VERSION ""

NS_ :

BS_:
BU_: FLR_L FRR_L mADC

BO_ 669 FRR_L_29D: 64 FRR_L
 SG_ FLR_CRCCheck_29D : 503|16@0+ (1.0000000000,0.0000000000) [0.0000000000|65535.0000000000] ""  FLR_L,mADC
 SG_ FLR_RollingCounter_29D : 491|4@0+ (1.0000000000,0.0000000000) [0.0000000000|15.0000000000] ""  FLR_L,mADC
 SG_ FLR_FreespaceSectorKinestate136 : 477|2@0+ (1.0000000000,0.0000000000) [0.0000000000|3.0000000000] "-"  FLR_L,mADC
 SG_ FLR_FreespaceSectorConfidence136 : 479|2@0+ (1.0000000000,0.0000000000) [0.0000000000|3.0000000000] "-"  FLR_L,mADC
 SG_ FLR_FreespaceSectorDistance136 : 457|10@0+ (0.1000000000,0.0000000000) [0.0000000000|100.0000000000] "-"  FLR_L,mADC
 SG_ FLR_FreespaceSectorKinestate135 : 459|2@0+ (1.0000000000,0.0000000000) [0.0000000000|3.0000000000] "-"  FLR_L,mADC
 SG_ FLR_FreespaceSectorConfidence135 : 461|2@0+ (1.0000000000,0.0000000000) [0.0000000000|3.0000000000] "-"  FLR_L,mADC
 SG_ FLR_FreespaceSectorDistance135 : 455|10@0+ (0.1000000000,0.0000000000) [0.0000000000|100.0000000000] "-"  FLR_L,mADC
 SG_ FLR_FreespaceSectorKinestate134 : 441|2@0+ (1.0000000000,0.0000000000) [0.0000000000|3.0000000000] "-"  FLR_L,mADC
 SG_ FLR_FreespaceSectorConfidence134 : 443|2@0+ (1.0000000000,0.0000000000) [0.0000000000|3.0000000000] "-"  FLR_L,mADC
 SG_ FLR_FreespaceSectorDistance134 : 437|10@0+ (0.1000000000,0.0000000000) [0.0000000000|100.0000000000] "-"  FLR_L,mADC
 SG_ FLR_FreespaceSectorKinestate133 : 439|2@0+ (1.0000000000,0.0000000000) [0.0000000000|3.0000000000] "-"  FLR_L,mADC
 SG_ FLR_FreespaceSectorConfidence133 : 425|2@0+ (1.0000000000,0.0000000000) [0.0000000000|3.0000000000] "-"  FLR_L,mADC
 SG_ FLR_FreespaceSectorDistance133 : 419|10@0+ (0.1000000000,0.0000000000) [0.0000000000|100.0000000000] "-"  FLR_L,mADC
 SG_ FLR_FreespaceSectorKinestate132 : 421|2@0+ (1.0000000000,0.0000000000) [0.0000000000|3.0000000000] "-"  FLR_L,mADC
 SG_ FLR_FreespaceSectorConfidence132 : 423|2@0+ (1.0000000000,0.0000000000) [0.0000000000|3.0000000000] "-"  FLR_L,mADC
 SG_ FLR_FreespaceSectorDistance132 : 401|10@0+ (0.1000000000,0.0000000000) [0.0000000000|100.0000000000] "-"  FLR_L,mADC
 SG_ FLR_FreespaceSectorKinestate131 : 403|2@0+ (1.0000000000,0.0000000000) [0.0000000000|3.0000000000] "-"  FLR_L,mADC
 SG_ FLR_FreespaceSectorConfidence131 : 405|2@0+ (1.0000000000,0.0000000000) [0.0000000000|3.0000000000] "-"  FLR_L,mADC
 SG_ FLR_FreespaceSectorDistance131 : 399|10@0+ (0.1000000000,0.0000000000) [0.0000000000|100.0000000000] "-"  FLR_L,mADC
 SG_ FLR_FreespaceSectorKinestate130 : 385|2@0+ (1.0000000000,0.0000000000) [0.0000000000|3.0000000000] "-"  FLR_L,mADC
 SG_ FLR_FreespaceSectorConfidence130 : 387|2@0+ (1.0000000000,0.0000000000) [0.0000000000|3.0000000000] "-"  FLR_L,mADC
 SG_ FLR_FreespaceSectorDistance130 : 381|10@0+ (0.1000000000,0.0000000000) [0.0000000000|100.0000000000] "-"  FLR_L,mADC
 SG_ FLR_FreespaceSectorKinestate129 : 383|2@0+ (1.0000000000,0.0000000000) [0.0000000000|3.0000000000] "-"  FLR_L,mADC
 SG_ FLR_FreespaceSectorConfidence129 : 369|2@0+ (1.0000000000,0.0000000000) [0.0000000000|3.0000000000] "-"  FLR_L,mADC
 SG_ FLR_FreespaceSectorDistance129 : 363|10@0+ (0.1000000000,0.0000000000) [0.0000000000|100.0000000000] "-"  FLR_L,mADC
 SG_ FLR_FreespaceSectorKinestate128 : 365|2@0+ (1.0000000000,0.0000000000) [0.0000000000|3.0000000000] "-"  FLR_L,mADC
 SG_ FLR_FreespaceSectorConfidence128 : 367|2@0+ (1.0000000000,0.0000000000) [0.0000000000|3.0000000000] "-"  FLR_L,mADC
 SG_ FLR_FreespaceSectorDistance128 : 345|10@0+ (0.1000000000,0.0000000000) [0.0000000000|100.0000000000] "-"  FLR_L,mADC
 SG_ FLR_FreespaceSectorKinestate127 : 347|2@0+ (1.0000000000,0.0000000000) [0.0000000000|3.0000000000] "-"  FLR_L,mADC
 SG_ FLR_FreespaceSectorConfidence127 : 349|2@0+ (1.0000000000,0.0000000000) [0.0000000000|3.0000000000] "-"  FLR_L,mADC
 SG_ FLR_FreespaceSectorDistance127 : 343|10@0+ (0.1000000000,0.0000000000) [0.0000000000|100.0000000000] "-"  FLR_L,mADC
 SG_ FLR_FreespaceSectorKinestate126 : 329|2@0+ (1.0000000000,0.0000000000) [0.0000000000|3.0000000000] "-"  FLR_L,mADC
 SG_ FLR_FreespaceSectorConfidence126 : 331|2@0+ (1.0000000000,0.0000000000) [0.0000000000|3.0000000000] "-"  FLR_L,mADC
 SG_ FLR_FreespaceSectorDistance126 : 325|10@0+ (0.1000000000,0.0000000000) [0.0000000000|100.0000000000] "-"  FLR_L,mADC
 SG_ FLR_FreespaceSectorKinestate125 : 327|2@0+ (1.0000000000,0.0000000000) [0.0000000000|3.0000000000] "-"  FLR_L,mADC
 SG_ FLR_FreespaceSectorConfidence125 : 313|2@0+ (1.0000000000,0.0000000000) [0.0000000000|3.0000000000] "-"  FLR_L,mADC
 SG_ FLR_FreespaceSectorDistance125 : 307|10@0+ (0.1000000000,0.0000000000) [0.0000000000|100.0000000000] "-"  FLR_L,mADC
 SG_ FLR_FreespaceSectorKinestate124 : 309|2@0+ (1.0000000000,0.0000000000) [0.0000000000|3.0000000000] "-"  FLR_L,mADC
 SG_ FLR_FreespaceSectorConfidence124 : 311|2@0+ (1.0000000000,0.0000000000) [0.0000000000|3.0000000000] "-"  FLR_L,mADC
 SG_ FLR_FreespaceSectorDistance124 : 289|10@0+ (0.1000000000,0.0000000000) [0.0000000000|100.0000000000] "-"  FLR_L,mADC
 SG_ FLR_FreespaceSectorKinestate123 : 291|2@0+ (1.0000000000,0.0000000000) [0.0000000000|3.0000000000] "-"  FLR_L,mADC
 SG_ FLR_FreespaceSectorConfidence123 : 293|2@0+ (1.0000000000,0.0000000000) [0.0000000000|3.0000000000] "-"  FLR_L,mADC
 SG_ FLR_FreespaceSectorDistance123 : 287|10@0+ (0.1000000000,0.0000000000) [0.0000000000|100.0000000000] "-"  FLR_L,mADC
 SG_ FLR_FreespaceSectorKinestate122 : 273|2@0+ (1.0000000000,0.0000000000) [0.0000000000|3.0000000000] "-"  FLR_L,mADC
 SG_ FLR_FreespaceSectorConfidence122 : 275|2@0+ (1.0000000000,0.0000000000) [0.0000000000|3.0000000000] "-"  FLR_L,mADC
 SG_ FLR_FreespaceSectorDistance122 : 269|10@0+ (0.1000000000,0.0000000000) [0.0000000000|100.0000000000] "-"  FLR_L,mADC
 SG_ FLR_FreespaceSectorKinestate121 : 271|2@0+ (1.0000000000,0.0000000000) [0.0000000000|3.0000000000] "-"  FLR_L,mADC
 SG_ FLR_FreespaceSectorConfidence121 : 257|2@0+ (1.0000000000,0.0000000000) [0.0000000000|3.0000000000] "-"  FLR_L,mADC
 SG_ FLR_FreespaceSectorDistance121 : 251|10@0+ (0.1000000000,0.0000000000) [0.0000000000|100.0000000000] "-"  FLR_L,mADC
 SG_ FLR_FreespaceSectorKinestate120 : 253|2@0+ (1.0000000000,0.0000000000) [0.0000000000|3.0000000000] "-"  FLR_L,mADC
 SG_ FLR_FreespaceSectorConfidence120 : 255|2@0+ (1.0000000000,0.0000000000) [0.0000000000|3.0000000000] "-"  FLR_L,mADC
 SG_ FLR_FreespaceSectorDistance120 : 233|10@0+ (0.1000000000,0.0000000000) [0.0000000000|100.0000000000] "-"  FLR_L,mADC
 SG_ FLR_FreespaceSectorKinestate119 : 235|2@0+ (1.0000000000,0.0000000000) [0.0000000000|3.0000000000] "-"  FLR_L,mADC
 SG_ FLR_FreespaceSectorConfidence119 : 237|2@0+ (1.0000000000,0.0000000000) [0.0000000000|3.0000000000] "-"  FLR_L,mADC
 SG_ FLR_FreespaceSectorDistance119 : 231|10@0+ (0.1000000000,0.0000000000) [0.0000000000|100.0000000000] "-"  FLR_L,mADC
 SG_ FLR_FreespaceSectorKinestate118 : 217|2@0+ (1.0000000000,0.0000000000) [0.0000000000|3.0000000000] "-"  FLR_L,mADC
 SG_ FLR_FreespaceSectorConfidence118 : 219|2@0+ (1.0000000000,0.0000000000) [0.0000000000|3.0000000000] "-"  FLR_L,mADC
 SG_ FLR_FreespaceSectorDistance118 : 213|10@0+ (0.1000000000,0.0000000000) [0.0000000000|100.0000000000] "-"  FLR_L,mADC
 SG_ FLR_FreespaceSectorKinestate117 : 215|2@0+ (1.0000000000,0.0000000000) [0.0000000000|3.0000000000] "-"  FLR_L,mADC
 SG_ FLR_FreespaceSectorConfidence117 : 201|2@0+ (1.0000000000,0.0000000000) [0.0000000000|3.0000000000] "-"  FLR_L,mADC
 SG_ FLR_FreespaceSectorDistance117 : 195|10@0+ (0.1000000000,0.0000000000) [0.0000000000|100.0000000000] "-"  FLR_L,mADC
 SG_ FLR_FreespaceSectorKinestate116 : 197|2@0+ (1.0000000000,0.0000000000) [0.0000000000|3.0000000000] "-"  FLR_L,mADC
 SG_ FLR_FreespaceSectorConfidence116 : 199|2@0+ (1.0000000000,0.0000000000) [0.0000000000|3.0000000000] "-"  FLR_L,mADC
 SG_ FLR_FreespaceSectorDistance116 : 177|10@0+ (0.1000000000,0.0000000000) [0.0000000000|100.0000000000] "-"  FLR_L,mADC
 SG_ FLR_FreespaceSectorKinestate115 : 179|2@0+ (1.0000000000,0.0000000000) [0.0000000000|3.0000000000] "-"  FLR_L,mADC
 SG_ FLR_FreespaceSectorConfidence115 : 181|2@0+ (1.0000000000,0.0000000000) [0.0000000000|3.0000000000] "-"  FLR_L,mADC
 SG_ FLR_FreespaceSectorDistance115 : 175|10@0+ (0.1000000000,0.0000000000) [0.0000000000|100.0000000000] "-"  FLR_L,mADC
 SG_ FLR_FreespaceSectorKinestate114 : 161|2@0+ (1.0000000000,0.0000000000) [0.0000000000|3.0000000000] "-"  FLR_L,mADC
 SG_ FLR_FreespaceSectorConfidence114 : 163|2@0+ (1.0000000000,0.0000000000) [0.0000000000|3.0000000000] "-"  FLR_L,mADC
 SG_ FLR_FreespaceSectorDistance114 : 157|10@0+ (0.1000000000,0.0000000000) [0.0000000000|100.0000000000] "-"  FLR_L,mADC
 SG_ FLR_FreespaceSectorKinestate113 : 159|2@0+ (1.0000000000,0.0000000000) [0.0000000000|3.0000000000] "-"  FLR_L,mADC
 SG_ FLR_FreespaceSectorConfidence113 : 145|2@0+ (1.0000000000,0.0000000000) [0.0000000000|3.0000000000] "-"  FLR_L,mADC
 SG_ FLR_FreespaceSectorDistance113 : 139|10@0+ (0.1000000000,0.0000000000) [0.0000000000|100.0000000000] "-"  FLR_L,mADC
 SG_ FLR_FreespaceSectorKinestate112 : 141|2@0+ (1.0000000000,0.0000000000) [0.0000000000|3.0000000000] "-"  FLR_L,mADC
 SG_ FLR_FreespaceSectorConfidence112 : 143|2@0+ (1.0000000000,0.0000000000) [0.0000000000|3.0000000000] "-"  FLR_L,mADC
 SG_ FLR_FreespaceSectorDistance112 : 121|10@0+ (0.1000000000,0.0000000000) [0.0000000000|100.0000000000] "-"  FLR_L,mADC
 SG_ FLR_FreespaceSectorKinestate111 : 123|2@0+ (1.0000000000,0.0000000000) [0.0000000000|3.0000000000] "-"  FLR_L,mADC
 SG_ FLR_FreespaceSectorConfidence111 : 125|2@0+ (1.0000000000,0.0000000000) [0.0000000000|3.0000000000] "-"  FLR_L,mADC
 SG_ FLR_FreespaceSectorDistance111 : 119|10@0+ (0.1000000000,0.0000000000) [0.0000000000|100.0000000000] "-"  FLR_L,mADC
 SG_ FLR_FreespaceSectorKinestate110 : 105|2@0+ (1.0000000000,0.0000000000) [0.0000000000|3.0000000000] "-"  FLR_L,mADC
 SG_ FLR_FreespaceSectorConfidence110 : 107|2@0+ (1.0000000000,0.0000000000) [0.0000000000|3.0000000000] "-"  FLR_L,mADC
 SG_ FLR_FreespaceSectorDistance110 : 101|10@0+ (0.1000000000,0.0000000000) [0.0000000000|100.0000000000] "-"  FLR_L,mADC
 SG_ FLR_FreespaceSectorKinestate109 : 103|2@0+ (1.0000000000,0.0000000000) [0.0000000000|3.0000000000] "-"  FLR_L,mADC
 SG_ FLR_FreespaceSectorConfidence109 : 89|2@0+ (1.0000000000,0.0000000000) [0.0000000000|3.0000000000] "-"  FLR_L,mADC
 SG_ FLR_FreespaceSectorDistance109 : 83|10@0+ (0.1000000000,0.0000000000) [0.0000000000|100.0000000000] "-"  FLR_L,mADC
 SG_ FLR_FreespaceSectorKinestate108 : 85|2@0+ (1.0000000000,0.0000000000) [0.0000000000|3.0000000000] "-"  FLR_L,mADC
 SG_ FLR_FreespaceSectorConfidence108 : 87|2@0+ (1.0000000000,0.0000000000) [0.0000000000|3.0000000000] "-"  FLR_L,mADC
 SG_ FLR_FreespaceSectorDistance108 : 65|10@0+ (0.1000000000,0.0000000000) [0.0000000000|100.0000000000] "-"  FLR_L,mADC
 SG_ FLR_FreespaceSectorKinestate107 : 67|2@0+ (1.0000000000,0.0000000000) [0.0000000000|3.0000000000] "-"  FLR_L,mADC
 SG_ FLR_FreespaceSectorConfidence107 : 69|2@0+ (1.0000000000,0.0000000000) [0.0000000000|3.0000000000] "-"  FLR_L,mADC
 SG_ FLR_FreespaceSectorDistance107 : 63|10@0+ (0.1000000000,0.0000000000) [0.0000000000|100.0000000000] "-"  FLR_L,mADC
 SG_ FLR_FreespaceSectorKinestate106 : 49|2@0+ (1.0000000000,0.0000000000) [0.0000000000|3.0000000000] "-"  FLR_L,mADC
 SG_ FLR_FreespaceSectorConfidence106 : 51|2@0+ (1.0000000000,0.0000000000) [0.0000000000|3.0000000000] "-"  FLR_L,mADC
 SG_ FLR_FreespaceSectorDistance106 : 45|10@0+ (0.1000000000,0.0000000000) [0.0000000000|100.0000000000] "-"  FLR_L,mADC
 SG_ FLR_FreespaceSectorKinestate105 : 47|2@0+ (1.0000000000,0.0000000000) [0.0000000000|3.0000000000] "-"  FLR_L,mADC
 SG_ FLR_FreespaceSectorConfidence105 : 33|2@0+ (1.0000000000,0.0000000000) [0.0000000000|3.0000000000] "-"  FLR_L,mADC
 SG_ FLR_FreespaceSectorDistance105 : 27|10@0+ (0.1000000000,0.0000000000) [0.0000000000|100.0000000000] "-"  FLR_L,mADC
 SG_ FLR_FreespaceSectorKinestate104 : 29|2@0+ (1.0000000000,0.0000000000) [0.0000000000|3.0000000000] "-"  FLR_L,mADC
 SG_ FLR_FreespaceSectorConfidence104 : 31|2@0+ (1.0000000000,0.0000000000) [0.0000000000|3.0000000000] "-"  FLR_L,mADC
 SG_ FLR_FreespaceSectorDistance104 : 9|10@0+ (0.1000000000,0.0000000000) [0.0000000000|100.0000000000] "-"  FLR_L,mADC
 SG_ FLR_FreespaceSectorKinestate103 : 11|2@0+ (1.0000000000,0.0000000000) [0.0000000000|3.0000000000] "-"  FLR_L,mADC
 SG_ FLR_FreespaceSectorConfidence103 : 13|2@0+ (1.0000000000,0.0000000000) [0.0000000000|3.0000000000] "-"  FLR_L,mADC
 SG_ FLR_FreespaceSectorDistance103 : 7|10@0+ (0.1000000000,0.0000000000) [0.0000000000|100.0000000000] "-"  FLR_L,mADC

BO_ 670 FRR_L_29E: 64 FRR_L
 SG_ FLR_CRCCheck_29E : 503|16@0+ (1.0000000000,0.0000000000) [0.0000000000|65535.0000000000] ""  FLR_L,mADC
 SG_ FLR_RollingCounter_29E : 491|4@0+ (1.0000000000,0.0000000000) [0.0000000000|15.0000000000] ""  FLR_L,mADC
 SG_ FLR_FreespaceSectorKinestate170 : 477|2@0+ (1.0000000000,0.0000000000) [0.0000000000|3.0000000000] "-"  FLR_L,mADC
 SG_ FLR_FreespaceSectorConfidence170 : 479|2@0+ (1.0000000000,0.0000000000) [0.0000000000|3.0000000000] "-"  FLR_L,mADC
 SG_ FLR_FreespaceSectorDistance170 : 457|10@0+ (0.1000000000,0.0000000000) [0.0000000000|100.0000000000] "-"  FLR_L,mADC
 SG_ FLR_FreespaceSectorKinestate169 : 459|2@0+ (1.0000000000,0.0000000000) [0.0000000000|3.0000000000] "-"  FLR_L,mADC
 SG_ FLR_FreespaceSectorConfidence169 : 461|2@0+ (1.0000000000,0.0000000000) [0.0000000000|3.0000000000] "-"  FLR_L,mADC
 SG_ FLR_FreespaceSectorDistance169 : 455|10@0+ (0.1000000000,0.0000000000) [0.0000000000|100.0000000000] "-"  FLR_L,mADC
 SG_ FLR_FreespaceSectorKinestate168 : 441|2@0+ (1.0000000000,0.0000000000) [0.0000000000|3.0000000000] "-"  FLR_L,mADC
 SG_ FLR_FreespaceSectorConfidence168 : 443|2@0+ (1.0000000000,0.0000000000) [0.0000000000|3.0000000000] "-"  FLR_L,mADC
 SG_ FLR_FreespaceSectorDistance168 : 437|10@0+ (0.1000000000,0.0000000000) [0.0000000000|100.0000000000] "-"  FLR_L,mADC
 SG_ FLR_FreespaceSectorKinestate167 : 439|2@0+ (1.0000000000,0.0000000000) [0.0000000000|3.0000000000] "-"  FLR_L,mADC
 SG_ FLR_FreespaceSectorConfidence167 : 425|2@0+ (1.0000000000,0.0000000000) [0.0000000000|3.0000000000] "-"  FLR_L,mADC
 SG_ FLR_FreespaceSectorDistance167 : 419|10@0+ (0.1000000000,0.0000000000) [0.0000000000|100.0000000000] "-"  FLR_L,mADC
 SG_ FLR_FreespaceSectorKinestate166 : 421|2@0+ (1.0000000000,0.0000000000) [0.0000000000|3.0000000000] "-"  FLR_L,mADC
 SG_ FLR_FreespaceSectorConfidence166 : 423|2@0+ (1.0000000000,0.0000000000) [0.0000000000|3.0000000000] "-"  FLR_L,mADC
 SG_ FLR_FreespaceSectorDistance166 : 401|10@0+ (0.1000000000,0.0000000000) [0.0000000000|100.0000000000] "-"  FLR_L,mADC
 SG_ FLR_FreespaceSectorKinestate165 : 403|2@0+ (1.0000000000,0.0000000000) [0.0000000000|3.0000000000] "-"  FLR_L,mADC
 SG_ FLR_FreespaceSectorConfidence165 : 405|2@0+ (1.0000000000,0.0000000000) [0.0000000000|3.0000000000] "-"  FLR_L,mADC
 SG_ FLR_FreespaceSectorDistance165 : 399|10@0+ (0.1000000000,0.0000000000) [0.0000000000|100.0000000000] "-"  FLR_L,mADC
 SG_ FLR_FreespaceSectorKinestate164 : 385|2@0+ (1.0000000000,0.0000000000) [0.0000000000|3.0000000000] "-"  FLR_L,mADC
 SG_ FLR_FreespaceSectorConfidence164 : 387|2@0+ (1.0000000000,0.0000000000) [0.0000000000|3.0000000000] "-"  FLR_L,mADC
 SG_ FLR_FreespaceSectorDistance164 : 381|10@0+ (0.1000000000,0.0000000000) [0.0000000000|100.0000000000] "-"  FLR_L,mADC
 SG_ FLR_FreespaceSectorKinestate163 : 383|2@0+ (1.0000000000,0.0000000000) [0.0000000000|3.0000000000] "-"  FLR_L,mADC
 SG_ FLR_FreespaceSectorConfidence163 : 369|2@0+ (1.0000000000,0.0000000000) [0.0000000000|3.0000000000] "-"  FLR_L,mADC
 SG_ FLR_FreespaceSectorDistance163 : 363|10@0+ (0.1000000000,0.0000000000) [0.0000000000|100.0000000000] "-"  FLR_L,mADC
 SG_ FLR_FreespaceSectorKinestate162 : 365|2@0+ (1.0000000000,0.0000000000) [0.0000000000|3.0000000000] "-"  FLR_L,mADC
 SG_ FLR_FreespaceSectorConfidence162 : 367|2@0+ (1.0000000000,0.0000000000) [0.0000000000|3.0000000000] "-"  FLR_L,mADC
 SG_ FLR_FreespaceSectorDistance162 : 345|10@0+ (0.1000000000,0.0000000000) [0.0000000000|100.0000000000] "-"  FLR_L,mADC
 SG_ FLR_FreespaceSectorKinestate161 : 347|2@0+ (1.0000000000,0.0000000000) [0.0000000000|3.0000000000] "-"  FLR_L,mADC
 SG_ FLR_FreespaceSectorConfidence161 : 349|2@0+ (1.0000000000,0.0000000000) [0.0000000000|3.0000000000] "-"  FLR_L,mADC
 SG_ FLR_FreespaceSectorDistance161 : 343|10@0+ (0.1000000000,0.0000000000) [0.0000000000|100.0000000000] "-"  FLR_L,mADC
 SG_ FLR_FreespaceSectorKinestate160 : 329|2@0+ (1.0000000000,0.0000000000) [0.0000000000|3.0000000000] "-"  FLR_L,mADC
 SG_ FLR_FreespaceSectorConfidence160 : 331|2@0+ (1.0000000000,0.0000000000) [0.0000000000|3.0000000000] "-"  FLR_L,mADC
 SG_ FLR_FreespaceSectorDistance160 : 325|10@0+ (0.1000000000,0.0000000000) [0.0000000000|100.0000000000] "-"  FLR_L,mADC
 SG_ FLR_FreespaceSectorKinestate159 : 327|2@0+ (1.0000000000,0.0000000000) [0.0000000000|3.0000000000] "-"  FLR_L,mADC
 SG_ FLR_FreespaceSectorConfidence159 : 313|2@0+ (1.0000000000,0.0000000000) [0.0000000000|3.0000000000] "-"  FLR_L,mADC
 SG_ FLR_FreespaceSectorDistance159 : 307|10@0+ (0.1000000000,0.0000000000) [0.0000000000|100.0000000000] "-"  FLR_L,mADC
 SG_ FLR_FreespaceSectorKinestate158 : 309|2@0+ (1.0000000000,0.0000000000) [0.0000000000|3.0000000000] "-"  FLR_L,mADC
 SG_ FLR_FreespaceSectorConfidence158 : 311|2@0+ (1.0000000000,0.0000000000) [0.0000000000|3.0000000000] "-"  FLR_L,mADC
 SG_ FLR_FreespaceSectorDistance158 : 289|10@0+ (0.1000000000,0.0000000000) [0.0000000000|100.0000000000] "-"  FLR_L,mADC
 SG_ FLR_FreespaceSectorKinestate157 : 291|2@0+ (1.0000000000,0.0000000000) [0.0000000000|3.0000000000] "-"  FLR_L,mADC
 SG_ FLR_FreespaceSectorConfidence157 : 293|2@0+ (1.0000000000,0.0000000000) [0.0000000000|3.0000000000] "-"  FLR_L,mADC
 SG_ FLR_FreespaceSectorDistance157 : 287|10@0+ (0.1000000000,0.0000000000) [0.0000000000|100.0000000000] "-"  FLR_L,mADC
 SG_ FLR_FreespaceSectorKinestate156 : 273|2@0+ (1.0000000000,0.0000000000) [0.0000000000|3.0000000000] "-"  FLR_L,mADC
 SG_ FLR_FreespaceSectorConfidence156 : 275|2@0+ (1.0000000000,0.0000000000) [0.0000000000|3.0000000000] "-"  FLR_L,mADC
 SG_ FLR_FreespaceSectorDistance156 : 269|10@0+ (0.1000000000,0.0000000000) [0.0000000000|100.0000000000] "-"  FLR_L,mADC
 SG_ FLR_FreespaceSectorKinestate155 : 271|2@0+ (1.0000000000,0.0000000000) [0.0000000000|3.0000000000] "-"  FLR_L,mADC
 SG_ FLR_FreespaceSectorConfidence155 : 257|2@0+ (1.0000000000,0.0000000000) [0.0000000000|3.0000000000] "-"  FLR_L,mADC
 SG_ FLR_FreespaceSectorDistance155 : 251|10@0+ (0.1000000000,0.0000000000) [0.0000000000|100.0000000000] "-"  FLR_L,mADC
 SG_ FLR_FreespaceSectorKinestate154 : 253|2@0+ (1.0000000000,0.0000000000) [0.0000000000|3.0000000000] "-"  FLR_L,mADC
 SG_ FLR_FreespaceSectorConfidence154 : 255|2@0+ (1.0000000000,0.0000000000) [0.0000000000|3.0000000000] "-"  FLR_L,mADC
 SG_ FLR_FreespaceSectorDistance154 : 233|10@0+ (0.1000000000,0.0000000000) [0.0000000000|100.0000000000] "-"  FLR_L,mADC
 SG_ FLR_FreespaceSectorKinestate153 : 235|2@0+ (1.0000000000,0.0000000000) [0.0000000000|3.0000000000] "-"  FLR_L,mADC
 SG_ FLR_FreespaceSectorConfidence153 : 237|2@0+ (1.0000000000,0.0000000000) [0.0000000000|3.0000000000] "-"  FLR_L,mADC
 SG_ FLR_FreespaceSectorDistance153 : 231|10@0+ (0.1000000000,0.0000000000) [0.0000000000|100.0000000000] "-"  FLR_L,mADC
 SG_ FLR_FreespaceSectorKinestate152 : 217|2@0+ (1.0000000000,0.0000000000) [0.0000000000|3.0000000000] "-"  FLR_L,mADC
 SG_ FLR_FreespaceSectorConfidence152 : 219|2@0+ (1.0000000000,0.0000000000) [0.0000000000|3.0000000000] "-"  FLR_L,mADC
 SG_ FLR_FreespaceSectorDistance152 : 213|10@0+ (0.1000000000,0.0000000000) [0.0000000000|100.0000000000] "-"  FLR_L,mADC
 SG_ FLR_FreespaceSectorKinestate151 : 215|2@0+ (1.0000000000,0.0000000000) [0.0000000000|3.0000000000] "-"  FLR_L,mADC
 SG_ FLR_FreespaceSectorConfidence151 : 201|2@0+ (1.0000000000,0.0000000000) [0.0000000000|3.0000000000] "-"  FLR_L,mADC
 SG_ FLR_FreespaceSectorDistance151 : 195|10@0+ (0.1000000000,0.0000000000) [0.0000000000|100.0000000000] "-"  FLR_L,mADC
 SG_ FLR_FreespaceSectorKinestate150 : 197|2@0+ (1.0000000000,0.0000000000) [0.0000000000|3.0000000000] "-"  FLR_L,mADC
 SG_ FLR_FreespaceSectorConfidence150 : 199|2@0+ (1.0000000000,0.0000000000) [0.0000000000|3.0000000000] "-"  FLR_L,mADC
 SG_ FLR_FreespaceSectorDistance150 : 177|10@0+ (0.1000000000,0.0000000000) [0.0000000000|100.0000000000] "-"  FLR_L,mADC
 SG_ FLR_FreespaceSectorKinestate149 : 179|2@0+ (1.0000000000,0.0000000000) [0.0000000000|3.0000000000] "-"  FLR_L,mADC
 SG_ FLR_FreespaceSectorConfidence149 : 181|2@0+ (1.0000000000,0.0000000000) [0.0000000000|3.0000000000] "-"  FLR_L,mADC
 SG_ FLR_FreespaceSectorDistance149 : 175|10@0+ (0.1000000000,0.0000000000) [0.0000000000|100.0000000000] "-"  FLR_L,mADC
 SG_ FLR_FreespaceSectorKinestate148 : 161|2@0+ (1.0000000000,0.0000000000) [0.0000000000|3.0000000000] "-"  FLR_L,mADC
 SG_ FLR_FreespaceSectorConfidence148 : 163|2@0+ (1.0000000000,0.0000000000) [0.0000000000|3.0000000000] "-"  FLR_L,mADC
 SG_ FLR_FreespaceSectorDistance148 : 157|10@0+ (0.1000000000,0.0000000000) [0.0000000000|100.0000000000] "-"  FLR_L,mADC
 SG_ FLR_FreespaceSectorKinestate147 : 159|2@0+ (1.0000000000,0.0000000000) [0.0000000000|3.0000000000] "-"  FLR_L,mADC
 SG_ FLR_FreespaceSectorConfidence147 : 145|2@0+ (1.0000000000,0.0000000000) [0.0000000000|3.0000000000] "-"  FLR_L,mADC
 SG_ FLR_FreespaceSectorDistance147 : 139|10@0+ (0.1000000000,0.0000000000) [0.0000000000|100.0000000000] "-"  FLR_L,mADC
 SG_ FLR_FreespaceSectorKinestate146 : 141|2@0+ (1.0000000000,0.0000000000) [0.0000000000|3.0000000000] "-"  FLR_L,mADC
 SG_ FLR_FreespaceSectorConfidence146 : 143|2@0+ (1.0000000000,0.0000000000) [0.0000000000|3.0000000000] "-"  FLR_L,mADC
 SG_ FLR_FreespaceSectorDistance146 : 121|10@0+ (0.1000000000,0.0000000000) [0.0000000000|100.0000000000] "-"  FLR_L,mADC
 SG_ FLR_FreespaceSectorKinestate145 : 123|2@0+ (1.0000000000,0.0000000000) [0.0000000000|3.0000000000] "-"  FLR_L,mADC
 SG_ FLR_FreespaceSectorConfidence145 : 125|2@0+ (1.0000000000,0.0000000000) [0.0000000000|3.0000000000] "-"  FLR_L,mADC
 SG_ FLR_FreespaceSectorDistance145 : 119|10@0+ (0.1000000000,0.0000000000) [0.0000000000|100.0000000000] "-"  FLR_L,mADC
 SG_ FLR_FreespaceSectorKinestate144 : 105|2@0+ (1.0000000000,0.0000000000) [0.0000000000|3.0000000000] "-"  FLR_L,mADC
 SG_ FLR_FreespaceSectorConfidence144 : 107|2@0+ (1.0000000000,0.0000000000) [0.0000000000|3.0000000000] "-"  FLR_L,mADC
 SG_ FLR_FreespaceSectorDistance144 : 101|10@0+ (0.1000000000,0.0000000000) [0.0000000000|100.0000000000] "-"  FLR_L,mADC
 SG_ FLR_FreespaceSectorKinestate143 : 103|2@0+ (1.0000000000,0.0000000000) [0.0000000000|3.0000000000] "-"  FLR_L,mADC
 SG_ FLR_FreespaceSectorConfidence143 : 89|2@0+ (1.0000000000,0.0000000000) [0.0000000000|3.0000000000] "-"  FLR_L,mADC
 SG_ FLR_FreespaceSectorDistance143 : 83|10@0+ (0.1000000000,0.0000000000) [0.0000000000|100.0000000000] "-"  FLR_L,mADC
 SG_ FLR_FreespaceSectorKinestate142 : 85|2@0+ (1.0000000000,0.0000000000) [0.0000000000|3.0000000000] "-"  FLR_L,mADC
 SG_ FLR_FreespaceSectorConfidence142 : 87|2@0+ (1.0000000000,0.0000000000) [0.0000000000|3.0000000000] "-"  FLR_L,mADC
 SG_ FLR_FreespaceSectorDistance142 : 65|10@0+ (0.1000000000,0.0000000000) [0.0000000000|100.0000000000] "-"  FLR_L,mADC
 SG_ FLR_FreespaceSectorKinestate141 : 67|2@0+ (1.0000000000,0.0000000000) [0.0000000000|3.0000000000] "-"  FLR_L,mADC
 SG_ FLR_FreespaceSectorConfidence141 : 69|2@0+ (1.0000000000,0.0000000000) [0.0000000000|3.0000000000] "-"  FLR_L,mADC
 SG_ FLR_FreespaceSectorDistance141 : 63|10@0+ (0.1000000000,0.0000000000) [0.0000000000|100.0000000000] "-"  FLR_L,mADC
 SG_ FLR_FreespaceSectorKinestate140 : 49|2@0+ (1.0000000000,0.0000000000) [0.0000000000|3.0000000000] "-"  FLR_L,mADC
 SG_ FLR_FreespaceSectorConfidence140 : 51|2@0+ (1.0000000000,0.0000000000) [0.0000000000|3.0000000000] "-"  FLR_L,mADC
 SG_ FLR_FreespaceSectorDistance140 : 45|10@0+ (0.1000000000,0.0000000000) [0.0000000000|100.0000000000] "-"  FLR_L,mADC
 SG_ FLR_FreespaceSectorKinestate139 : 47|2@0+ (1.0000000000,0.0000000000) [0.0000000000|3.0000000000] "-"  FLR_L,mADC
 SG_ FLR_FreespaceSectorConfidence139 : 33|2@0+ (1.0000000000,0.0000000000) [0.0000000000|3.0000000000] "-"  FLR_L,mADC
 SG_ FLR_FreespaceSectorDistance139 : 27|10@0+ (0.1000000000,0.0000000000) [0.0000000000|100.0000000000] "-"  FLR_L,mADC
 SG_ FLR_FreespaceSectorKinestate138 : 29|2@0+ (1.0000000000,0.0000000000) [0.0000000000|3.0000000000] "-"  FLR_L,mADC
 SG_ FLR_FreespaceSectorConfidence138 : 31|2@0+ (1.0000000000,0.0000000000) [0.0000000000|3.0000000000] "-"  FLR_L,mADC
 SG_ FLR_FreespaceSectorDistance138 : 9|10@0+ (0.1000000000,0.0000000000) [0.0000000000|100.0000000000] "-"  FLR_L,mADC
 SG_ FLR_FreespaceSectorKinestate137 : 11|2@0+ (1.0000000000,0.0000000000) [0.0000000000|3.0000000000] "-"  FLR_L,mADC
 SG_ FLR_FreespaceSectorConfidence137 : 13|2@0+ (1.0000000000,0.0000000000) [0.0000000000|3.0000000000] "-"  FLR_L,mADC
 SG_ FLR_FreespaceSectorDistance137 : 7|10@0+ (0.1000000000,0.0000000000) [0.0000000000|100.0000000000] "-"  FLR_L,mADC

BO_ 671 FRR_L_29F: 64 FRR_L
 SG_ FLR_CRCCheck_29F : 503|16@0+ (1.0000000000,0.0000000000) [0.0000000000|65535.0000000000] ""  FLR_L,mADC
 SG_ FLR_RollingCounter_29F : 491|4@0+ (1.0000000000,0.0000000000) [0.0000000000|15.0000000000] ""  FLR_L,mADC
 SG_ FLR_FreespaceSectorKinestate204 : 477|2@0+ (1.0000000000,0.0000000000) [0.0000000000|3.0000000000] "-"  FLR_L,mADC
 SG_ FLR_FreespaceSectorConfidence204 : 479|2@0+ (1.0000000000,0.0000000000) [0.0000000000|3.0000000000] "-"  FLR_L,mADC
 SG_ FLR_FreespaceSectorDistance204 : 457|10@0+ (0.1000000000,0.0000000000) [0.0000000000|100.0000000000] "-"  FLR_L,mADC
 SG_ FLR_FreespaceSectorKinestate203 : 459|2@0+ (1.0000000000,0.0000000000) [0.0000000000|3.0000000000] "-"  FLR_L,mADC
 SG_ FLR_FreespaceSectorConfidence203 : 461|2@0+ (1.0000000000,0.0000000000) [0.0000000000|3.0000000000] "-"  FLR_L,mADC
 SG_ FLR_FreespaceSectorDistance203 : 455|10@0+ (0.1000000000,0.0000000000) [0.0000000000|100.0000000000] "-"  FLR_L,mADC
 SG_ FLR_FreespaceSectorKinestate202 : 441|2@0+ (1.0000000000,0.0000000000) [0.0000000000|3.0000000000] "-"  FLR_L,mADC
 SG_ FLR_FreespaceSectorConfidence202 : 443|2@0+ (1.0000000000,0.0000000000) [0.0000000000|3.0000000000] "-"  FLR_L,mADC
 SG_ FLR_FreespaceSectorDistance202 : 437|10@0+ (0.1000000000,0.0000000000) [0.0000000000|100.0000000000] "-"  FLR_L,mADC
 SG_ FLR_FreespaceSectorKinestate201 : 439|2@0+ (1.0000000000,0.0000000000) [0.0000000000|3.0000000000] "-"  FLR_L,mADC
 SG_ FLR_FreespaceSectorConfidence201 : 425|2@0+ (1.0000000000,0.0000000000) [0.0000000000|3.0000000000] "-"  FLR_L,mADC
 SG_ FLR_FreespaceSectorDistance201 : 419|10@0+ (0.1000000000,0.0000000000) [0.0000000000|100.0000000000] "-"  FLR_L,mADC
 SG_ FLR_FreespaceSectorKinestate200 : 421|2@0+ (1.0000000000,0.0000000000) [0.0000000000|3.0000000000] "-"  FLR_L,mADC
 SG_ FLR_FreespaceSectorConfidence200 : 423|2@0+ (1.0000000000,0.0000000000) [0.0000000000|3.0000000000] "-"  FLR_L,mADC
 SG_ FLR_FreespaceSectorDistance200 : 401|10@0+ (0.1000000000,0.0000000000) [0.0000000000|100.0000000000] "-"  FLR_L,mADC
 SG_ FLR_FreespaceSectorKinestate199 : 403|2@0+ (1.0000000000,0.0000000000) [0.0000000000|3.0000000000] "-"  FLR_L,mADC
 SG_ FLR_FreespaceSectorConfidence199 : 405|2@0+ (1.0000000000,0.0000000000) [0.0000000000|3.0000000000] "-"  FLR_L,mADC
 SG_ FLR_FreespaceSectorDistance199 : 399|10@0+ (0.1000000000,0.0000000000) [0.0000000000|100.0000000000] "-"  FLR_L,mADC
 SG_ FLR_FreespaceSectorKinestate198 : 385|2@0+ (1.0000000000,0.0000000000) [0.0000000000|3.0000000000] "-"  FLR_L,mADC
 SG_ FLR_FreespaceSectorConfidence198 : 387|2@0+ (1.0000000000,0.0000000000) [0.0000000000|3.0000000000] "-"  FLR_L,mADC
 SG_ FLR_FreespaceSectorDistance198 : 381|10@0+ (0.1000000000,0.0000000000) [0.0000000000|100.0000000000] "-"  FLR_L,mADC
 SG_ FLR_FreespaceSectorKinestate197 : 383|2@0+ (1.0000000000,0.0000000000) [0.0000000000|3.0000000000] "-"  FLR_L,mADC
 SG_ FLR_FreespaceSectorConfidence197 : 369|2@0+ (1.0000000000,0.0000000000) [0.0000000000|3.0000000000] "-"  FLR_L,mADC
 SG_ FLR_FreespaceSectorDistance197 : 363|10@0+ (0.1000000000,0.0000000000) [0.0000000000|100.0000000000] "-"  FLR_L,mADC
 SG_ FLR_FreespaceSectorKinestate196 : 365|2@0+ (1.0000000000,0.0000000000) [0.0000000000|3.0000000000] "-"  FLR_L,mADC
 SG_ FLR_FreespaceSectorConfidence196 : 367|2@0+ (1.0000000000,0.0000000000) [0.0000000000|3.0000000000] "-"  FLR_L,mADC
 SG_ FLR_FreespaceSectorDistance196 : 345|10@0+ (0.1000000000,0.0000000000) [0.0000000000|100.0000000000] "-"  FLR_L,mADC
 SG_ FLR_FreespaceSectorKinestate195 : 347|2@0+ (1.0000000000,0.0000000000) [0.0000000000|3.0000000000] "-"  FLR_L,mADC
 SG_ FLR_FreespaceSectorConfidence195 : 349|2@0+ (1.0000000000,0.0000000000) [0.0000000000|3.0000000000] "-"  FLR_L,mADC
 SG_ FLR_FreespaceSectorDistance195 : 343|10@0+ (0.1000000000,0.0000000000) [0.0000000000|100.0000000000] "-"  FLR_L,mADC
 SG_ FLR_FreespaceSectorKinestate194 : 329|2@0+ (1.0000000000,0.0000000000) [0.0000000000|3.0000000000] "-"  FLR_L,mADC
 SG_ FLR_FreespaceSectorConfidence194 : 331|2@0+ (1.0000000000,0.0000000000) [0.0000000000|3.0000000000] "-"  FLR_L,mADC
 SG_ FLR_FreespaceSectorDistance194 : 325|10@0+ (0.1000000000,0.0000000000) [0.0000000000|100.0000000000] "-"  FLR_L,mADC
 SG_ FLR_FreespaceSectorKinestate193 : 327|2@0+ (1.0000000000,0.0000000000) [0.0000000000|3.0000000000] "-"  FLR_L,mADC
 SG_ FLR_FreespaceSectorConfidence193 : 313|2@0+ (1.0000000000,0.0000000000) [0.0000000000|3.0000000000] "-"  FLR_L,mADC
 SG_ FLR_FreespaceSectorDistance193 : 307|10@0+ (0.1000000000,0.0000000000) [0.0000000000|100.0000000000] "-"  FLR_L,mADC
 SG_ FLR_FreespaceSectorKinestate192 : 309|2@0+ (1.0000000000,0.0000000000) [0.0000000000|3.0000000000] "-"  FLR_L,mADC
 SG_ FLR_FreespaceSectorConfidence192 : 311|2@0+ (1.0000000000,0.0000000000) [0.0000000000|3.0000000000] "-"  FLR_L,mADC
 SG_ FLR_FreespaceSectorDistance192 : 289|10@0+ (0.1000000000,0.0000000000) [0.0000000000|100.0000000000] "-"  FLR_L,mADC
 SG_ FLR_FreespaceSectorKinestate191 : 291|2@0+ (1.0000000000,0.0000000000) [0.0000000000|3.0000000000] "-"  FLR_L,mADC
 SG_ FLR_FreespaceSectorConfidence191 : 293|2@0+ (1.0000000000,0.0000000000) [0.0000000000|3.0000000000] "-"  FLR_L,mADC
 SG_ FLR_FreespaceSectorDistance191 : 287|10@0+ (0.1000000000,0.0000000000) [0.0000000000|100.0000000000] "-"  FLR_L,mADC
 SG_ FLR_FreespaceSectorKinestate190 : 273|2@0+ (1.0000000000,0.0000000000) [0.0000000000|3.0000000000] "-"  FLR_L,mADC
 SG_ FLR_FreespaceSectorConfidence190 : 275|2@0+ (1.0000000000,0.0000000000) [0.0000000000|3.0000000000] "-"  FLR_L,mADC
 SG_ FLR_FreespaceSectorDistance190 : 269|10@0+ (0.1000000000,0.0000000000) [0.0000000000|100.0000000000] "-"  FLR_L,mADC
 SG_ FLR_FreespaceSectorKinestate189 : 271|2@0+ (1.0000000000,0.0000000000) [0.0000000000|3.0000000000] "-"  FLR_L,mADC
 SG_ FLR_FreespaceSectorConfidence189 : 257|2@0+ (1.0000000000,0.0000000000) [0.0000000000|3.0000000000] "-"  FLR_L,mADC
 SG_ FLR_FreespaceSectorDistance189 : 251|10@0+ (0.1000000000,0.0000000000) [0.0000000000|100.0000000000] "-"  FLR_L,mADC
 SG_ FLR_FreespaceSectorKinestate188 : 253|2@0+ (1.0000000000,0.0000000000) [0.0000000000|3.0000000000] "-"  FLR_L,mADC
 SG_ FLR_FreespaceSectorConfidence188 : 255|2@0+ (1.0000000000,0.0000000000) [0.0000000000|3.0000000000] "-"  FLR_L,mADC
 SG_ FLR_FreespaceSectorDistance188 : 233|10@0+ (0.1000000000,0.0000000000) [0.0000000000|100.0000000000] "-"  FLR_L,mADC
 SG_ FLR_FreespaceSectorKinestate187 : 235|2@0+ (1.0000000000,0.0000000000) [0.0000000000|3.0000000000] "-"  FLR_L,mADC
 SG_ FLR_FreespaceSectorConfidence187 : 237|2@0+ (1.0000000000,0.0000000000) [0.0000000000|3.0000000000] "-"  FLR_L,mADC
 SG_ FLR_FreespaceSectorDistance187 : 231|10@0+ (0.1000000000,0.0000000000) [0.0000000000|100.0000000000] "-"  FLR_L,mADC
 SG_ FLR_FreespaceSectorKinestate186 : 217|2@0+ (1.0000000000,0.0000000000) [0.0000000000|3.0000000000] "-"  FLR_L,mADC
 SG_ FLR_FreespaceSectorConfidence186 : 219|2@0+ (1.0000000000,0.0000000000) [0.0000000000|3.0000000000] "-"  FLR_L,mADC
 SG_ FLR_FreespaceSectorDistance186 : 213|10@0+ (0.1000000000,0.0000000000) [0.0000000000|100.0000000000] "-"  FLR_L,mADC
 SG_ FLR_FreespaceSectorKinestate185 : 215|2@0+ (1.0000000000,0.0000000000) [0.0000000000|3.0000000000] "-"  FLR_L,mADC
 SG_ FLR_FreespaceSectorConfidence185 : 201|2@0+ (1.0000000000,0.0000000000) [0.0000000000|3.0000000000] "-"  FLR_L,mADC
 SG_ FLR_FreespaceSectorDistance185 : 195|10@0+ (0.1000000000,0.0000000000) [0.0000000000|100.0000000000] "-"  FLR_L,mADC
 SG_ FLR_FreespaceSectorKinestate184 : 197|2@0+ (1.0000000000,0.0000000000) [0.0000000000|3.0000000000] "-"  FLR_L,mADC
 SG_ FLR_FreespaceSectorConfidence184 : 199|2@0+ (1.0000000000,0.0000000000) [0.0000000000|3.0000000000] "-"  FLR_L,mADC
 SG_ FLR_FreespaceSectorDistance184 : 177|10@0+ (0.1000000000,0.0000000000) [0.0000000000|100.0000000000] "-"  FLR_L,mADC
 SG_ FLR_FreespaceSectorKinestate183 : 179|2@0+ (1.0000000000,0.0000000000) [0.0000000000|3.0000000000] "-"  FLR_L,mADC
 SG_ FLR_FreespaceSectorConfidence183 : 181|2@0+ (1.0000000000,0.0000000000) [0.0000000000|3.0000000000] "-"  FLR_L,mADC
 SG_ FLR_FreespaceSectorDistance183 : 175|10@0+ (0.1000000000,0.0000000000) [0.0000000000|100.0000000000] "-"  FLR_L,mADC
 SG_ FLR_FreespaceSectorKinestate182 : 161|2@0+ (1.0000000000,0.0000000000) [0.0000000000|3.0000000000] "-"  FLR_L,mADC
 SG_ FLR_FreespaceSectorConfidence182 : 163|2@0+ (1.0000000000,0.0000000000) [0.0000000000|3.0000000000] "-"  FLR_L,mADC
 SG_ FLR_FreespaceSectorDistance182 : 157|10@0+ (0.1000000000,0.0000000000) [0.0000000000|100.0000000000] "-"  FLR_L,mADC
 SG_ FLR_FreespaceSectorKinestate181 : 159|2@0+ (1.0000000000,0.0000000000) [0.0000000000|3.0000000000] "-"  FLR_L,mADC
 SG_ FLR_FreespaceSectorConfidence181 : 145|2@0+ (1.0000000000,0.0000000000) [0.0000000000|3.0000000000] "-"  FLR_L,mADC
 SG_ FLR_FreespaceSectorDistance181 : 139|10@0+ (0.1000000000,0.0000000000) [0.0000000000|100.0000000000] "-"  FLR_L,mADC
 SG_ FLR_FreespaceSectorKinestate180 : 141|2@0+ (1.0000000000,0.0000000000) [0.0000000000|3.0000000000] "-"  FLR_L,mADC
 SG_ FLR_FreespaceSectorConfidence180 : 143|2@0+ (1.0000000000,0.0000000000) [0.0000000000|3.0000000000] "-"  FLR_L,mADC
 SG_ FLR_FreespaceSectorDistance180 : 121|10@0+ (0.1000000000,0.0000000000) [0.0000000000|100.0000000000] "-"  FLR_L,mADC
 SG_ FLR_FreespaceSectorKinestate179 : 123|2@0+ (1.0000000000,0.0000000000) [0.0000000000|3.0000000000] "-"  FLR_L,mADC
 SG_ FLR_FreespaceSectorConfidence179 : 125|2@0+ (1.0000000000,0.0000000000) [0.0000000000|3.0000000000] "-"  FLR_L,mADC
 SG_ FLR_FreespaceSectorDistance179 : 119|10@0+ (0.1000000000,0.0000000000) [0.0000000000|100.0000000000] "-"  FLR_L,mADC
 SG_ FLR_FreespaceSectorKinestate178 : 105|2@0+ (1.0000000000,0.0000000000) [0.0000000000|3.0000000000] "-"  FLR_L,mADC
 SG_ FLR_FreespaceSectorConfidence178 : 107|2@0+ (1.0000000000,0.0000000000) [0.0000000000|3.0000000000] "-"  FLR_L,mADC
 SG_ FLR_FreespaceSectorDistance178 : 101|10@0+ (0.1000000000,0.0000000000) [0.0000000000|100.0000000000] "-"  FLR_L,mADC
 SG_ FLR_FreespaceSectorKinestate177 : 103|2@0+ (1.0000000000,0.0000000000) [0.0000000000|3.0000000000] "-"  FLR_L,mADC
 SG_ FLR_FreespaceSectorConfidence177 : 89|2@0+ (1.0000000000,0.0000000000) [0.0000000000|3.0000000000] "-"  FLR_L,mADC
 SG_ FLR_FreespaceSectorDistance177 : 83|10@0+ (0.1000000000,0.0000000000) [0.0000000000|100.0000000000] "-"  FLR_L,mADC
 SG_ FLR_FreespaceSectorKinestate176 : 85|2@0+ (1.0000000000,0.0000000000) [0.0000000000|3.0000000000] "-"  FLR_L,mADC
 SG_ FLR_FreespaceSectorConfidence176 : 87|2@0+ (1.0000000000,0.0000000000) [0.0000000000|3.0000000000] "-"  FLR_L,mADC
 SG_ FLR_FreespaceSectorDistance176 : 65|10@0+ (0.1000000000,0.0000000000) [0.0000000000|100.0000000000] "-"  FLR_L,mADC
 SG_ FLR_FreespaceSectorKinestate175 : 67|2@0+ (1.0000000000,0.0000000000) [0.0000000000|3.0000000000] "-"  FLR_L,mADC
 SG_ FLR_FreespaceSectorConfidence175 : 69|2@0+ (1.0000000000,0.0000000000) [0.0000000000|3.0000000000] "-"  FLR_L,mADC
 SG_ FLR_FreespaceSectorDistance175 : 63|10@0+ (0.1000000000,0.0000000000) [0.0000000000|100.0000000000] "-"  FLR_L,mADC
 SG_ FLR_FreespaceSectorKinestate174 : 49|2@0+ (1.0000000000,0.0000000000) [0.0000000000|3.0000000000] "-"  FLR_L,mADC
 SG_ FLR_FreespaceSectorConfidence174 : 51|2@0+ (1.0000000000,0.0000000000) [0.0000000000|3.0000000000] "-"  FLR_L,mADC
 SG_ FLR_FreespaceSectorDistance174 : 45|10@0+ (0.1000000000,0.0000000000) [0.0000000000|100.0000000000] "-"  FLR_L,mADC
 SG_ FLR_FreespaceSectorKinestate173 : 47|2@0+ (1.0000000000,0.0000000000) [0.0000000000|3.0000000000] "-"  FLR_L,mADC
 SG_ FLR_FreespaceSectorConfidence173 : 33|2@0+ (1.0000000000,0.0000000000) [0.0000000000|3.0000000000] "-"  FLR_L,mADC
 SG_ FLR_FreespaceSectorDistance173 : 27|10@0+ (0.1000000000,0.0000000000) [0.0000000000|100.0000000000] "-"  FLR_L,mADC
 SG_ FLR_FreespaceSectorKinestate172 : 29|2@0+ (1.0000000000,0.0000000000) [0.0000000000|3.0000000000] "-"  FLR_L,mADC
 SG_ FLR_FreespaceSectorConfidence172 : 31|2@0+ (1.0000000000,0.0000000000) [0.0000000000|3.0000000000] "-"  FLR_L,mADC
 SG_ FLR_FreespaceSectorDistance172 : 9|10@0+ (0.1000000000,0.0000000000) [0.0000000000|100.0000000000] "-"  FLR_L,mADC
 SG_ FLR_FreespaceSectorKinestate171 : 11|2@0+ (1.0000000000,0.0000000000) [0.0000000000|3.0000000000] "-"  FLR_L,mADC
 SG_ FLR_FreespaceSectorConfidence171 : 13|2@0+ (1.0000000000,0.0000000000) [0.0000000000|3.0000000000] "-"  FLR_L,mADC
 SG_ FLR_FreespaceSectorDistance171 : 7|10@0+ (0.1000000000,0.0000000000) [0.0000000000|100.0000000000] "-"  FLR_L,mADC

BO_ 768 FRR_L_300: 64 FRR_L
 SG_ FLR_CRCCheck_300 : 503|16@0+ (1.0000000000,0.0000000000) [0.0000000000|65535.0000000000] ""  FLR_L,mADC
 SG_ FLR_RollingCounter_300 : 491|4@0+ (1.0000000000,0.0000000000) [0.0000000000|15.0000000000] ""  FLR_L,mADC
 SG_ FLR_FreespaceSectorKinestate238 : 477|2@0+ (1.0000000000,0.0000000000) [0.0000000000|3.0000000000] "-"  FLR_L,mADC
 SG_ FLR_FreespaceSectorConfidence238 : 479|2@0+ (1.0000000000,0.0000000000) [0.0000000000|3.0000000000] "-"  FLR_L,mADC
 SG_ FLR_FreespaceSectorDistance238 : 457|10@0+ (0.1000000000,0.0000000000) [0.0000000000|100.0000000000] "-"  FLR_L,mADC
 SG_ FLR_FreespaceSectorKinestate237 : 459|2@0+ (1.0000000000,0.0000000000) [0.0000000000|3.0000000000] "-"  FLR_L,mADC
 SG_ FLR_FreespaceSectorConfidence237 : 461|2@0+ (1.0000000000,0.0000000000) [0.0000000000|3.0000000000] "-"  FLR_L,mADC
 SG_ FLR_FreespaceSectorDistance237 : 455|10@0+ (0.1000000000,0.0000000000) [0.0000000000|100.0000000000] "-"  FLR_L,mADC
 SG_ FLR_FreespaceSectorKinestate236 : 441|2@0+ (1.0000000000,0.0000000000) [0.0000000000|3.0000000000] "-"  FLR_L,mADC
 SG_ FLR_FreespaceSectorConfidence236 : 443|2@0+ (1.0000000000,0.0000000000) [0.0000000000|3.0000000000] "-"  FLR_L,mADC
 SG_ FLR_FreespaceSectorDistance236 : 437|10@0+ (0.1000000000,0.0000000000) [0.0000000000|100.0000000000] "-"  FLR_L,mADC
 SG_ FLR_FreespaceSectorKinestate235 : 439|2@0+ (1.0000000000,0.0000000000) [0.0000000000|3.0000000000] "-"  FLR_L,mADC
 SG_ FLR_FreespaceSectorConfidence235 : 425|2@0+ (1.0000000000,0.0000000000) [0.0000000000|3.0000000000] "-"  FLR_L,mADC
 SG_ FLR_FreespaceSectorDistance235 : 419|10@0+ (0.1000000000,0.0000000000) [0.0000000000|100.0000000000] "-"  FLR_L,mADC
 SG_ FLR_FreespaceSectorKinestate234 : 421|2@0+ (1.0000000000,0.0000000000) [0.0000000000|3.0000000000] "-"  FLR_L,mADC
 SG_ FLR_FreespaceSectorConfidence234 : 423|2@0+ (1.0000000000,0.0000000000) [0.0000000000|3.0000000000] "-"  FLR_L,mADC
 SG_ FLR_FreespaceSectorDistance234 : 401|10@0+ (0.1000000000,0.0000000000) [0.0000000000|100.0000000000] "-"  FLR_L,mADC
 SG_ FLR_FreespaceSectorKinestate233 : 403|2@0+ (1.0000000000,0.0000000000) [0.0000000000|3.0000000000] "-"  FLR_L,mADC
 SG_ FLR_FreespaceSectorConfidence233 : 405|2@0+ (1.0000000000,0.0000000000) [0.0000000000|3.0000000000] "-"  FLR_L,mADC
 SG_ FLR_FreespaceSectorDistance233 : 399|10@0+ (0.1000000000,0.0000000000) [0.0000000000|100.0000000000] "-"  FLR_L,mADC
 SG_ FLR_FreespaceSectorKinestate232 : 385|2@0+ (1.0000000000,0.0000000000) [0.0000000000|3.0000000000] "-"  FLR_L,mADC
 SG_ FLR_FreespaceSectorConfidence232 : 387|2@0+ (1.0000000000,0.0000000000) [0.0000000000|3.0000000000] "-"  FLR_L,mADC
 SG_ FLR_FreespaceSectorDistance232 : 381|10@0+ (0.1000000000,0.0000000000) [0.0000000000|100.0000000000] "-"  FLR_L,mADC
 SG_ FLR_FreespaceSectorKinestate231 : 383|2@0+ (1.0000000000,0.0000000000) [0.0000000000|3.0000000000] "-"  FLR_L,mADC
 SG_ FLR_FreespaceSectorConfidence231 : 369|2@0+ (1.0000000000,0.0000000000) [0.0000000000|3.0000000000] "-"  FLR_L,mADC
 SG_ FLR_FreespaceSectorDistance231 : 363|10@0+ (0.1000000000,0.0000000000) [0.0000000000|100.0000000000] "-"  FLR_L,mADC
 SG_ FLR_FreespaceSectorKinestate230 : 365|2@0+ (1.0000000000,0.0000000000) [0.0000000000|3.0000000000] "-"  FLR_L,mADC
 SG_ FLR_FreespaceSectorConfidence230 : 367|2@0+ (1.0000000000,0.0000000000) [0.0000000000|3.0000000000] "-"  FLR_L,mADC
 SG_ FLR_FreespaceSectorDistance230 : 345|10@0+ (0.1000000000,0.0000000000) [0.0000000000|100.0000000000] "-"  FLR_L,mADC
 SG_ FLR_FreespaceSectorKinestate229 : 347|2@0+ (1.0000000000,0.0000000000) [0.0000000000|3.0000000000] "-"  FLR_L,mADC
 SG_ FLR_FreespaceSectorConfidence229 : 349|2@0+ (1.0000000000,0.0000000000) [0.0000000000|3.0000000000] "-"  FLR_L,mADC
 SG_ FLR_FreespaceSectorDistance229 : 343|10@0+ (0.1000000000,0.0000000000) [0.0000000000|100.0000000000] "-"  FLR_L,mADC
 SG_ FLR_FreespaceSectorKinestate228 : 329|2@0+ (1.0000000000,0.0000000000) [0.0000000000|3.0000000000] "-"  FLR_L,mADC
 SG_ FLR_FreespaceSectorConfidence228 : 331|2@0+ (1.0000000000,0.0000000000) [0.0000000000|3.0000000000] "-"  FLR_L,mADC
 SG_ FLR_FreespaceSectorDistance228 : 325|10@0+ (0.1000000000,0.0000000000) [0.0000000000|100.0000000000] "-"  FLR_L,mADC
 SG_ FLR_FreespaceSectorKinestate227 : 327|2@0+ (1.0000000000,0.0000000000) [0.0000000000|3.0000000000] "-"  FLR_L,mADC
 SG_ FLR_FreespaceSectorConfidence227 : 313|2@0+ (1.0000000000,0.0000000000) [0.0000000000|3.0000000000] "-"  FLR_L,mADC
 SG_ FLR_FreespaceSectorDistance227 : 307|10@0+ (0.1000000000,0.0000000000) [0.0000000000|100.0000000000] "-"  FLR_L,mADC
 SG_ FLR_FreespaceSectorKinestate226 : 309|2@0+ (1.0000000000,0.0000000000) [0.0000000000|3.0000000000] "-"  FLR_L,mADC
 SG_ FLR_FreespaceSectorConfidence226 : 311|2@0+ (1.0000000000,0.0000000000) [0.0000000000|3.0000000000] "-"  FLR_L,mADC
 SG_ FLR_FreespaceSectorDistance226 : 289|10@0+ (0.1000000000,0.0000000000) [0.0000000000|100.0000000000] "-"  FLR_L,mADC
 SG_ FLR_FreespaceSectorKinestate225 : 291|2@0+ (1.0000000000,0.0000000000) [0.0000000000|3.0000000000] "-"  FLR_L,mADC
 SG_ FLR_FreespaceSectorConfidence225 : 293|2@0+ (1.0000000000,0.0000000000) [0.0000000000|3.0000000000] "-"  FLR_L,mADC
 SG_ FLR_FreespaceSectorDistance225 : 287|10@0+ (0.1000000000,0.0000000000) [0.0000000000|100.0000000000] "-"  FLR_L,mADC
 SG_ FLR_FreespaceSectorKinestate224 : 273|2@0+ (1.0000000000,0.0000000000) [0.0000000000|3.0000000000] "-"  FLR_L,mADC
 SG_ FLR_FreespaceSectorConfidence224 : 275|2@0+ (1.0000000000,0.0000000000) [0.0000000000|3.0000000000] "-"  FLR_L,mADC
 SG_ FLR_FreespaceSectorDistance224 : 269|10@0+ (0.1000000000,0.0000000000) [0.0000000000|100.0000000000] "-"  FLR_L,mADC
 SG_ FLR_FreespaceSectorKinestate223 : 271|2@0+ (1.0000000000,0.0000000000) [0.0000000000|3.0000000000] "-"  FLR_L,mADC
 SG_ FLR_FreespaceSectorConfidence223 : 257|2@0+ (1.0000000000,0.0000000000) [0.0000000000|3.0000000000] "-"  FLR_L,mADC
 SG_ FLR_FreespaceSectorDistance223 : 251|10@0+ (0.1000000000,0.0000000000) [0.0000000000|100.0000000000] "-"  FLR_L,mADC
 SG_ FLR_FreespaceSectorKinestate222 : 253|2@0+ (1.0000000000,0.0000000000) [0.0000000000|3.0000000000] "-"  FLR_L,mADC
 SG_ FLR_FreespaceSectorConfidence222 : 255|2@0+ (1.0000000000,0.0000000000) [0.0000000000|3.0000000000] "-"  FLR_L,mADC
 SG_ FLR_FreespaceSectorDistance222 : 233|10@0+ (0.1000000000,0.0000000000) [0.0000000000|100.0000000000] "-"  FLR_L,mADC
 SG_ FLR_FreespaceSectorKinestate221 : 235|2@0+ (1.0000000000,0.0000000000) [0.0000000000|3.0000000000] "-"  FLR_L,mADC
 SG_ FLR_FreespaceSectorConfidence221 : 237|2@0+ (1.0000000000,0.0000000000) [0.0000000000|3.0000000000] "-"  FLR_L,mADC
 SG_ FLR_FreespaceSectorDistance221 : 231|10@0+ (0.1000000000,0.0000000000) [0.0000000000|100.0000000000] "-"  FLR_L,mADC
 SG_ FLR_FreespaceSectorKinestate220 : 217|2@0+ (1.0000000000,0.0000000000) [0.0000000000|3.0000000000] "-"  FLR_L,mADC
 SG_ FLR_FreespaceSectorConfidence220 : 219|2@0+ (1.0000000000,0.0000000000) [0.0000000000|3.0000000000] "-"  FLR_L,mADC
 SG_ FLR_FreespaceSectorDistance220 : 213|10@0+ (0.1000000000,0.0000000000) [0.0000000000|100.0000000000] "-"  FLR_L,mADC
 SG_ FLR_FreespaceSectorKinestate219 : 215|2@0+ (1.0000000000,0.0000000000) [0.0000000000|3.0000000000] "-"  FLR_L,mADC
 SG_ FLR_FreespaceSectorConfidence219 : 201|2@0+ (1.0000000000,0.0000000000) [0.0000000000|3.0000000000] "-"  FLR_L,mADC
 SG_ FLR_FreespaceSectorDistance219 : 195|10@0+ (0.1000000000,0.0000000000) [0.0000000000|100.0000000000] "-"  FLR_L,mADC
 SG_ FLR_FreespaceSectorKinestate218 : 197|2@0+ (1.0000000000,0.0000000000) [0.0000000000|3.0000000000] "-"  FLR_L,mADC
 SG_ FLR_FreespaceSectorConfidence218 : 199|2@0+ (1.0000000000,0.0000000000) [0.0000000000|3.0000000000] "-"  FLR_L,mADC
 SG_ FLR_FreespaceSectorDistance218 : 177|10@0+ (0.1000000000,0.0000000000) [0.0000000000|100.0000000000] "-"  FLR_L,mADC
 SG_ FLR_FreespaceSectorKinestate217 : 179|2@0+ (1.0000000000,0.0000000000) [0.0000000000|3.0000000000] "-"  FLR_L,mADC
 SG_ FLR_FreespaceSectorConfidence217 : 181|2@0+ (1.0000000000,0.0000000000) [0.0000000000|3.0000000000] "-"  FLR_L,mADC
 SG_ FLR_FreespaceSectorDistance217 : 175|10@0+ (0.1000000000,0.0000000000) [0.0000000000|100.0000000000] "-"  FLR_L,mADC
 SG_ FLR_FreespaceSectorKinestate216 : 161|2@0+ (1.0000000000,0.0000000000) [0.0000000000|3.0000000000] "-"  FLR_L,mADC
 SG_ FLR_FreespaceSectorConfidence216 : 163|2@0+ (1.0000000000,0.0000000000) [0.0000000000|3.0000000000] "-"  FLR_L,mADC
 SG_ FLR_FreespaceSectorDistance216 : 157|10@0+ (0.1000000000,0.0000000000) [0.0000000000|100.0000000000] "-"  FLR_L,mADC
 SG_ FLR_FreespaceSectorKinestate215 : 159|2@0+ (1.0000000000,0.0000000000) [0.0000000000|3.0000000000] "-"  FLR_L,mADC
 SG_ FLR_FreespaceSectorConfidence215 : 145|2@0+ (1.0000000000,0.0000000000) [0.0000000000|3.0000000000] "-"  FLR_L,mADC
 SG_ FLR_FreespaceSectorDistance215 : 139|10@0+ (0.1000000000,0.0000000000) [0.0000000000|100.0000000000] "-"  FLR_L,mADC
 SG_ FLR_FreespaceSectorKinestate214 : 141|2@0+ (1.0000000000,0.0000000000) [0.0000000000|3.0000000000] "-"  FLR_L,mADC
 SG_ FLR_FreespaceSectorConfidence214 : 143|2@0+ (1.0000000000,0.0000000000) [0.0000000000|3.0000000000] "-"  FLR_L,mADC
 SG_ FLR_FreespaceSectorDistance214 : 121|10@0+ (0.1000000000,0.0000000000) [0.0000000000|100.0000000000] "-"  FLR_L,mADC
 SG_ FLR_FreespaceSectorKinestate213 : 123|2@0+ (1.0000000000,0.0000000000) [0.0000000000|3.0000000000] "-"  FLR_L,mADC
 SG_ FLR_FreespaceSectorConfidence213 : 125|2@0+ (1.0000000000,0.0000000000) [0.0000000000|3.0000000000] "-"  FLR_L,mADC
 SG_ FLR_FreespaceSectorDistance213 : 119|10@0+ (0.1000000000,0.0000000000) [0.0000000000|100.0000000000] "-"  FLR_L,mADC
 SG_ FLR_FreespaceSectorKinestate212 : 105|2@0+ (1.0000000000,0.0000000000) [0.0000000000|3.0000000000] "-"  FLR_L,mADC
 SG_ FLR_FreespaceSectorConfidence212 : 107|2@0+ (1.0000000000,0.0000000000) [0.0000000000|3.0000000000] "-"  FLR_L,mADC
 SG_ FLR_FreespaceSectorDistance212 : 101|10@0+ (0.1000000000,0.0000000000) [0.0000000000|100.0000000000] "-"  FLR_L,mADC
 SG_ FLR_FreespaceSectorKinestate211 : 103|2@0+ (1.0000000000,0.0000000000) [0.0000000000|3.0000000000] "-"  FLR_L,mADC
 SG_ FLR_FreespaceSectorConfidence211 : 89|2@0+ (1.0000000000,0.0000000000) [0.0000000000|3.0000000000] "-"  FLR_L,mADC
 SG_ FLR_FreespaceSectorDistance211 : 83|10@0+ (0.1000000000,0.0000000000) [0.0000000000|100.0000000000] "-"  FLR_L,mADC
 SG_ FLR_FreespaceSectorKinestate210 : 85|2@0+ (1.0000000000,0.0000000000) [0.0000000000|3.0000000000] "-"  FLR_L,mADC
 SG_ FLR_FreespaceSectorConfidence210 : 87|2@0+ (1.0000000000,0.0000000000) [0.0000000000|3.0000000000] "-"  FLR_L,mADC
 SG_ FLR_FreespaceSectorDistance210 : 65|10@0+ (0.1000000000,0.0000000000) [0.0000000000|100.0000000000] "-"  FLR_L,mADC
 SG_ FLR_FreespaceSectorKinestate209 : 67|2@0+ (1.0000000000,0.0000000000) [0.0000000000|3.0000000000] "-"  FLR_L,mADC
 SG_ FLR_FreespaceSectorConfidence209 : 69|2@0+ (1.0000000000,0.0000000000) [0.0000000000|3.0000000000] "-"  FLR_L,mADC
 SG_ FLR_FreespaceSectorDistance209 : 63|10@0+ (0.1000000000,0.0000000000) [0.0000000000|100.0000000000] "-"  FLR_L,mADC
 SG_ FLR_FreespaceSectorKinestate208 : 49|2@0+ (1.0000000000,0.0000000000) [0.0000000000|3.0000000000] "-"  FLR_L,mADC
 SG_ FLR_FreespaceSectorConfidence208 : 51|2@0+ (1.0000000000,0.0000000000) [0.0000000000|3.0000000000] "-"  FLR_L,mADC
 SG_ FLR_FreespaceSectorDistance208 : 45|10@0+ (0.1000000000,0.0000000000) [0.0000000000|100.0000000000] "-"  FLR_L,mADC
 SG_ FLR_FreespaceSectorKinestate207 : 47|2@0+ (1.0000000000,0.0000000000) [0.0000000000|3.0000000000] "-"  FLR_L,mADC
 SG_ FLR_FreespaceSectorConfidence207 : 33|2@0+ (1.0000000000,0.0000000000) [0.0000000000|3.0000000000] "-"  FLR_L,mADC
 SG_ FLR_FreespaceSectorDistance207 : 27|10@0+ (0.1000000000,0.0000000000) [0.0000000000|100.0000000000] "-"  FLR_L,mADC
 SG_ FLR_FreespaceSectorKinestate206 : 29|2@0+ (1.0000000000,0.0000000000) [0.0000000000|3.0000000000] "-"  FLR_L,mADC
 SG_ FLR_FreespaceSectorConfidence206 : 31|2@0+ (1.0000000000,0.0000000000) [0.0000000000|3.0000000000] "-"  FLR_L,mADC
 SG_ FLR_FreespaceSectorDistance206 : 9|10@0+ (0.1000000000,0.0000000000) [0.0000000000|100.0000000000] "-"  FLR_L,mADC
 SG_ FLR_FreespaceSectorKinestate205 : 11|2@0+ (1.0000000000,0.0000000000) [0.0000000000|3.0000000000] "-"  FLR_L,mADC
 SG_ FLR_FreespaceSectorConfidence205 : 13|2@0+ (1.0000000000,0.0000000000) [0.0000000000|3.0000000000] "-"  FLR_L,mADC
 SG_ FLR_FreespaceSectorDistance205 : 7|10@0+ (0.1000000000,0.0000000000) [0.0000000000|100.0000000000] "-"  FLR_L,mADC

BO_ 771 FRR_L_303: 64 FRR_L
 SG_ FLR_CRCCheck_303 : 503|16@0+ (1.0000000000,0.0000000000) [0.0000000000|65535.0000000000] ""  FLR_L,mADC
 SG_ FLR_RollingCounter_301 : 491|4@0+ (1.0000000000,0.0000000000) [0.0000000000|15.0000000000] ""  FLR_L,mADC
 SG_ FLR_FreespaceSectorKinestate240 : 29|2@0+ (1.0000000000,0.0000000000) [0.0000000000|3.0000000000] "-"  FLR_L,mADC
 SG_ FLR_FreespaceSectorConfidence240 : 31|2@0+ (1.0000000000,0.0000000000) [0.0000000000|3.0000000000] "-"  FLR_L,mADC
 SG_ FLR_FreespaceSectorDistance240 : 9|10@0+ (0.1000000000,0.0000000000) [0.0000000000|100.0000000000] "-"  FLR_L,mADC
 SG_ FLR_FreespaceSectorKinestate239 : 11|2@0+ (1.0000000000,0.0000000000) [0.0000000000|3.0000000000] "-"  FLR_L,mADC
 SG_ FLR_FreespaceSectorConfidence239 : 13|2@0+ (1.0000000000,0.0000000000) [0.0000000000|3.0000000000] "-"  FLR_L,mADC
 SG_ FLR_FreespaceSectorDistance239 : 7|10@0+ (0.1000000000,0.0000000000) [0.0000000000|100.0000000000] "-"  FLR_L,mADC

BO_ 691 FRR_L_2B3: 64 FRR_L
 SG_ RLR_CRCCheck_2B3 : 503|16@0+ (1.0000000000,0.0000000000) [0.0000000000|65535.0000000000] ""  FLR_L,mADC
 SG_ RLR_RollingCounter_2B3 : 491|4@0+ (1.0000000000,0.0000000000) [0.0000000000|15.0000000000] ""  FLR_L,mADC
 SG_ FRR_ResetSts : 250|3@0+ (1.0000000000,0.0000000000) [0.0000000000|7.0000000000] ""  FLR_L,mADC
 SG_ FuncDegradeType_FR : 223|32@0+ (1.0000000000,0.0000000000) [0.0000000000|4294967295.0000000000] ""  FLR_L,mADC
 SG_ FUSION_TimeoutCnt_FR : 215|8@0+ (1.0000000000,0.0000000000) [0.0000000000|255.0000000000] ""  FLR_L,mADC
 SG_ VALIDATION_TimeoutCnt_FR : 207|8@0+ (1.0000000000,0.0000000000) [0.0000000000|255.0000000000] ""  FLR_L,mADC
 SG_ CurFrameCycle_FR : 199|8@0+ (1.0000000000,0.0000000000) [0.0000000000|255.0000000000] ""  FLR_L,mADC
 SG_ ProcessTimeoutCnt_FR : 191|8@0+ (1.0000000000,0.0000000000) [0.0000000000|255.0000000000] ""  FLR_L,mADC
 SG_ RevFrameCnt_FR : 159|32@0+ (1.0000000000,0.0000000000) [0.0000000000|4294967295.0000000000] ""  FLR_L,mADC
 SG_ Local_Pointcloud_Number_FR : 151|8@0+ (1.0000000000,0.0000000000) [0.0000000000|255.0000000000] ""  FLR_L,mADC
 SG_ RealTimeCal_PrcssBar_FR : 142|7@0+ (1.0000000000,0.0000000000) [0.0000000000|100.0000000000] "%"  FLR_L,mADC
 SG_ RealTimeCal_VelErrOutput_FR : 134|7@0+ (0.1000000000,-5.0000000000) [-5.0000000000|5.0000000000] "%"  FLR_L,mADC
 SG_ RealTimeCal_HoriMntErrOutput_FR : 112|9@0+ (0.0200000000,-5.0000000000) [-5.0000000000|5.0000000000] "бу"  FLR_L,mADC
 SG_ RealTimeCal_FailReasonCode_FR : 116|3@0+ (1.0000000000,0.0000000000) [0.0000000000|7.0000000000] ""  FLR_L,mADC
 SG_ RealTimeCal_Status_FR : 119|3@0+ (1.0000000000,0.0000000000) [0.0000000000|7.0000000000] ""  FLR_L,mADC
 SG_ DiagCal_PrcssBar_FR : 110|7@0+ (1.0000000000,0.0000000000) [0.0000000000|100.0000000000] "%"  FLR_L,mADC
 SG_ DiagCal_VelErrOutput_FR : 102|7@0+ (0.1000000000,-5.0000000000) [-5.0000000000|5.0000000000] "%"  FLR_L,mADC
 SG_ DiagCal_HoriMntErrOutput_FR : 80|9@0+ (0.0200000000,-5.0000000000) [-5.0000000000|5.0000000000] "бу"  FLR_L,mADC
 SG_ DiagCal_FailReasonCode_FR : 84|3@0+ (1.0000000000,0.0000000000) [0.0000000000|7.0000000000] ""  FLR_L,mADC
 SG_ DiagCal_Status_FR : 87|3@0+ (1.0000000000,0.0000000000) [0.0000000000|7.0000000000] ""  FLR_L,mADC
 SG_ EolCal_PrcssBar_FR : 78|7@0+ (1.0000000000,0.0000000000) [0.0000000000|100.0000000000] "%"  FLR_L,mADC
 SG_ EolCal_VelErrOutput_FR : 70|7@0+ (0.1000000000,-5.0000000000) [-5.0000000000|5.0000000000] "%"  FLR_L,mADC
 SG_ EolCal_HoriMntErrOutput_FR : 48|9@0+ (0.0200000000,-5.0000000000) [-5.0000000000|5.0000000000] "бу"  FLR_L,mADC
 SG_ EolCal_FailReasonCode_FR : 52|3@0+ (1.0000000000,0.0000000000) [0.0000000000|7.0000000000] ""  FLR_L,mADC
 SG_ EolCal_Status_FR : 55|3@0+ (1.0000000000,0.0000000000) [0.0000000000|7.0000000000] ""  FLR_L,mADC
 SG_ PriCounter : 31|24@0+ (1.0000000000,0.0000000000) [0.0000000000|16777215.0000000000] ""  FLR_L,mADC
 SG_ MsgCounter_FR : 7|24@0+ (1.0000000000,0.0000000000) [0.0000000000|16777215.0000000000] ""  FLR_L,mADC

BO_ 338 mADC_152: 64 mADC
 SG_ ADR_TriggerEventReq : 303|6@0+ (1.0000000000,0.0000000000) [0.0000000000|63.0000000000] ""  FLR_L,FRR_L
 SG_ ADC_RollingCounter_152 : 491|4@0+ (1.0000000000,0.0000000000) [0.0000000000|15.0000000000] ""  FLR_L,FRR_L
 SG_ ADC_CRCCheck_152 : 503|16@0+ (1.0000000000,0.0000000000) [0.0000000000|65535.0000000000] ""  FLR_L,FRR_L
 SG_ ACC_AEBEnable : 26|1@0+ (1.0000000000,0.0000000000) [0.0000000000|1.0000000000] ""  FLR_L,FRR_L
 SG_ ACC_FCWSettingStatus : 30|3@0+ (1.0000000000,0.0000000000) [0.0000000000|7.0000000000] ""  FLR_L,FRR_L
 SG_ ADC_SenceMode : 131|2@0+ (1.0000000000,0.0000000000) [0.0000000000|3.0000000000] ""  FLR_L,FRR_L

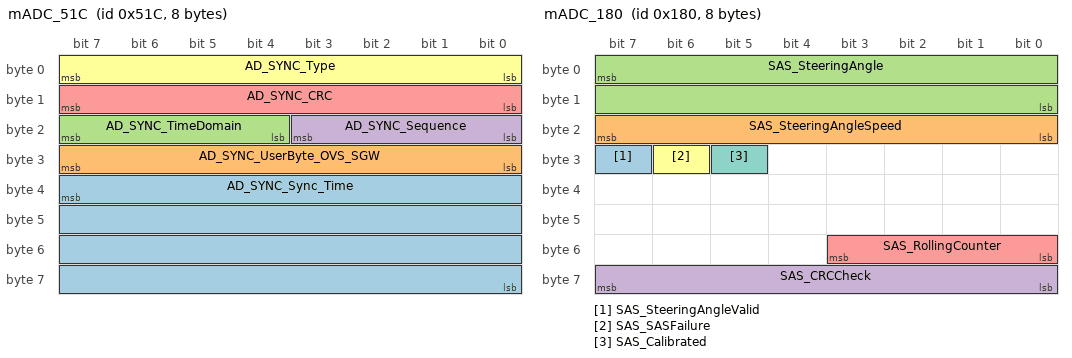
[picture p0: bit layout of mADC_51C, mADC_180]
BO_ 1308 mADC_51C: 8 mADC
 SG_ AD_SYNC_Sync_Time : 39|32@0+ (1.0000000000,0.0000000000) [0.0000000000|4290000000.0000000000] ""  FLR_L,FRR_L
 SG_ AD_SYNC_UserByte_OVS_SGW : 31|8@0+ (1.0000000000,0.0000000000) [0.0000000000|255.0000000000] ""  FLR_L,FRR_L
 SG_ AD_SYNC_TimeDomain : 23|4@0+ (1.0000000000,0.0000000000) [0.0000000000|15.0000000000] ""  FLR_L,FRR_L
 SG_ AD_SYNC_Sequence : 19|4@0+ (1.0000000000,0.0000000000) [0.0000000000|15.0000000000] ""  FLR_L,FRR_L
 SG_ AD_SYNC_CRC : 15|8@0+ (1.0000000000,0.0000000000) [0.0000000000|255.0000000000] ""  FLR_L,FRR_L
 SG_ AD_SYNC_Type : 7|8@0+ (1.0000000000,0.0000000000) [0.0000000000|255.0000000000] ""  FLR_L,FRR_L

BO_ 384 mADC_180: 8 mADC
 SG_ SAS_SteeringAngleValid : 31|1@0+ (1.0000000000,0.0000000000) [0.0000000000|1.0000000000] ""  FLR_L,FRR_L
 SG_ SAS_SteeringAngleSpeed : 23|8@0+ (4.0000000000,0.0000000000) [0.0000000000|1016.0000000000] "deg/s"  FLR_L,FRR_L
 SG_ SAS_SteeringAngle : 7|16@0- (0.1000000000,0.0000000000) [-780.0000000000|780.0000000000] "degree"  FLR_L,FRR_L
 SG_ SAS_CRCCheck : 63|8@0+ (1.0000000000,0.0000000000) [0.0000000000|255.0000000000] ""  FLR_L,FRR_L
 SG_ SAS_RollingCounter : 51|4@0+ (1.0000000000,0.0000000000) [0.0000000000|15.0000000000] ""  FLR_L,FRR_L
 SG_ SAS_SASFailure : 30|1@0+ (1.0000000000,0.0000000000) [0.0000000000|1.0000000000] ""  FLR_L,FRR_L
 SG_ SAS_Calibrated : 29|1@0+ (1.0000000000,0.0000000000) [0.0000000000|1.0000000000] ""  FLR_L,FRR_L

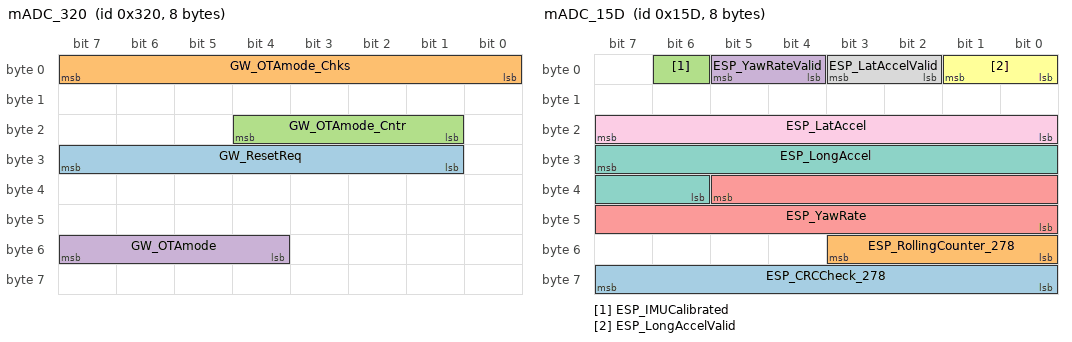
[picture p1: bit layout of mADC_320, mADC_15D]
BO_ 800 mADC_320: 8 mADC
 SG_ GW_ResetReq : 31|7@0+ (1.0000000000,0.0000000000) [0.0000000000|127.0000000000] ""  FLR_L,FRR_L
 SG_ GW_OTAmode_Chks : 7|8@0+ (1.0000000000,0.0000000000) [0.0000000000|255.0000000000] ""  FLR_L,FRR_L
 SG_ GW_OTAmode_Cntr : 20|4@0+ (1.0000000000,0.0000000000) [0.0000000000|15.0000000000] ""  FLR_L,FRR_L
 SG_ GW_OTAmode : 55|4@0+ (1.0000000000,0.0000000000) [0.0000000000|15.0000000000] ""  FLR_L,FRR_L

BO_ 1302 mADC_516: 32 mADC
 SG_ HU_LocalTimeValid : 71|1@0+ (1.0000000000,0.0000000000) [0.0000000000|1.0000000000] ""  FLR_L,FRR_L
 SG_ HU_LocalTimeSecond : 109|6@0+ (1.0000000000,0.0000000000) [0.0000000000|59.0000000000] "second"  FLR_L,FRR_L
 SG_ HU_LocalTimeMinute : 101|6@0+ (1.0000000000,0.0000000000) [0.0000000000|59.0000000000] "minute"  FLR_L,FRR_L
 SG_ HU_LocalTimeHour : 92|5@0+ (1.0000000000,0.0000000000) [0.0000000000|23.0000000000] "hour"  FLR_L,FRR_L
 SG_ HU_LocalTimeDate : 84|5@0+ (1.0000000000,0.0000000000) [1.0000000000|31.0000000000] "day"  FLR_L,FRR_L
 SG_ HU_LocalTimeMonth : 75|4@0+ (1.0000000000,0.0000000000) [1.0000000000|12.0000000000] "month"  FLR_L,FRR_L
 SG_ HU_LocalTimeYear : 119|8@0+ (1.0000000000,2013.0000000000) [2013.0000000000|2268.0000000000] "year"  FLR_L,FRR_L

BO_ 1328 mADC_530: 8 mADC
 SG_ IP_TotalOdometer : 23|24@0+ (0.1000000000,0.0000000000) [0.0000000000|999999.0000000000] "Km"  FLR_L,FRR_L

BO_ 349 mADC_15D: 8 mADC
 SG_ ESP_CRCCheck_278 : 63|8@0+ (1.0000000000,0.0000000000) [0.0000000000|255.0000000000] ""  FLR_L,FRR_L
 SG_ ESP_RollingCounter_278 : 51|4@0+ (1.0000000000,0.0000000000) [0.0000000000|15.0000000000] ""  FLR_L,FRR_L
 SG_ ESP_IMUCalibrated : 6|1@0+ (1.0000000000,0.0000000000) [0.0000000000|1.0000000000] ""  FLR_L,FRR_L
 SG_ ESP_YawRateValid : 5|2@0+ (1.0000000000,0.0000000000) [0.0000000000|3.0000000000] ""  FLR_L,FRR_L
 SG_ ESP_YawRate : 37|14@0+ (0.0100000000,-81.9100000000) [-81.9100000000|81.9100000000] "degree/s"  FLR_L,FRR_L
 SG_ ESP_LongAccelValid : 1|2@0+ (1.0000000000,0.0000000000) [0.0000000000|3.0000000000] ""  FLR_L,FRR_L
 SG_ ESP_LongAccel : 31|10@0+ (0.0312500000,-16.0000000000) [-16.0000000000|15.9062500000] "m/s2"  FLR_L,FRR_L
 SG_ ESP_LatAccelValid : 3|2@0+ (1.0000000000,0.0000000000) [0.0000000000|3.0000000000] ""  FLR_L,FRR_L
 SG_ ESP_LatAccel : 23|8@0+ (0.1000000000,-12.7000000000) [-12.7000000000|12.7000000000] "m/s2"  FLR_L,FRR_L

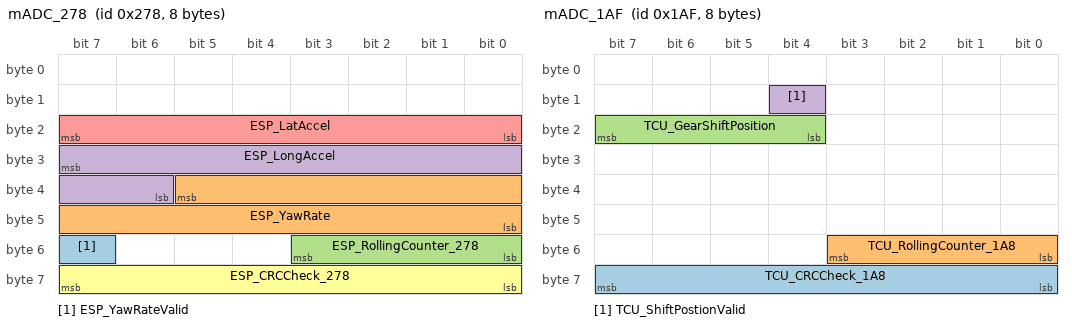
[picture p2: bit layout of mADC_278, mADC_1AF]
BO_ 632 mADC_278: 8 mADC
 SG_ ESP_YawRateValid : 55|1@0+ (1.0000000000,0.0000000000) [0.0000000000|1.0000000000] ""  FLR_L,FRR_L
 SG_ ESP_YawRate : 37|14@0+ (0.0100000000,-81.9100000000) [-81.9100000000|81.9100000000] "degree/s"  FLR_L,FRR_L
 SG_ ESP_RollingCounter_278 : 51|4@0+ (1.0000000000,0.0000000000) [0.0000000000|15.0000000000] ""  FLR_L,FRR_L
 SG_ ESP_LongAccel : 31|10@0+ (0.0312500000,-16.0000000000) [-16.0000000000|15.9062500000] "m/s2"  FLR_L,FRR_L
 SG_ ESP_LatAccel : 23|8@0+ (0.1000000000,-12.7000000000) [-12.7000000000|12.7000000000] "m/s2"  FLR_L,FRR_L
 SG_ ESP_CRCCheck_278 : 63|8@0+ (1.0000000000,0.0000000000) [0.0000000000|255.0000000000] ""  FLR_L,FRR_L

BO_ 378 mADC_17A: 64 mADC
 SG_ ESP_TCSFailStatus : 4|1@0+ (1.0000000000,0.0000000000) [0.0000000000|1.0000000000] ""  FLR_L,FRR_L
 SG_ ESP_ESPFunctionStatus : 1|1@0+ (1.0000000000,0.0000000000) [0.0000000000|1.0000000000] ""  FLR_L,FRR_L
 SG_ ESP_ESPActiveStatus : 0|1@0+ (1.0000000000,0.0000000000) [0.0000000000|1.0000000000] ""  FLR_L,FRR_L
 SG_ ESP_ABSFailStatus : 3|1@0+ (1.0000000000,0.0000000000) [0.0000000000|1.0000000000] ""  FLR_L,FRR_L
 SG_ ESP_ABSActiveStatus : 7|1@0+ (1.0000000000,0.0000000000) [0.0000000000|1.0000000000] ""  FLR_L,FRR_L
 SG_ ESP_VehicleSpeedValid : 37|1@0+ (1.0000000000,0.0000000000) [0.0000000000|1.0000000000] ""  FLR_L,FRR_L
 SG_ ESP_VehicleSpeed : 36|13@0+ (0.0562500000,0.0000000000) [0.0000000000|360.0000000000] "km/h"  FLR_L,FRR_L

BO_ 523 mADC_20B: 64 mADC
 SG_ ESP_RollingCounter_20B : 491|4@0+ (1.0000000000,0.0000000000) [0.0000000000|15.0000000000] ""  FLR_L,FRR_L
 SG_ ESP_CRCCheck_20B : 503|16@0+ (1.0000000000,0.0000000000) [0.0000000000|65535.0000000000] ""  FLR_L,FRR_L
 SG_ ESP_BrakeForce : 263|1@0+ (1.0000000000,0.0000000000) [0.0000000000|1.0000000000] ""  FLR_L,FRR_L
 SG_ ESP_AEBdecActive : 257|1@0+ (1.0000000000,0.0000000000) [0.0000000000|1.0000000000] ""  FLR_L,FRR_L
 SG_ ESP_AEBAvailable : 258|1@0+ (1.0000000000,0.0000000000) [0.0000000000|1.0000000000] ""  FLR_L,FRR_L
 SG_ ESP_VDCActive : 266|1@0+ (1.0000000000,0.0000000000) [0.0000000000|1.0000000000] ""  FLR_L,FRR_L
 SG_ ESP_TCSActive : 265|1@0+ (1.0000000000,0.0000000000) [0.0000000000|1.0000000000] ""  FLR_L,FRR_L
 SG_ ESP_OnlyABSActive : 264|1@0+ (1.0000000000,0.0000000000) [0.0000000000|1.0000000000] ""  FLR_L,FRR_L
 SG_ Wheel_Speed_RR_Valid_Data : 71|1@0+ (1.0000000000,0.0000000000) [0.0000000000|1.0000000000] ""  FLR_L,FRR_L
 SG_ Wheel_Speed_RR_Pulse : 231|8@0+ (1.0000000000,0.0000000000) [0.0000000000|254.0000000000] ""  FLR_L,FRR_L
 SG_ Wheel_Speed_RR_Direction : 70|2@0+ (1.0000000000,0.0000000000) [0.0000000000|3.0000000000] ""  FLR_L,FRR_L
 SG_ Wheel_Speed_RR_Data : 68|13@0+ (0.0562500000,0.0000000000) [0.0000000000|360.0000000000] "km/h"  FLR_L,FRR_L
 SG_ Wheel_Speed_RL_Valid_Data : 87|1@0+ (1.0000000000,0.0000000000) [0.0000000000|1.0000000000] ""  FLR_L,FRR_L
 SG_ Wheel_Speed_RL_Pulse : 239|8@0+ (1.0000000000,0.0000000000) [0.0000000000|254.0000000000] ""  FLR_L,FRR_L
 SG_ Wheel_Speed_RL_Direction : 86|2@0+ (1.0000000000,0.0000000000) [0.0000000000|3.0000000000] ""  FLR_L,FRR_L
 SG_ Wheel_Speed_RL_Data : 84|13@0+ (0.0562500000,0.0000000000) [0.0000000000|360.0000000000] "km/h"  FLR_L,FRR_L
 SG_ Wheel_Speed_FR_Valid_Data : 7|1@0+ (1.0000000000,0.0000000000) [0.0000000000|1.0000000000] ""  FLR_L,FRR_L
 SG_ Wheel_Speed_FR_Pulse : 223|8@0+ (1.0000000000,0.0000000000) [0.0000000000|254.0000000000] ""  FLR_L,FRR_L
 SG_ Wheel_Speed_FR_Direction : 6|2@0+ (1.0000000000,0.0000000000) [0.0000000000|3.0000000000] ""  FLR_L,FRR_L
 SG_ Wheel_Speed_FR_Data : 4|13@0+ (0.0562500000,0.0000000000) [0.0000000000|360.0000000000] "km/h"  FLR_L,FRR_L
 SG_ Wheel_Speed_FL_Valid_Data : 23|1@0+ (1.0000000000,0.0000000000) [0.0000000000|1.0000000000] ""  FLR_L,FRR_L
 SG_ Wheel_Speed_FL_Pulse : 215|8@0+ (1.0000000000,0.0000000000) [0.0000000000|254.0000000000] ""  FLR_L,FRR_L
 SG_ Wheel_Speed_FL_Direction : 22|2@0+ (1.0000000000,0.0000000000) [0.0000000000|3.0000000000] ""  FLR_L,FRR_L
 SG_ Wheel_Speed_FL_Data : 20|13@0+ (0.0562500000,0.0000000000) [0.0000000000|360.0000000000] "km/h"  FLR_L,FRR_L
 SG_ IBCU_BrkPedlStsGbVld : 303|2@0+ (1.0000000000,0.0000000000) [0.0000000000|2.0000000000] ""  FLR_L,FRR_L
 SG_ IBCU_BrkPedoplStsGb : 295|8@0+ (1.0000000000,0.0000000000) [0.0000000000|255.0000000000] "%"  FLR_L,FRR_L
 SG_ ESP_VehicleStandstillVld : 286|1@0+ (1.0000000000,0.0000000000) [0.0000000000|1.0000000000] ""  FLR_L,FRR_L
 SG_ ESP_VehicleStandstill : 267|1@0+ (1.0000000000,0.0000000000) [0.0000000000|1.0000000000] ""  FLR_L,FRR_L

BO_ 381 mADC_17D: 64 mADC
 SG_ PCU_RollingCounter_17D : 491|4@0+ (1.0000000000,0.0000000000) [0.0000000000|15.0000000000] ""  FLR_L,FRR_L
 SG_ PCU_CRCCheck_17D : 503|16@0+ (1.0000000000,0.0000000000) [0.0000000000|65535.0000000000] ""  FLR_L,FRR_L
 SG_ PCU_RealAccPedlVld : 79|1@0+ (1.0000000000,0.0000000000) [0.0000000000|1.0000000000] ""  FLR_L,FRR_L
 SG_ PCU_RealAccPedl : 71|8@0+ (0.3920000000,0.0000000000) [0.0000000000|99.9600000000] "%"  FLR_L,FRR_L

BO_ 398 mADC_18E: 32 mADC
 SG_ EMS_BrakePedalStatus : 119|2@0+ (1.0000000000,0.0000000000) [0.0000000000|3.0000000000] ""  FLR_L,FRR_L
 SG_ EMS_RollingCounter_18E : 235|4@0+ (1.0000000000,0.0000000000) [0.0000000000|15.0000000000] ""  FLR_L,FRR_L
 SG_ EMS_CRCCheck_18E : 247|16@0+ (1.0000000000,0.0000000000) [0.0000000000|65535.0000000000] ""  FLR_L,FRR_L
 SG_ EMS_RealAccPedal : 71|8@0+ (0.3920000000,0.0000000000) [0.0000000000|99.5680000000] "%"  FLR_L,FRR_L

BO_ 431 mADC_1AF: 8 mADC
 SG_ TCU_CRCCheck_1A8 : 63|8@0+ (1.0000000000,0.0000000000) [0.0000000000|255.0000000000] ""  FLR_L,FRR_L
 SG_ TCU_RollingCounter_1A8 : 51|4@0+ (1.0000000000,0.0000000000) [0.0000000000|15.0000000000] ""  FLR_L,FRR_L
 SG_ TCU_GearShiftPosition : 23|4@0+ (1.0000000000,0.0000000000) [0.0000000000|15.0000000000] ""  FLR_L,FRR_L
 SG_ TCU_ShiftPostionValid : 12|1@0+ (1.0000000000,0.0000000000) [0.0000000000|1.0000000000] ""  FLR_L,FRR_L

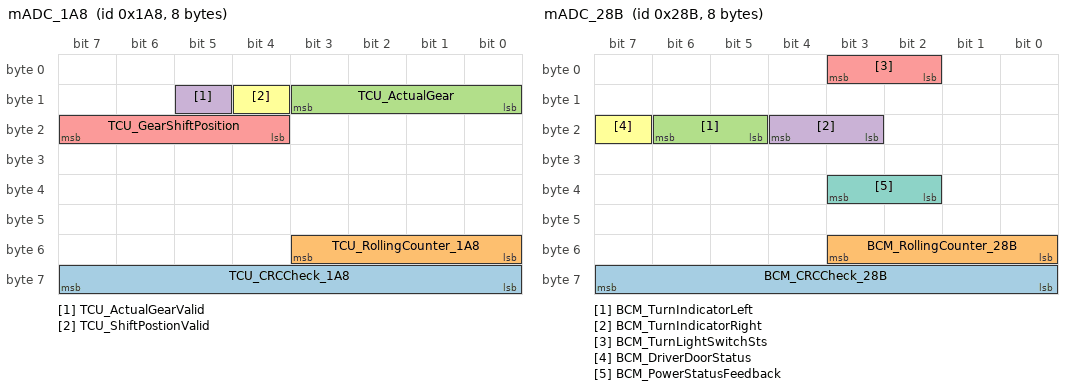
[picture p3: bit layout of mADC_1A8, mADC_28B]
BO_ 424 mADC_1A8: 8 mADC
 SG_ TCU_CRCCheck_1A8 : 63|8@0+ (1.0000000000,0.0000000000) [0.0000000000|255.0000000000] ""  FLR_L,FRR_L
 SG_ TCU_RollingCounter_1A8 : 51|4@0+ (1.0000000000,0.0000000000) [0.0000000000|15.0000000000] ""  FLR_L,FRR_L
 SG_ TCU_ActualGear : 11|4@0+ (1.0000000000,0.0000000000) [0.0000000000|15.0000000000] ""  FLR_L,FRR_L
 SG_ TCU_ActualGearValid : 13|1@0+ (1.0000000000,0.0000000000) [0.0000000000|1.0000000000] ""  FLR_L,FRR_L
 SG_ TCU_GearShiftPosition : 23|4@0+ (1.0000000000,0.0000000000) [0.0000000000|15.0000000000] ""  FLR_L,FRR_L
 SG_ TCU_ShiftPostionValid : 12|1@0+ (1.0000000000,0.0000000000) [0.0000000000|1.0000000000] ""  FLR_L,FRR_L

BO_ 796 mADC_31C: 8 mADC
 SG_ PCU_VcuRdySts : 16|1@0+ (1.0000000000,0.0000000000) [0.0000000000|1.0000000000] ""  FLR_L,FRR_L

BO_ 651 mADC_28B: 8 mADC
 SG_ BCM_CRCCheck_28B : 63|8@0+ (1.0000000000,0.0000000000) [0.0000000000|255.0000000000] ""  FLR_L,FRR_L
 SG_ BCM_RollingCounter_28B : 51|4@0+ (1.0000000000,0.0000000000) [0.0000000000|15.0000000000] ""  FLR_L,FRR_L
 SG_ BCM_TurnIndicatorLeft : 22|2@0+ (1.0000000000,0.0000000000) [0.0000000000|3.0000000000] ""  FLR_L,FRR_L
 SG_ BCM_TurnIndicatorRight : 20|2@0+ (1.0000000000,0.0000000000) [0.0000000000|3.0000000000] ""  FLR_L,FRR_L
 SG_ BCM_TurnLightSwitchSts : 3|2@0+ (1.0000000000,0.0000000000) [0.0000000000|3.0000000000] ""  FLR_L,FRR_L
 SG_ BCM_DriverDoorStatus : 23|1@0+ (1.0000000000,0.0000000000) [0.0000000000|1.0000000000] ""  FLR_L,FRR_L
 SG_ BCM_PowerStatusFeedback : 35|2@0+ (1.0000000000,0.0000000000) [0.0000000000|3.0000000000] ""  FLR_L,FRR_L

BO_ 271 mADC_10F: 8 mADC
 SG_ IBCU_sOutputRodAct_Q : 29|2@0+ (1.0000000000,0.0000000000) [0.0000000000|3.0000000000] ""  FLR_L,FRR_L
 SG_ IBCU_sOutputRodAct : 27|12@0+ (0.0156250000,-5.0000000000) [-5.0000000000|47.0000000000] "mm"  FLR_L,FRR_L

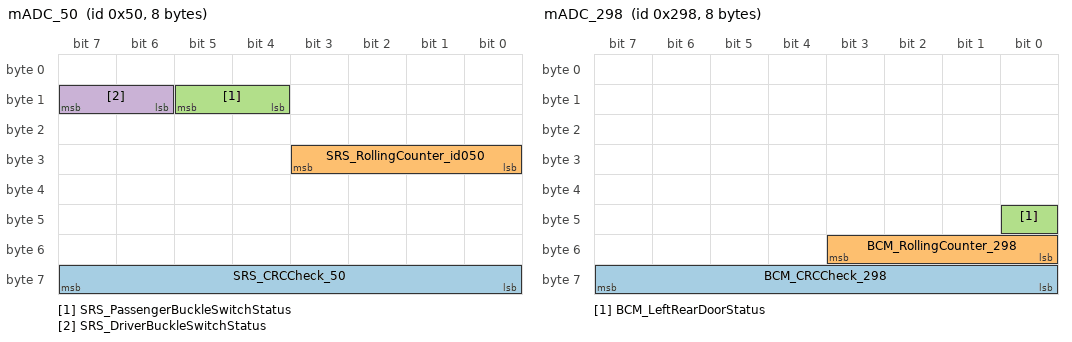
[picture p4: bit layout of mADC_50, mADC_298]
BO_ 80 mADC_50: 8 mADC
 SG_ SRS_CRCCheck_50 : 63|8@0+ (1.0000000000,0.0000000000) [0.0000000000|255.0000000000] ""  FLR_L,FRR_L
 SG_ SRS_RollingCounter_id050 : 27|4@0+ (1.0000000000,0.0000000000) [0.0000000000|15.0000000000] ""  FLR_L,FRR_L
 SG_ SRS_PassengerBuckleSwitchStatus : 13|2@0+ (1.0000000000,0.0000000000) [0.0000000000|3.0000000000] ""  FLR_L,FRR_L
 SG_ SRS_DriverBuckleSwitchStatus : 15|2@0+ (1.0000000000,0.0000000000) [0.0000000000|3.0000000000] ""  FLR_L,FRR_L

BO_ 664 mADC_298: 8 mADC
 SG_ BCM_CRCCheck_298 : 63|8@0+ (1.0000000000,0.0000000000) [0.0000000000|255.0000000000] ""  FLR_L,FRR_L
 SG_ BCM_RollingCounter_298 : 51|4@0+ (1.0000000000,0.0000000000) [0.0000000000|15.0000000000] ""  FLR_L,FRR_L
 SG_ BCM_LeftRearDoorStatus : 40|1@0+ (1.0000000000,0.0000000000) [0.0000000000|1.0000000000] ""  FLR_L,FRR_L

BO_ 721 mADC_2D1: 8 mADC
 SG_ BCM_RightRearDoorStatus : 38|1@0+ (1.0000000000,0.0000000000) [0.0000000000|1.0000000000] ""  FLR_L,FRR_L
 SG_ BCM_PassengerDoorStatus : 45|1@0+ (1.0000000000,0.0000000000) [0.0000000000|1.0000000000] ""  FLR_L,FRR_L

BO_ 587 mADC_24B: 64 mADC
 SG_ Transmitcnt6_R : 455|32@0+ (1.0000000000,0.0000000000) [0.0000000000|4294967295.0000000000] ""  FLR_L,FRR_L
 SG_ Transmitcnt5_R : 423|32@0+ (1.0000000000,0.0000000000) [0.0000000000|4294967295.0000000000] ""  FLR_L,FRR_L
 SG_ Transmitcnt4_R : 391|32@0+ (1.0000000000,0.0000000000) [0.0000000000|4294967295.0000000000] ""  FLR_L,FRR_L
 SG_ Transmitcnt3_R : 359|32@0+ (1.0000000000,0.0000000000) [0.0000000000|4294967295.0000000000] ""  FLR_L,FRR_L
 SG_ Transmitcnt2_R : 327|32@0+ (1.0000000000,0.0000000000) [0.0000000000|4294967295.0000000000] ""  FLR_L,FRR_L
 SG_ Transmitcnt1_R : 295|32@0+ (1.0000000000,0.0000000000) [0.0000000000|4294967295.0000000000] ""  FLR_L,FRR_L
 SG_ RLR_Track_ID_R : 270|7@0+ (1.0000000000,0.0000000000) [0.0000000000|127.0000000000] ""  FLR_L,FRR_L
 SG_ RLR_Measured_R : 273|2@0+ (1.0000000000,0.0000000000) [0.0000000000|3.0000000000] ""  FLR_L,FRR_L
 SG_ RLR_Location_R : 199|2@0+ (1.0000000000,0.0000000000) [0.0000000000|3.0000000000] ""  FLR_L,FRR_L
 SG_ RLR_ClassComfrmFlg_R : 271|1@0+ (1.0000000000,0.0000000000) [0.0000000000|1.0000000000] ""  FLR_L,FRR_L
 SG_ RLR_TrckrType_R : 197|3@0+ (1.0000000000,0.0000000000) [0.0000000000|7.0000000000] ""  FLR_L,FRR_L
 SG_ RLR_TrckrAge_R : 263|8@0+ (1.0000000000,0.0000000000) [0.0000000000|255.0000000000] ""  FLR_L,FRR_L
 SG_ RLR_MotionStatus_R : 194|3@0+ (1.0000000000,0.0000000000) [0.0000000000|7.0000000000] ""  FLR_L,FRR_L
 SG_ RLR_AbsVy_R : 207|12@0+ (0.0625000000,-128.0000000000) [-128.0000000000|127.9380000000] "m/s"  FLR_L,FRR_L
 SG_ RLR_AbsoVx_R : 211|10@0+ (0.1250000000,-64.0000000000) [-64.0000000000|63.8750000000] "m/s"  FLR_L,FRR_L
 SG_ RLR_LocDx_R : 217|13@0+ (0.0625000000,-256.0000000000) [-256.0000000000|255.9380000000] "m"  FLR_L,FRR_L
 SG_ RLR_LocDy_R : 236|11@0+ (0.1250000000,-128.0000000000) [-128.0000000000|127.8750000000] "m"  FLR_L,FRR_L
 SG_ RLR_HeadingAngle_R : 241|10@0+ (0.0100000000,-3.1400000000) [-3.1400000000|3.1400000000] "rad"  FLR_L,FRR_L
 SG_ RLR_Length_R : 132|9@0+ (0.0500000000,0.0000000000) [0.0000000000|25.5000000000] "m"  FLR_L,FRR_L
 SG_ RLR_Width_R : 139|11@0+ (0.0100000000,0.0000000000) [0.0000000000|12.0000000000] "m"  FLR_L,FRR_L
 SG_ RLR_Track_ID_L : 144|7@0+ (1.0000000000,0.0000000000) [0.0000000000|127.0000000000] ""  FLR_L,FRR_L
 SG_ RLR_Measured_L : 153|2@0+ (1.0000000000,0.0000000000) [0.0000000000|3.0000000000] ""  FLR_L,FRR_L
 SG_ RLR_Location_L : 167|2@0+ (1.0000000000,0.0000000000) [0.0000000000|3.0000000000] ""  FLR_L,FRR_L
 SG_ RLR_ClassComfrmFlg_L : 164|1@0+ (1.0000000000,0.0000000000) [0.0000000000|1.0000000000] ""  FLR_L,FRR_L
 SG_ RLR_TrckrType_L : 163|3@0+ (1.0000000000,0.0000000000) [0.0000000000|7.0000000000] ""  FLR_L,FRR_L
 SG_ RLR_TrckrAge_L : 71|8@0+ (1.0000000000,0.0000000000) [0.0000000000|255.0000000000] ""  FLR_L,FRR_L
 SG_ RLR_MotionStatus_L : 160|3@0+ (1.0000000000,0.0000000000) [0.0000000000|7.0000000000] ""  FLR_L,FRR_L
 SG_ RLR_AbsVy_L : 173|12@0+ (0.0625000000,-128.0000000000) [-128.0000000000|127.9380000000] "m/s"  FLR_L,FRR_L
 SG_ RLR_AbsoVx_L : 177|10@0+ (0.1250000000,-64.0000000000) [-64.0000000000|63.8750000000] "m/s"  FLR_L,FRR_L
 SG_ RLR_LocDx_L : 79|13@0+ (0.0625000000,-256.0000000000) [-256.0000000000|255.9380000000] "m"  FLR_L,FRR_L
 SG_ RLR_LocDy_L : 82|11@0+ (0.1250000000,-128.0000000000) [-128.0000000000|127.8750000000] "m"  FLR_L,FRR_L
 SG_ RLR_HeadingAngle_L : 103|10@0+ (0.0100000000,-3.1400000000) [-3.1400000000|3.1400000000] "rad"  FLR_L,FRR_L
 SG_ RLR_Length_L : 109|9@0+ (0.0500000000,0.0000000000) [0.0000000000|25.5000000000] "m"  FLR_L,FRR_L
 SG_ RLR_Width_L : 116|11@0+ (0.0100000000,0.0000000000) [0.0000000000|12.0000000000] "m"  FLR_L,FRR_L
 SG_ RLR_TrckrNum : 121|2@0+ (1.0000000000,0.0000000000) [0.0000000000|3.0000000000] ""  FLR_L,FRR_L
 SG_ RLR_TrackerTimeStamp : 7|64@0+ (0.0001000000,0.0000000000) [0.0000000000|429496.7295000000] ""  FLR_L,FRR_L

BO_ 1894 mADC_766: 64 mADC

BO_ 1902 FLR_L_76E: 8 FLR_L

BO_ 1895 mADC_767: 64 mADC

BO_ 1903 FRR_L_76F: 8 FRR_L

BO_ 1104 mADC_450: 8 mADC

BO_ 1110 FRR_L_456: 8 FRR_L

BO_ 1111 FLR_L_457: 8 FLR_L

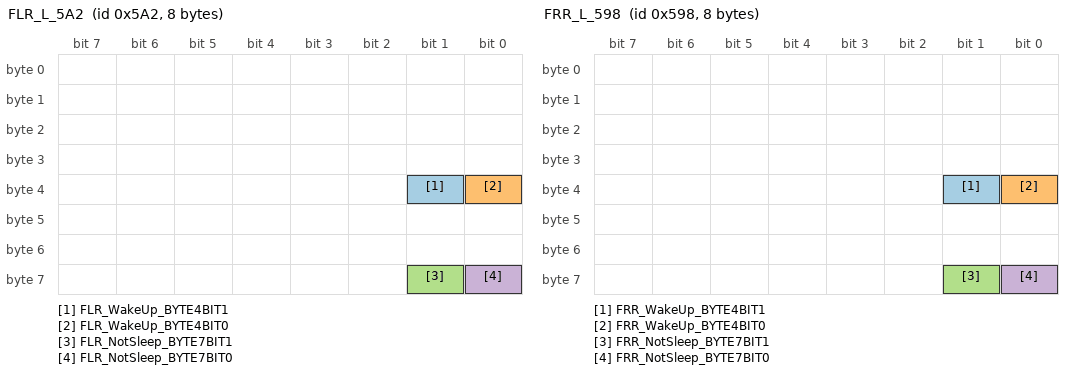
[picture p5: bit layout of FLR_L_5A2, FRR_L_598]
BO_ 1442 FLR_L_5A2: 8 FLR_L
 SG_ FLR_WakeUp_BYTE4BIT1 : 33|1@0+ (1.0000000000,0.0000000000) [0.0000000000|1.0000000000] ""  FRR_L,mADC
 SG_ FLR_WakeUp_BYTE4BIT0 : 32|1@0+ (1.0000000000,0.0000000000) [0.0000000000|1.0000000000] ""  FRR_L,mADC
 SG_ FLR_NotSleep_BYTE7BIT1 : 57|1@0+ (1.0000000000,0.0000000000) [0.0000000000|1.0000000000] ""  FRR_L,mADC
 SG_ FLR_NotSleep_BYTE7BIT0 : 56|1@0+ (1.0000000000,0.0000000000) [0.0000000000|1.0000000000] ""  FRR_L,mADC

BO_ 1432 FRR_L_598: 8 FRR_L
 SG_ FRR_WakeUp_BYTE4BIT1 : 33|1@0+ (1.0000000000,0.0000000000) [0.0000000000|1.0000000000] ""  FLR_L,mADC
 SG_ FRR_WakeUp_BYTE4BIT0 : 32|1@0+ (1.0000000000,0.0000000000) [0.0000000000|1.0000000000] ""  FLR_L,mADC
 SG_ FRR_NotSleep_BYTE7BIT1 : 57|1@0+ (1.0000000000,0.0000000000) [0.0000000000|1.0000000000] ""  FLR_L,mADC
 SG_ FRR_NotSleep_BYTE7BIT0 : 56|1@0+ (1.0000000000,0.0000000000) [0.0000000000|1.0000000000] ""  FLR_L,mADC

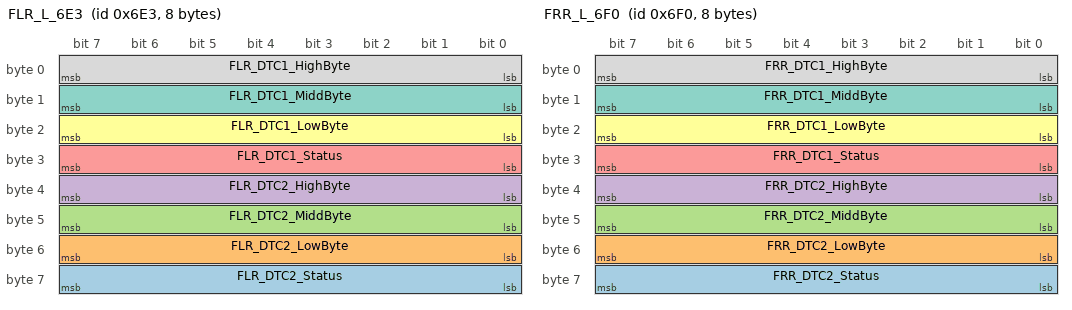
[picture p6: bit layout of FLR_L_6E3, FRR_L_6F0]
BO_ 1763 FLR_L_6E3: 8 FLR_L
 SG_ FLR_DTC2_Status : 63|8@0+ (1.0000000000,0.0000000000) [0.0000000000|255.0000000000] ""  FRR_L,mADC
 SG_ FLR_DTC2_LowByte : 55|8@0+ (1.0000000000,0.0000000000) [0.0000000000|255.0000000000] ""  FRR_L,mADC
 SG_ FLR_DTC2_MiddByte : 47|8@0+ (1.0000000000,0.0000000000) [0.0000000000|255.0000000000] ""  FRR_L,mADC
 SG_ FLR_DTC2_HighByte : 39|8@0+ (1.0000000000,0.0000000000) [0.0000000000|255.0000000000] ""  FRR_L,mADC
 SG_ FLR_DTC1_Status : 31|8@0+ (1.0000000000,0.0000000000) [0.0000000000|255.0000000000] ""  FRR_L,mADC
 SG_ FLR_DTC1_LowByte : 23|8@0+ (1.0000000000,0.0000000000) [0.0000000000|255.0000000000] ""  FRR_L,mADC
 SG_ FLR_DTC1_MiddByte : 15|8@0+ (1.0000000000,0.0000000000) [0.0000000000|255.0000000000] ""  FRR_L,mADC
 SG_ FLR_DTC1_HighByte : 7|8@0+ (1.0000000000,0.0000000000) [0.0000000000|255.0000000000] ""  FRR_L,mADC

BO_ 1776 FRR_L_6F0: 8 FRR_L
 SG_ FRR_DTC2_Status : 63|8@0+ (1.0000000000,0.0000000000) [0.0000000000|255.0000000000] ""  FLR_L,mADC
 SG_ FRR_DTC2_LowByte : 55|8@0+ (1.0000000000,0.0000000000) [0.0000000000|255.0000000000] ""  FLR_L,mADC
 SG_ FRR_DTC2_MiddByte : 47|8@0+ (1.0000000000,0.0000000000) [0.0000000000|255.0000000000] ""  FLR_L,mADC
 SG_ FRR_DTC2_HighByte : 39|8@0+ (1.0000000000,0.0000000000) [0.0000000000|255.0000000000] ""  FLR_L,mADC
 SG_ FRR_DTC1_Status : 31|8@0+ (1.0000000000,0.0000000000) [0.0000000000|255.0000000000] ""  FLR_L,mADC
 SG_ FRR_DTC1_LowByte : 23|8@0+ (1.0000000000,0.0000000000) [0.0000000000|255.0000000000] ""  FLR_L,mADC
 SG_ FRR_DTC1_MiddByte : 15|8@0+ (1.0000000000,0.0000000000) [0.0000000000|255.0000000000] ""  FLR_L,mADC
 SG_ FRR_DTC1_HighByte : 7|8@0+ (1.0000000000,0.0000000000) [0.0000000000|255.0000000000] ""  FLR_L,mADC

BO_ 623 mADC_26F: 64 mADC
 SG_ FC_Line_4_exist_prob : 477|6@0+ (2.0000000000,0.0000000000) [0.0000000000|100.0000000000] "%"  FLR_L,FRR_L
 SG_ FC_Line_4_MeasureType : 386|3@0+ (1.0000000000,0.0000000000) [0.0000000000|7.0000000000] "-"  FLR_L,FRR_L
 SG_ FC_Line_4_ModelC3 : 457|12@0+ (0.0000001272,-0.0002604200) [-0.0002604200|0.0002604170] "1/m2"  FLR_L,FRR_L
 SG_ FC_Line_4_ModelC2 : 455|14@0+ (0.0000019074,-0.0156250000) [-0.0156250000|0.0156212077] "1/m"  FLR_L,FRR_L
 SG_ FC_Line_4_ModelC1 : 436|13@0+ (0.0004882810,-1.6000000000) [-1.6000000000|1.6000000000] "rad"  FLR_L,FRR_L
 SG_ FC_Line_4_ModelC0 : 416|12@0+ (0.0156250000,-32.0000000000) [-32.0000000000|31.9843750000] "m"  FLR_L,FRR_L
 SG_ FC_Line_4_dx_End : 410|10@0+ (0.2500000000,0.0000000000) [0.0000000000|255.7500000000] "m"  FLR_L,FRR_L
 SG_ FC_Line_4_dx_Start : 407|13@0+ (0.0250000000,0.0000000000) [0.0000000000|204.7750000000] "m"  FLR_L,FRR_L
 SG_ FC_Line_4_Id : 399|8@0+ (1.0000000000,0.0000000000) [1.0000000000|255.0000000000] ""  FLR_L,FRR_L
 SG_ FC_Line_4_Type : 391|5@0+ (1.0000000000,0.0000000000) [0.0000000000|31.0000000000] ""  FLR_L,FRR_L
 SG_ FC_Line_3_exist_prob : 349|6@0+ (2.0000000000,0.0000000000) [0.0000000000|100.0000000000] "%"  FLR_L,FRR_L
 SG_ FC_Line_3_MeasureType : 258|3@0+ (1.0000000000,0.0000000000) [0.0000000000|7.0000000000] "-"  FLR_L,FRR_L
 SG_ FC_Line_3_ModelC3 : 329|12@0+ (0.0000001272,-0.0002604200) [-0.0002604200|0.0002604170] "1/m2"  FLR_L,FRR_L
 SG_ FC_Line_3_ModelC2 : 327|14@0+ (0.0000019074,-0.0156250000) [-0.0156250000|0.0156212077] "1/m"  FLR_L,FRR_L
 SG_ FC_Line_3_ModelC1 : 308|13@0+ (0.0004882810,-1.6000000000) [-1.6000000000|1.6000000000] "rad"  FLR_L,FRR_L
 SG_ FC_Line_3_ModelC0 : 288|12@0+ (0.0156250000,-32.0000000000) [-32.0000000000|31.9843750000] "m"  FLR_L,FRR_L
 SG_ FC_Line_3_dx_End : 282|10@0+ (0.2500000000,0.0000000000) [0.0000000000|255.7500000000] "m"  FLR_L,FRR_L
 SG_ FC_Line_3_dx_Start : 279|13@0+ (0.0250000000,0.0000000000) [0.0000000000|204.7750000000] "m"  FLR_L,FRR_L
 SG_ FC_Line_3_Id : 271|8@0+ (1.0000000000,0.0000000000) [1.0000000000|255.0000000000] ""  FLR_L,FRR_L
 SG_ FC_Line_3_Type : 263|5@0+ (1.0000000000,0.0000000000) [0.0000000000|31.0000000000] ""  FLR_L,FRR_L
 SG_ FC_Line_2_exist_prob : 221|6@0+ (2.0000000000,0.0000000000) [0.0000000000|100.0000000000] "%"  FLR_L,FRR_L
 SG_ FC_Line_2_MeasureType : 130|3@0+ (1.0000000000,0.0000000000) [0.0000000000|7.0000000000] "-"  FLR_L,FRR_L
 SG_ FC_Line_2_ModelC3 : 201|12@0+ (0.0000001272,-0.0002604200) [-0.0002604200|0.0002604170] "1/m2"  FLR_L,FRR_L
 SG_ FC_Line_2_ModelC2 : 199|14@0+ (0.0000019074,-0.0156250000) [-0.0156250000|0.0156212077] "1/m"  FLR_L,FRR_L
 SG_ FC_Line_2_ModelC1 : 180|13@0+ (0.0004882810,-1.6000000000) [-1.6000000000|1.6000000000] "rad"  FLR_L,FRR_L
 SG_ FC_Line_2_ModelC0 : 160|12@0+ (0.0156250000,-32.0000000000) [-32.0000000000|31.9843750000] "m"  FLR_L,FRR_L
 SG_ FC_Line_2_dx_End : 154|10@0+ (0.2500000000,0.0000000000) [0.0000000000|255.7500000000] "m"  FLR_L,FRR_L
 SG_ FC_Line_2_dx_Start : 151|13@0+ (0.0250000000,0.0000000000) [0.0000000000|204.7750000000] "m"  FLR_L,FRR_L
 SG_ FC_Line_2_Id : 143|8@0+ (1.0000000000,0.0000000000) [1.0000000000|255.0000000000] ""  FLR_L,FRR_L
 SG_ FC_Line_2_Type : 135|5@0+ (1.0000000000,0.0000000000) [0.0000000000|31.0000000000] ""  FLR_L,FRR_L
 SG_ FC_Line_1_exist_prob : 93|6@0+ (2.0000000000,0.0000000000) [0.0000000000|100.0000000000] "%"  FLR_L,FRR_L
 SG_ FC_Line_1_MeasureType : 2|3@0+ (1.0000000000,0.0000000000) [0.0000000000|7.0000000000] "-"  FLR_L,FRR_L
 SG_ FC_Line_1_ModelC3 : 73|12@0+ (0.0000001272,-0.0002604200) [-0.0002604200|0.0002604170] "1/m2"  FLR_L,FRR_L
 SG_ FC_Line_1_ModelC2 : 71|14@0+ (0.0000019074,-0.0156250000) [-0.0156250000|0.0156212077] "1/m"  FLR_L,FRR_L
 SG_ FC_Line_1_ModelC1 : 52|13@0+ (0.0004882810,-1.6000000000) [-1.6000000000|1.6000000000] "rad"  FLR_L,FRR_L
 SG_ FC_Line_1_ModelC0 : 32|12@0+ (0.0156250000,-32.0000000000) [-32.0000000000|31.9843750000] "m"  FLR_L,FRR_L
 SG_ FC_Line_1_dx_End : 26|10@0+ (0.2500000000,0.0000000000) [0.0000000000|255.7500000000] "m"  FLR_L,FRR_L
 SG_ FC_Line_1_dx_Start : 23|13@0+ (0.0250000000,0.0000000000) [0.0000000000|204.7750000000] "m"  FLR_L,FRR_L
 SG_ FC_Line_1_Id : 15|8@0+ (1.0000000000,0.0000000000) [1.0000000000|255.0000000000] ""  FLR_L,FRR_L
 SG_ FC_Line_1_Type : 7|5@0+ (1.0000000000,0.0000000000) [0.0000000000|31.0000000000] ""  FLR_L,FRR_L

BO_ 697 FLR_L_2B9: 64 FLR_L
 SG_ RLR_CRCCheck_2B9 : 503|16@0+ (1.0000000000,0.0000000000) [0.0000000000|65535.0000000000] ""  FRR_L,mADC
 SG_ RLR_RollingCounter_2B9 : 491|4@0+ (1.0000000000,0.0000000000) [0.0000000000|15.0000000000] ""  FRR_L,mADC
 SG_ FLR_OBJ32_Ax : 333|10@0+ (0.0312500000,-16.0000000000) [-16.0000000000|15.9688000000] "m/s2"  FRR_L,mADC
 SG_ FLR_OBJ31_Ax : 327|10@0+ (0.0312500000,-16.0000000000) [-16.0000000000|15.9688000000] "m/s2"  FRR_L,mADC
 SG_ FLR_OBJ30_Ax : 309|10@0+ (0.0312500000,-16.0000000000) [-16.0000000000|15.9688000000] "m/s2"  FRR_L,mADC
 SG_ FLR_OBJ29_Ax : 303|10@0+ (0.0312500000,-16.0000000000) [-16.0000000000|15.9688000000] "m/s2"  FRR_L,mADC
 SG_ FLR_OBJ28_Ax : 281|10@0+ (0.0312500000,-16.0000000000) [-16.0000000000|15.9688000000] "m/s2"  FRR_L,mADC
 SG_ FLR_OBJ27_Ax : 275|10@0+ (0.0312500000,-16.0000000000) [-16.0000000000|15.9688000000] "m/s2"  FRR_L,mADC
 SG_ FLR_OBJ26_Ax : 269|10@0+ (0.0312500000,-16.0000000000) [-16.0000000000|15.9688000000] "m/s2"  FRR_L,mADC
 SG_ FLR_OBJ25_Ax : 263|10@0+ (0.0312500000,-16.0000000000) [-16.0000000000|15.9688000000] "m/s2"  FRR_L,mADC
 SG_ FLR_OBJ24_Ax : 245|10@0+ (0.0312500000,-16.0000000000) [-16.0000000000|15.9688000000] "m/s2"  FRR_L,mADC
 SG_ FLR_OBJ23_Ax : 239|10@0+ (0.0312500000,-16.0000000000) [-16.0000000000|15.9688000000] "m/s2"  FRR_L,mADC
 SG_ FLR_OBJ22_Ax : 217|10@0+ (0.0312500000,-16.0000000000) [-16.0000000000|15.9688000000] "m/s2"  FRR_L,mADC
 SG_ FLR_OBJ21_Ax : 211|10@0+ (0.0312500000,-16.0000000000) [-16.0000000000|15.9688000000] "m/s2"  FRR_L,mADC
 SG_ FLR_OBJ20_Ax : 205|10@0+ (0.0312500000,-16.0000000000) [-16.0000000000|15.9688000000] "m/s2"  FRR_L,mADC
 SG_ FLR_OBJ19_Ax : 199|10@0+ (0.0312500000,-16.0000000000) [-16.0000000000|15.9688000000] "m/s2"  FRR_L,mADC
 SG_ FLR_OBJ18_Ax : 181|10@0+ (0.0312500000,-16.0000000000) [-16.0000000000|15.9688000000] "m/s2"  FRR_L,mADC
 SG_ FLR_OBJ17_Ax : 175|10@0+ (0.0312500000,-16.0000000000) [-16.0000000000|15.9688000000] "m/s2"  FRR_L,mADC
 SG_ FLR_OBJ16_Ax : 153|10@0+ (0.0312500000,-16.0000000000) [-16.0000000000|15.9688000000] "m/s2"  FRR_L,mADC
 SG_ FLR_OBJ15_Ax : 147|10@0+ (0.0312500000,-16.0000000000) [-16.0000000000|15.9688000000] "m/s2"  FRR_L,mADC
 SG_ FLR_OBJ14_Ax : 141|10@0+ (0.0312500000,-16.0000000000) [-16.0000000000|15.9688000000] "m/s2"  FRR_L,mADC
 SG_ FLR_OBJ13_Ax : 135|10@0+ (0.0312500000,-16.0000000000) [-16.0000000000|15.9688000000] "m/s2"  FRR_L,mADC
 SG_ FLR_OBJ12_Ax : 117|10@0+ (0.0312500000,-16.0000000000) [-16.0000000000|15.9688000000] "m/s2"  FRR_L,mADC
 SG_ FLR_OBJ11_Ax : 111|10@0+ (0.0312500000,-16.0000000000) [-16.0000000000|15.9688000000] "m/s2"  FRR_L,mADC
 SG_ FLR_OBJ10_Ax : 89|10@0+ (0.0312500000,-16.0000000000) [-16.0000000000|15.9688000000] "m/s2"  FRR_L,mADC
 SG_ FLR_OBJ9_Ax : 83|10@0+ (0.0312500000,-16.0000000000) [-16.0000000000|15.9688000000] "m/s2"  FRR_L,mADC
 SG_ FLR_OBJ8_Ax : 77|10@0+ (0.0312500000,-16.0000000000) [-16.0000000000|15.9688000000] "m/s2"  FRR_L,mADC
 SG_ FLR_OBJ7_Ax : 71|10@0+ (0.0312500000,-16.0000000000) [-16.0000000000|15.9688000000] "m/s2"  FRR_L,mADC
 SG_ FLR_OBJ6_Ax : 53|10@0+ (0.0312500000,-16.0000000000) [-16.0000000000|15.9688000000] "m/s2"  FRR_L,mADC
 SG_ FLR_OBJ5_Ax : 47|10@0+ (0.0312500000,-16.0000000000) [-16.0000000000|15.9688000000] "m/s2"  FRR_L,mADC
 SG_ FLR_OBJ4_Ax : 25|10@0+ (0.0312500000,-16.0000000000) [-16.0000000000|15.9688000000] "m/s2"  FRR_L,mADC
 SG_ FLR_OBJ3_Ax : 19|10@0+ (0.0312500000,-16.0000000000) [-16.0000000000|15.9688000000] "m/s2"  FRR_L,mADC
 SG_ FLR_OBJ2_Ax : 13|10@0+ (0.0312500000,-16.0000000000) [-16.0000000000|15.9688000000] "m/s2"  FRR_L,mADC
 SG_ FLR_OBJ1_Ax : 7|10@0+ (0.0312500000,-16.0000000000) [-16.0000000000|15.9688000000] "m/s2"  FRR_L,mADC

BO_ 957 mADC_3BD: 64 mADC
 SG_ HU_AsistantSysteSwitch : 365|2@0+ (1.0000000000,0.0000000000) [0.0000000000|2.0000000000] ""  FLR_L,FRR_L

CM_ BO_ 669  " ";
CM_ SG_ 669 FLR_CRCCheck_29D  " ";
CM_ SG_ 669 FLR_RollingCounter_29D  " ";
CM_ SG_ 669 FLR_FreespaceSectorKinestate136  " ";
CM_ SG_ 669 FLR_FreespaceSectorConfidence136  " ";
CM_ SG_ 669 FLR_FreespaceSectorDistance136  " ";
CM_ SG_ 669 FLR_FreespaceSectorKinestate135  " ";
CM_ SG_ 669 FLR_FreespaceSectorConfidence135  " ";
CM_ SG_ 669 FLR_FreespaceSectorDistance135  " ";
CM_ SG_ 669 FLR_FreespaceSectorKinestate134  " ";
CM_ SG_ 669 FLR_FreespaceSectorConfidence134  " ";
CM_ SG_ 669 FLR_FreespaceSectorDistance134  " ";
CM_ SG_ 669 FLR_FreespaceSectorKinestate133  " ";
CM_ SG_ 669 FLR_FreespaceSectorConfidence133  " ";
CM_ SG_ 669 FLR_FreespaceSectorDistance133  " ";
CM_ SG_ 669 FLR_FreespaceSectorKinestate132  " ";
CM_ SG_ 669 FLR_FreespaceSectorConfidence132  " ";
CM_ SG_ 669 FLR_FreespaceSectorDistance132  " ";
CM_ SG_ 669 FLR_FreespaceSectorKinestate131  " ";
CM_ SG_ 669 FLR_FreespaceSectorConfidence131  " ";
CM_ SG_ 669 FLR_FreespaceSectorDistance131  " ";
CM_ SG_ 669 FLR_FreespaceSectorKinestate130  " ";
CM_ SG_ 669 FLR_FreespaceSectorConfidence130  " ";
CM_ SG_ 669 FLR_FreespaceSectorDistance130  " ";
CM_ SG_ 669 FLR_FreespaceSectorKinestate129  " ";
CM_ SG_ 669 FLR_FreespaceSectorConfidence129  " ";
CM_ SG_ 669 FLR_FreespaceSectorDistance129  " ";
CM_ SG_ 669 FLR_FreespaceSectorKinestate128  " ";
CM_ SG_ 669 FLR_FreespaceSectorConfidence128  " ";
CM_ SG_ 669 FLR_FreespaceSectorDistance128  " ";
CM_ SG_ 669 FLR_FreespaceSectorKinestate127  " ";
CM_ SG_ 669 FLR_FreespaceSectorConfidence127  " ";
CM_ SG_ 669 FLR_FreespaceSectorDistance127  " ";
CM_ SG_ 669 FLR_FreespaceSectorKinestate126  " ";
CM_ SG_ 669 FLR_FreespaceSectorConfidence126  " ";
CM_ SG_ 669 FLR_FreespaceSectorDistance126  " ";
CM_ SG_ 669 FLR_FreespaceSectorKinestate125  " ";
CM_ SG_ 669 FLR_FreespaceSectorConfidence125  " ";
CM_ SG_ 669 FLR_FreespaceSectorDistance125  " ";
CM_ SG_ 669 FLR_FreespaceSectorKinestate124  " ";
CM_ SG_ 669 FLR_FreespaceSectorConfidence124  " ";
CM_ SG_ 669 FLR_FreespaceSectorDistance124  " ";
CM_ SG_ 669 FLR_FreespaceSectorKinestate123  " ";
CM_ SG_ 669 FLR_FreespaceSectorConfidence123  " ";
CM_ SG_ 669 FLR_FreespaceSectorDistance123  " ";
CM_ SG_ 669 FLR_FreespaceSectorKinestate122  " ";
CM_ SG_ 669 FLR_FreespaceSectorConfidence122  " ";
CM_ SG_ 669 FLR_FreespaceSectorDistance122  " ";
CM_ SG_ 669 FLR_FreespaceSectorKinestate121  " ";
CM_ SG_ 669 FLR_FreespaceSectorConfidence121  " ";
CM_ SG_ 669 FLR_FreespaceSectorDistance121  " ";
CM_ SG_ 669 FLR_FreespaceSectorKinestate120  " ";
CM_ SG_ 669 FLR_FreespaceSectorConfidence120  " ";
CM_ SG_ 669 FLR_FreespaceSectorDistance120  " ";
CM_ SG_ 669 FLR_FreespaceSectorKinestate119  " ";
CM_ SG_ 669 FLR_FreespaceSectorConfidence119  " ";
CM_ SG_ 669 FLR_FreespaceSectorDistance119  " ";
CM_ SG_ 669 FLR_FreespaceSectorKinestate118  " ";
CM_ SG_ 669 FLR_FreespaceSectorConfidence118  " ";
CM_ SG_ 669 FLR_FreespaceSectorDistance118  " ";
CM_ SG_ 669 FLR_FreespaceSectorKinestate117  " ";
CM_ SG_ 669 FLR_FreespaceSectorConfidence117  " ";
CM_ SG_ 669 FLR_FreespaceSectorDistance117  " ";
CM_ SG_ 669 FLR_FreespaceSectorKinestate116  " ";
CM_ SG_ 669 FLR_FreespaceSectorConfidence116  " ";
CM_ SG_ 669 FLR_FreespaceSectorDistance116  " ";
CM_ SG_ 669 FLR_FreespaceSectorKinestate115  " ";
CM_ SG_ 669 FLR_FreespaceSectorConfidence115  " ";
CM_ SG_ 669 FLR_FreespaceSectorDistance115  " ";
CM_ SG_ 669 FLR_FreespaceSectorKinestate114  " ";
CM_ SG_ 669 FLR_FreespaceSectorConfidence114  " ";
CM_ SG_ 669 FLR_FreespaceSectorDistance114  " ";
CM_ SG_ 669 FLR_FreespaceSectorKinestate113  " ";
CM_ SG_ 669 FLR_FreespaceSectorConfidence113  " ";
CM_ SG_ 669 FLR_FreespaceSectorDistance113  " ";
CM_ SG_ 669 FLR_FreespaceSectorKinestate112  " ";
CM_ SG_ 669 FLR_FreespaceSectorConfidence112  " ";
CM_ SG_ 669 FLR_FreespaceSectorDistance112  " ";
CM_ SG_ 669 FLR_FreespaceSectorKinestate111  " ";
CM_ SG_ 669 FLR_FreespaceSectorConfidence111  " ";
CM_ SG_ 669 FLR_FreespaceSectorDistance111  " ";
CM_ SG_ 669 FLR_FreespaceSectorKinestate110  " ";
CM_ SG_ 669 FLR_FreespaceSectorConfidence110  " ";
CM_ SG_ 669 FLR_FreespaceSectorDistance110  " ";
CM_ SG_ 669 FLR_FreespaceSectorKinestate109  " ";
CM_ SG_ 669 FLR_FreespaceSectorConfidence109  " ";
CM_ SG_ 669 FLR_FreespaceSectorDistance109  " ";
CM_ SG_ 669 FLR_FreespaceSectorKinestate108  " ";
CM_ SG_ 669 FLR_FreespaceSectorConfidence108  " ";
CM_ SG_ 669 FLR_FreespaceSectorDistance108  " ";
CM_ SG_ 669 FLR_FreespaceSectorKinestate107  " ";
CM_ SG_ 669 FLR_FreespaceSectorConfidence107  " ";
CM_ SG_ 669 FLR_FreespaceSectorDistance107  " ";
CM_ SG_ 669 FLR_FreespaceSectorKinestate106  " ";
CM_ SG_ 669 FLR_FreespaceSectorConfidence106  " ";
CM_ SG_ 669 FLR_FreespaceSectorDistance106  " ";
CM_ SG_ 669 FLR_FreespaceSectorKinestate105  " ";
CM_ SG_ 669 FLR_FreespaceSectorConfidence105  " ";
CM_ SG_ 669 FLR_FreespaceSectorDistance105  " ";
CM_ SG_ 669 FLR_FreespaceSectorKinestate104  " ";
CM_ SG_ 669 FLR_FreespaceSectorConfidence104  " ";
CM_ SG_ 669 FLR_FreespaceSectorDistance104  " ";
CM_ SG_ 669 FLR_FreespaceSectorKinestate103  " ";
CM_ SG_ 669 FLR_FreespaceSectorConfidence103  " ";
CM_ SG_ 669 FLR_FreespaceSectorDistance103  " ";

CM_ BO_ 670  " ";
CM_ SG_ 670 FLR_CRCCheck_29E  " ";
CM_ SG_ 670 FLR_RollingCounter_29E  " ";
CM_ SG_ 670 FLR_FreespaceSectorKinestate170  " ";
CM_ SG_ 670 FLR_FreespaceSectorConfidence170  " ";
CM_ SG_ 670 FLR_FreespaceSectorDistance170  " ";
CM_ SG_ 670 FLR_FreespaceSectorKinestate169  " ";
CM_ SG_ 670 FLR_FreespaceSectorConfidence169  " ";
CM_ SG_ 670 FLR_FreespaceSectorDistance169  " ";
CM_ SG_ 670 FLR_FreespaceSectorKinestate168  " ";
CM_ SG_ 670 FLR_FreespaceSectorConfidence168  " ";
CM_ SG_ 670 FLR_FreespaceSectorDistance168  " ";
CM_ SG_ 670 FLR_FreespaceSectorKinestate167  " ";
CM_ SG_ 670 FLR_FreespaceSectorConfidence167  " ";
CM_ SG_ 670 FLR_FreespaceSectorDistance167  " ";
CM_ SG_ 670 FLR_FreespaceSectorKinestate166  " ";
CM_ SG_ 670 FLR_FreespaceSectorConfidence166  " ";
CM_ SG_ 670 FLR_FreespaceSectorDistance166  " ";
CM_ SG_ 670 FLR_FreespaceSectorKinestate165  " ";
CM_ SG_ 670 FLR_FreespaceSectorConfidence165  " ";
CM_ SG_ 670 FLR_FreespaceSectorDistance165  " ";
CM_ SG_ 670 FLR_FreespaceSectorKinestate164  " ";
CM_ SG_ 670 FLR_FreespaceSectorConfidence164  " ";
CM_ SG_ 670 FLR_FreespaceSectorDistance164  " ";
CM_ SG_ 670 FLR_FreespaceSectorKinestate163  " ";
CM_ SG_ 670 FLR_FreespaceSectorConfidence163  " ";
CM_ SG_ 670 FLR_FreespaceSectorDistance163  " ";
CM_ SG_ 670 FLR_FreespaceSectorKinestate162  " ";
CM_ SG_ 670 FLR_FreespaceSectorConfidence162  " ";
CM_ SG_ 670 FLR_FreespaceSectorDistance162  " ";
CM_ SG_ 670 FLR_FreespaceSectorKinestate161  " ";
CM_ SG_ 670 FLR_FreespaceSectorConfidence161  " ";
CM_ SG_ 670 FLR_FreespaceSectorDistance161  " ";
CM_ SG_ 670 FLR_FreespaceSectorKinestate160  " ";
CM_ SG_ 670 FLR_FreespaceSectorConfidence160  " ";
CM_ SG_ 670 FLR_FreespaceSectorDistance160  " ";
CM_ SG_ 670 FLR_FreespaceSectorKinestate159  " ";
CM_ SG_ 670 FLR_FreespaceSectorConfidence159  " ";
CM_ SG_ 670 FLR_FreespaceSectorDistance159  " ";
CM_ SG_ 670 FLR_FreespaceSectorKinestate158  " ";
CM_ SG_ 670 FLR_FreespaceSectorConfidence158  " ";
CM_ SG_ 670 FLR_FreespaceSectorDistance158  " ";
CM_ SG_ 670 FLR_FreespaceSectorKinestate157  " ";
CM_ SG_ 670 FLR_FreespaceSectorConfidence157  " ";
CM_ SG_ 670 FLR_FreespaceSectorDistance157  " ";
CM_ SG_ 670 FLR_FreespaceSectorKinestate156  " ";
CM_ SG_ 670 FLR_FreespaceSectorConfidence156  " ";
CM_ SG_ 670 FLR_FreespaceSectorDistance156  " ";
CM_ SG_ 670 FLR_FreespaceSectorKinestate155  " ";
CM_ SG_ 670 FLR_FreespaceSectorConfidence155  " ";
CM_ SG_ 670 FLR_FreespaceSectorDistance155  " ";
CM_ SG_ 670 FLR_FreespaceSectorKinestate154  " ";
CM_ SG_ 670 FLR_FreespaceSectorConfidence154  " ";
CM_ SG_ 670 FLR_FreespaceSectorDistance154  " ";
CM_ SG_ 670 FLR_FreespaceSectorKinestate153  " ";
CM_ SG_ 670 FLR_FreespaceSectorConfidence153  " ";
CM_ SG_ 670 FLR_FreespaceSectorDistance153  " ";
CM_ SG_ 670 FLR_FreespaceSectorKinestate152  " ";
CM_ SG_ 670 FLR_FreespaceSectorConfidence152  " ";
CM_ SG_ 670 FLR_FreespaceSectorDistance152  " ";
CM_ SG_ 670 FLR_FreespaceSectorKinestate151  " ";
CM_ SG_ 670 FLR_FreespaceSectorConfidence151  " ";
CM_ SG_ 670 FLR_FreespaceSectorDistance151  " ";
CM_ SG_ 670 FLR_FreespaceSectorKinestate150  " ";
CM_ SG_ 670 FLR_FreespaceSectorConfidence150  " ";
CM_ SG_ 670 FLR_FreespaceSectorDistance150  " ";
CM_ SG_ 670 FLR_FreespaceSectorKinestate149  " ";
CM_ SG_ 670 FLR_FreespaceSectorConfidence149  " ";
CM_ SG_ 670 FLR_FreespaceSectorDistance149  " ";
CM_ SG_ 670 FLR_FreespaceSectorKinestate148  " ";
CM_ SG_ 670 FLR_FreespaceSectorConfidence148  " ";
CM_ SG_ 670 FLR_FreespaceSectorDistance148  " ";
CM_ SG_ 670 FLR_FreespaceSectorKinestate147  " ";
CM_ SG_ 670 FLR_FreespaceSectorConfidence147  " ";
CM_ SG_ 670 FLR_FreespaceSectorDistance147  " ";
CM_ SG_ 670 FLR_FreespaceSectorKinestate146  " ";
CM_ SG_ 670 FLR_FreespaceSectorConfidence146  " ";
CM_ SG_ 670 FLR_FreespaceSectorDistance146  " ";
CM_ SG_ 670 FLR_FreespaceSectorKinestate145  " ";
CM_ SG_ 670 FLR_FreespaceSectorConfidence145  " ";
CM_ SG_ 670 FLR_FreespaceSectorDistance145  " ";
CM_ SG_ 670 FLR_FreespaceSectorKinestate144  " ";
CM_ SG_ 670 FLR_FreespaceSectorConfidence144  " ";
CM_ SG_ 670 FLR_FreespaceSectorDistance144  " ";
CM_ SG_ 670 FLR_FreespaceSectorKinestate143  " ";
CM_ SG_ 670 FLR_FreespaceSectorConfidence143  " ";
CM_ SG_ 670 FLR_FreespaceSectorDistance143  " ";
CM_ SG_ 670 FLR_FreespaceSectorKinestate142  " ";
CM_ SG_ 670 FLR_FreespaceSectorConfidence142  " ";
CM_ SG_ 670 FLR_FreespaceSectorDistance142  " ";
CM_ SG_ 670 FLR_FreespaceSectorKinestate141  " ";
CM_ SG_ 670 FLR_FreespaceSectorConfidence141  " ";
CM_ SG_ 670 FLR_FreespaceSectorDistance141  " ";
CM_ SG_ 670 FLR_FreespaceSectorKinestate140  " ";
CM_ SG_ 670 FLR_FreespaceSectorConfidence140  " ";
CM_ SG_ 670 FLR_FreespaceSectorDistance140  " ";
CM_ SG_ 670 FLR_FreespaceSectorKinestate139  " ";
CM_ SG_ 670 FLR_FreespaceSectorConfidence139  " ";
CM_ SG_ 670 FLR_FreespaceSectorDistance139  " ";
CM_ SG_ 670 FLR_FreespaceSectorKinestate138  " ";
CM_ SG_ 670 FLR_FreespaceSectorConfidence138  " ";
CM_ SG_ 670 FLR_FreespaceSectorDistance138  " ";
CM_ SG_ 670 FLR_FreespaceSectorKinestate137  " ";
CM_ SG_ 670 FLR_FreespaceSectorConfidence137  " ";
CM_ SG_ 670 FLR_FreespaceSectorDistance137  " ";

CM_ BO_ 671  " ";
CM_ SG_ 671 FLR_CRCCheck_29F  " ";
CM_ SG_ 671 FLR_RollingCounter_29F  " ";
CM_ SG_ 671 FLR_FreespaceSectorKinestate204  " ";
CM_ SG_ 671 FLR_FreespaceSectorConfidence204  " ";
CM_ SG_ 671 FLR_FreespaceSectorDistance204  " ";
CM_ SG_ 671 FLR_FreespaceSectorKinestate203  " ";
CM_ SG_ 671 FLR_FreespaceSectorConfidence203  " ";
CM_ SG_ 671 FLR_FreespaceSectorDistance203  " ";
CM_ SG_ 671 FLR_FreespaceSectorKinestate202  " ";
CM_ SG_ 671 FLR_FreespaceSectorConfidence202  " ";
CM_ SG_ 671 FLR_FreespaceSectorDistance202  " ";
CM_ SG_ 671 FLR_FreespaceSectorKinestate201  " ";
CM_ SG_ 671 FLR_FreespaceSectorConfidence201  " ";
CM_ SG_ 671 FLR_FreespaceSectorDistance201  " ";
CM_ SG_ 671 FLR_FreespaceSectorKinestate200  " ";
CM_ SG_ 671 FLR_FreespaceSectorConfidence200  " ";
CM_ SG_ 671 FLR_FreespaceSectorDistance200  " ";
CM_ SG_ 671 FLR_FreespaceSectorKinestate199  " ";
CM_ SG_ 671 FLR_FreespaceSectorConfidence199  " ";
CM_ SG_ 671 FLR_FreespaceSectorDistance199  " ";
CM_ SG_ 671 FLR_FreespaceSectorKinestate198  " ";
CM_ SG_ 671 FLR_FreespaceSectorConfidence198  " ";
CM_ SG_ 671 FLR_FreespaceSectorDistance198  " ";
CM_ SG_ 671 FLR_FreespaceSectorKinestate197  " ";
CM_ SG_ 671 FLR_FreespaceSectorConfidence197  " ";
CM_ SG_ 671 FLR_FreespaceSectorDistance197  " ";
CM_ SG_ 671 FLR_FreespaceSectorKinestate196  " ";
CM_ SG_ 671 FLR_FreespaceSectorConfidence196  " ";
CM_ SG_ 671 FLR_FreespaceSectorDistance196  " ";
CM_ SG_ 671 FLR_FreespaceSectorKinestate195  " ";
CM_ SG_ 671 FLR_FreespaceSectorConfidence195  " ";
CM_ SG_ 671 FLR_FreespaceSectorDistance195  " ";
CM_ SG_ 671 FLR_FreespaceSectorKinestate194  " ";
CM_ SG_ 671 FLR_FreespaceSectorConfidence194  " ";
CM_ SG_ 671 FLR_FreespaceSectorDistance194  " ";
CM_ SG_ 671 FLR_FreespaceSectorKinestate193  " ";
CM_ SG_ 671 FLR_FreespaceSectorConfidence193  " ";
CM_ SG_ 671 FLR_FreespaceSectorDistance193  " ";
CM_ SG_ 671 FLR_FreespaceSectorKinestate192  " ";
CM_ SG_ 671 FLR_FreespaceSectorConfidence192  " ";
CM_ SG_ 671 FLR_FreespaceSectorDistance192  " ";
CM_ SG_ 671 FLR_FreespaceSectorKinestate191  " ";
CM_ SG_ 671 FLR_FreespaceSectorConfidence191  " ";
CM_ SG_ 671 FLR_FreespaceSectorDistance191  " ";
CM_ SG_ 671 FLR_FreespaceSectorKinestate190  " ";
CM_ SG_ 671 FLR_FreespaceSectorConfidence190  " ";
CM_ SG_ 671 FLR_FreespaceSectorDistance190  " ";
CM_ SG_ 671 FLR_FreespaceSectorKinestate189  " ";
CM_ SG_ 671 FLR_FreespaceSectorConfidence189  " ";
CM_ SG_ 671 FLR_FreespaceSectorDistance189  " ";
CM_ SG_ 671 FLR_FreespaceSectorKinestate188  " ";
CM_ SG_ 671 FLR_FreespaceSectorConfidence188  " ";
CM_ SG_ 671 FLR_FreespaceSectorDistance188  " ";
CM_ SG_ 671 FLR_FreespaceSectorKinestate187  " ";
CM_ SG_ 671 FLR_FreespaceSectorConfidence187  " ";
CM_ SG_ 671 FLR_FreespaceSectorDistance187  " ";
CM_ SG_ 671 FLR_FreespaceSectorKinestate186  " ";
CM_ SG_ 671 FLR_FreespaceSectorConfidence186  " ";
CM_ SG_ 671 FLR_FreespaceSectorDistance186  " ";
CM_ SG_ 671 FLR_FreespaceSectorKinestate185  " ";
CM_ SG_ 671 FLR_FreespaceSectorConfidence185  " ";
CM_ SG_ 671 FLR_FreespaceSectorDistance185  " ";
CM_ SG_ 671 FLR_FreespaceSectorKinestate184  " ";
CM_ SG_ 671 FLR_FreespaceSectorConfidence184  " ";
CM_ SG_ 671 FLR_FreespaceSectorDistance184  " ";
CM_ SG_ 671 FLR_FreespaceSectorKinestate183  " ";
CM_ SG_ 671 FLR_FreespaceSectorConfidence183  " ";
CM_ SG_ 671 FLR_FreespaceSectorDistance183  " ";
CM_ SG_ 671 FLR_FreespaceSectorKinestate182  " ";
CM_ SG_ 671 FLR_FreespaceSectorConfidence182  " ";
CM_ SG_ 671 FLR_FreespaceSectorDistance182  " ";
CM_ SG_ 671 FLR_FreespaceSectorKinestate181  " ";
CM_ SG_ 671 FLR_FreespaceSectorConfidence181  " ";
CM_ SG_ 671 FLR_FreespaceSectorDistance181  " ";
CM_ SG_ 671 FLR_FreespaceSectorKinestate180  " ";
CM_ SG_ 671 FLR_FreespaceSectorConfidence180  " ";
CM_ SG_ 671 FLR_FreespaceSectorDistance180  " ";
CM_ SG_ 671 FLR_FreespaceSectorKinestate179  " ";
CM_ SG_ 671 FLR_FreespaceSectorConfidence179  " ";
CM_ SG_ 671 FLR_FreespaceSectorDistance179  " ";
CM_ SG_ 671 FLR_FreespaceSectorKinestate178  " ";
CM_ SG_ 671 FLR_FreespaceSectorConfidence178  " ";
CM_ SG_ 671 FLR_FreespaceSectorDistance178  " ";
CM_ SG_ 671 FLR_FreespaceSectorKinestate177  " ";
CM_ SG_ 671 FLR_FreespaceSectorConfidence177  " ";
CM_ SG_ 671 FLR_FreespaceSectorDistance177  " ";
CM_ SG_ 671 FLR_FreespaceSectorKinestate176  " ";
CM_ SG_ 671 FLR_FreespaceSectorConfidence176  " ";
CM_ SG_ 671 FLR_FreespaceSectorDistance176  " ";
CM_ SG_ 671 FLR_FreespaceSectorKinestate175  " ";
CM_ SG_ 671 FLR_FreespaceSectorConfidence175  " ";
CM_ SG_ 671 FLR_FreespaceSectorDistance175  " ";
CM_ SG_ 671 FLR_FreespaceSectorKinestate174  " ";
CM_ SG_ 671 FLR_FreespaceSectorConfidence174  " ";
CM_ SG_ 671 FLR_FreespaceSectorDistance174  " ";
CM_ SG_ 671 FLR_FreespaceSectorKinestate173  " ";
CM_ SG_ 671 FLR_FreespaceSectorConfidence173  " ";
CM_ SG_ 671 FLR_FreespaceSectorDistance173  " ";
CM_ SG_ 671 FLR_FreespaceSectorKinestate172  " ";
CM_ SG_ 671 FLR_FreespaceSectorConfidence172  " ";
CM_ SG_ 671 FLR_FreespaceSectorDistance172  " ";
CM_ SG_ 671 FLR_FreespaceSectorKinestate171  " ";
CM_ SG_ 671 FLR_FreespaceSectorConfidence171  " ";
CM_ SG_ 671 FLR_FreespaceSectorDistance171  " ";

CM_ BO_ 768  " ";
CM_ SG_ 768 FLR_CRCCheck_300  " ";
CM_ SG_ 768 FLR_RollingCounter_300  " ";
CM_ SG_ 768 FLR_FreespaceSectorKinestate238  " ";
CM_ SG_ 768 FLR_FreespaceSectorConfidence238  " ";
CM_ SG_ 768 FLR_FreespaceSectorDistance238  " ";
CM_ SG_ 768 FLR_FreespaceSectorKinestate237  " ";
CM_ SG_ 768 FLR_FreespaceSectorConfidence237  " ";
CM_ SG_ 768 FLR_FreespaceSectorDistance237  " ";
CM_ SG_ 768 FLR_FreespaceSectorKinestate236  " ";
CM_ SG_ 768 FLR_FreespaceSectorConfidence236  " ";
CM_ SG_ 768 FLR_FreespaceSectorDistance236  " ";
CM_ SG_ 768 FLR_FreespaceSectorKinestate235  " ";
CM_ SG_ 768 FLR_FreespaceSectorConfidence235  " ";
CM_ SG_ 768 FLR_FreespaceSectorDistance235  " ";
CM_ SG_ 768 FLR_FreespaceSectorKinestate234  " ";
CM_ SG_ 768 FLR_FreespaceSectorConfidence234  " ";
CM_ SG_ 768 FLR_FreespaceSectorDistance234  " ";
CM_ SG_ 768 FLR_FreespaceSectorKinestate233  " ";
CM_ SG_ 768 FLR_FreespaceSectorConfidence233  " ";
CM_ SG_ 768 FLR_FreespaceSectorDistance233  " ";
CM_ SG_ 768 FLR_FreespaceSectorKinestate232  " ";
CM_ SG_ 768 FLR_FreespaceSectorConfidence232  " ";
CM_ SG_ 768 FLR_FreespaceSectorDistance232  " ";
CM_ SG_ 768 FLR_FreespaceSectorKinestate231  " ";
CM_ SG_ 768 FLR_FreespaceSectorConfidence231  " ";
CM_ SG_ 768 FLR_FreespaceSectorDistance231  " ";
CM_ SG_ 768 FLR_FreespaceSectorKinestate230  " ";
CM_ SG_ 768 FLR_FreespaceSectorConfidence230  " ";
CM_ SG_ 768 FLR_FreespaceSectorDistance230  " ";
CM_ SG_ 768 FLR_FreespaceSectorKinestate229  " ";
CM_ SG_ 768 FLR_FreespaceSectorConfidence229  " ";
CM_ SG_ 768 FLR_FreespaceSectorDistance229  " ";
CM_ SG_ 768 FLR_FreespaceSectorKinestate228  " ";
CM_ SG_ 768 FLR_FreespaceSectorConfidence228  " ";
CM_ SG_ 768 FLR_FreespaceSectorDistance228  " ";
CM_ SG_ 768 FLR_FreespaceSectorKinestate227  " ";
CM_ SG_ 768 FLR_FreespaceSectorConfidence227  " ";
CM_ SG_ 768 FLR_FreespaceSectorDistance227  " ";
CM_ SG_ 768 FLR_FreespaceSectorKinestate226  " ";
CM_ SG_ 768 FLR_FreespaceSectorConfidence226  " ";
CM_ SG_ 768 FLR_FreespaceSectorDistance226  " ";
CM_ SG_ 768 FLR_FreespaceSectorKinestate225  " ";
CM_ SG_ 768 FLR_FreespaceSectorConfidence225  " ";
CM_ SG_ 768 FLR_FreespaceSectorDistance225  " ";
CM_ SG_ 768 FLR_FreespaceSectorKinestate224  " ";
CM_ SG_ 768 FLR_FreespaceSectorConfidence224  " ";
CM_ SG_ 768 FLR_FreespaceSectorDistance224  " ";
CM_ SG_ 768 FLR_FreespaceSectorKinestate223  " ";
CM_ SG_ 768 FLR_FreespaceSectorConfidence223  " ";
CM_ SG_ 768 FLR_FreespaceSectorDistance223  " ";
CM_ SG_ 768 FLR_FreespaceSectorKinestate222  " ";
CM_ SG_ 768 FLR_FreespaceSectorConfidence222  " ";
CM_ SG_ 768 FLR_FreespaceSectorDistance222  " ";
CM_ SG_ 768 FLR_FreespaceSectorKinestate221  " ";
CM_ SG_ 768 FLR_FreespaceSectorConfidence221  " ";
CM_ SG_ 768 FLR_FreespaceSectorDistance221  " ";
CM_ SG_ 768 FLR_FreespaceSectorKinestate220  " ";
CM_ SG_ 768 FLR_FreespaceSectorConfidence220  " ";
CM_ SG_ 768 FLR_FreespaceSectorDistance220  " ";
CM_ SG_ 768 FLR_FreespaceSectorKinestate219  " ";
CM_ SG_ 768 FLR_FreespaceSectorConfidence219  " ";
CM_ SG_ 768 FLR_FreespaceSectorDistance219  " ";
CM_ SG_ 768 FLR_FreespaceSectorKinestate218  " ";
CM_ SG_ 768 FLR_FreespaceSectorConfidence218  " ";
CM_ SG_ 768 FLR_FreespaceSectorDistance218  " ";
CM_ SG_ 768 FLR_FreespaceSectorKinestate217  " ";
CM_ SG_ 768 FLR_FreespaceSectorConfidence217  " ";
CM_ SG_ 768 FLR_FreespaceSectorDistance217  " ";
CM_ SG_ 768 FLR_FreespaceSectorKinestate216  " ";
CM_ SG_ 768 FLR_FreespaceSectorConfidence216  " ";
CM_ SG_ 768 FLR_FreespaceSectorDistance216  " ";
CM_ SG_ 768 FLR_FreespaceSectorKinestate215  " ";
CM_ SG_ 768 FLR_FreespaceSectorConfidence215  " ";
CM_ SG_ 768 FLR_FreespaceSectorDistance215  " ";
CM_ SG_ 768 FLR_FreespaceSectorKinestate214  " ";
CM_ SG_ 768 FLR_FreespaceSectorConfidence214  " ";
CM_ SG_ 768 FLR_FreespaceSectorDistance214  " ";
CM_ SG_ 768 FLR_FreespaceSectorKinestate213  " ";
CM_ SG_ 768 FLR_FreespaceSectorConfidence213  " ";
CM_ SG_ 768 FLR_FreespaceSectorDistance213  " ";
CM_ SG_ 768 FLR_FreespaceSectorKinestate212  " ";
CM_ SG_ 768 FLR_FreespaceSectorConfidence212  " ";
CM_ SG_ 768 FLR_FreespaceSectorDistance212  " ";
CM_ SG_ 768 FLR_FreespaceSectorKinestate211  " ";
CM_ SG_ 768 FLR_FreespaceSectorConfidence211  " ";
CM_ SG_ 768 FLR_FreespaceSectorDistance211  " ";
CM_ SG_ 768 FLR_FreespaceSectorKinestate210  " ";
CM_ SG_ 768 FLR_FreespaceSectorConfidence210  " ";
CM_ SG_ 768 FLR_FreespaceSectorDistance210  " ";
CM_ SG_ 768 FLR_FreespaceSectorKinestate209  " ";
CM_ SG_ 768 FLR_FreespaceSectorConfidence209  " ";
CM_ SG_ 768 FLR_FreespaceSectorDistance209  " ";
CM_ SG_ 768 FLR_FreespaceSectorKinestate208  " ";
CM_ SG_ 768 FLR_FreespaceSectorConfidence208  " ";
CM_ SG_ 768 FLR_FreespaceSectorDistance208  " ";
CM_ SG_ 768 FLR_FreespaceSectorKinestate207  " ";
CM_ SG_ 768 FLR_FreespaceSectorConfidence207  " ";
CM_ SG_ 768 FLR_FreespaceSectorDistance207  " ";
CM_ SG_ 768 FLR_FreespaceSectorKinestate206  " ";
CM_ SG_ 768 FLR_FreespaceSectorConfidence206  " ";
CM_ SG_ 768 FLR_FreespaceSectorDistance206  " ";
CM_ SG_ 768 FLR_FreespaceSectorKinestate205  " ";
CM_ SG_ 768 FLR_FreespaceSectorConfidence205  " ";
CM_ SG_ 768 FLR_FreespaceSectorDistance205  " ";

CM_ BO_ 771  " ";
CM_ SG_ 771 FLR_CRCCheck_303  " ";
CM_ SG_ 771 FLR_RollingCounter_301  " ";
CM_ SG_ 771 FLR_FreespaceSectorKinestate240  " ";
CM_ SG_ 771 FLR_FreespaceSectorConfidence240  " ";
CM_ SG_ 771 FLR_FreespaceSectorDistance240  " ";
CM_ SG_ 771 FLR_FreespaceSectorKinestate239  " ";
CM_ SG_ 771 FLR_FreespaceSectorConfidence239  " ";
CM_ SG_ 771 FLR_FreespaceSectorDistance239  " ";

CM_ BO_ 691  " ";
CM_ SG_ 691 RLR_CRCCheck_2B3  " ";
CM_ SG_ 691 RLR_RollingCounter_2B3  " ";
CM_ SG_ 691 FuncDegradeType_FR  " ";
CM_ SG_ 691 FUSION_TimeoutCnt_FR  " ";
CM_ SG_ 691 VALIDATION_TimeoutCnt_FR  " ";
CM_ SG_ 691 CurFrameCycle_FR  " ";
CM_ SG_ 691 ProcessTimeoutCnt_FR  " ";
CM_ SG_ 691 RevFrameCnt_FR  " ";
CM_ SG_ 691 Local_Pointcloud_Number_FR  " ";
CM_ SG_ 691 RealTimeCal_PrcssBar_FR  " ";
CM_ SG_ 691 RealTimeCal_VelErrOutput_FR  " ";
CM_ SG_ 691 RealTimeCal_HoriMntErrOutput_FR  " ";
CM_ SG_ 691 RealTimeCal_FailReasonCode_FR  " ";
CM_ SG_ 691 RealTimeCal_Status_FR  " ";
CM_ SG_ 691 DiagCal_PrcssBar_FR  " ";
CM_ SG_ 691 DiagCal_VelErrOutput_FR  " ";
CM_ SG_ 691 DiagCal_HoriMntErrOutput_FR  " ";
CM_ SG_ 691 DiagCal_FailReasonCode_FR  " ";
CM_ SG_ 691 DiagCal_Status_FR  " ";
CM_ SG_ 691 EolCal_PrcssBar_FR  " ";
CM_ SG_ 691 EolCal_VelErrOutput_FR  " ";
CM_ SG_ 691 EolCal_HoriMntErrOutput_FR  " ";
CM_ SG_ 691 EolCal_FailReasonCode_FR  " ";
CM_ SG_ 691 EolCal_Status_FR  " ";
CM_ SG_ 691 PriCounter  " ";
CM_ SG_ 691 MsgCounter_FR  " ";

CM_ BO_ 338  " ";
CM_ SG_ 338 ADR_TriggerEventReq  " ";
CM_ SG_ 338 ACC_AEBEnable  "ACC ╓ў┐╪╘ЄACC╖в╦═гмLAS ╓ў┐╪╘ЄLAS╖в╦═ ";
CM_ SG_ 338 ACC_FCWSettingStatus  "ACC ╓ў┐╪╘ЄACC╖в╦═гмLAS ╓ў┐╪╘ЄLAS╖в╦═ ";
CM_ SG_ 338 ADC_SenceMode  " ";

CM_ BO_ 1308  " ";
CM_ SG_ 1308 AD_SYNC_Sync_Time  " ";
CM_ SG_ 1308 AD_SYNC_UserByte_OVS_SGW  " ";
CM_ SG_ 1308 AD_SYNC_TimeDomain  " ";
CM_ SG_ 1308 AD_SYNC_Sequence  " ";
CM_ SG_ 1308 AD_SYNC_CRC  " ";
CM_ SG_ 1308 AD_SYNC_Type  " ";

CM_ BO_ 384  " ";
CM_ SG_ 384 SAS_SteeringAngle  "APA┼ф╓├╜╙╩╒╖╜╬▐BDC ";

CM_ BO_ 800  " ";
CM_ SG_ 800 GW_ResetReq  " ";
CM_ SG_ 800 GW_OTAmode_Chks  "╙ыGW_OTAmode╖╓┼ф╡╜╥╗╕ЎID╡─╧р┴┌╫╓╜┌ ";
CM_ SG_ 800 GW_OTAmode_Cntr  "╙ыGW_OTAmode╖╓┼ф╡╜1╕Ў╫╓╜┌ ";
CM_ SG_ 800 GW_OTAmode  "╙ыGW_OTAmode_Cntr╖╓┼ф╡╜1╕Ў╫╓╜┌ ";

CM_ BO_ 1302  " ";

CM_ BO_ 1328  " ";
CM_ SG_ 1328 IP_TotalOdometer  "GW▒и╬─╫к╖в ";

CM_ BO_ 349  " ";

CM_ BO_ 632  " ";
CM_ SG_ 632 ESP_YawRate  "╙╥╒¤╫є╕║ги╛┘└¤└э╜т=╦о╞╜┬╖├ц╧Є
╙╥╫к═ф╩▒гм╖в╒¤╓╡бг╖┤╓о╖в╕║╓╡гй ";
CM_ SG_ 632 ESP_LongAccel  "╛┘└¤└э╜т=╦о╞╜┬╖├ц╓▒╧▀╝╙╦┘
╩▒гм╖в╒¤╓╡бг╖┤╓о╖в╕║╓╡бг ";
CM_ SG_ 632 ESP_LatAccel  "╙╥╒¤╫є╕║ги╛┘└¤└э╜т=╦о╞╜┬╖├ц╧Є
╙╥╫к═ф╩▒гм╖в╒¤╓╡бг╖┤╓о╖в╕║╓╡гй ";

CM_ BO_ 378  " ";
CM_ SG_ 378 ESP_ESPActiveStatus  "TCU╜╙╩╒╬кDCT╫и╙├ ";
CM_ SG_ 378 ESP_VehicleSpeedValid  "TCU╜╙╩╒╬кDCT╫и╙├ ";
CM_ SG_ 378 ESP_VehicleSpeed  "TCU╜╙╩╒╬кDCT╫и╙├ ";

CM_ BO_ 523  " ";
CM_ SG_ 523 ESP_BrakeForce  "APA┼ф╓├╜╙╩╒╖╜╬▐BDC ";
CM_ SG_ 523 ESP_AEBdecActive  "ACC ╓ў┐╪╘ЄACC╜╙╩╒гмLAS ╓ў┐╪╘ЄLAS╜╙╩╒ ";
CM_ SG_ 523 ESP_AEBAvailable  "ACC ╓ў┐╪╘ЄACC╜╙╩╒гмLAS ╓ў┐╪╘ЄLAS╜╙╩╒ ";
CM_ SG_ 523 Wheel_Speed_RR_Pulse  "All4wheelpulsesignalsaresentbyABSwithoutfiltering.Theriseedgeandfalledgearebothcountedinit,thewheelpulsemustbesequentialintheway0,1,2бн254,0,1бн ";
CM_ SG_ 523 Wheel_Speed_RR_Direction  "APA┼ф╓├╜╙╩╒╖╜╬▐BDC ";
CM_ SG_ 523 Wheel_Speed_RR_Data  "APA┼ф╓├╜╙╩╒╖╜╬▐BDC ";
CM_ SG_ 523 Wheel_Speed_RL_Pulse  "All4wheelpulsesignalsaresentbyABSwithoutfiltering.Theriseedgeandfalledgearebothcountedinit,thewheelpulsemustbesequentialintheway0,1,2бн254,0,2бн ";
CM_ SG_ 523 Wheel_Speed_RL_Direction  "APA┼ф╓├╜╙╩╒╖╜╬▐BDC ";
CM_ SG_ 523 Wheel_Speed_RL_Data  "APA┼ф╓├╜╙╩╒╖╜╬▐BDC ";
CM_ SG_ 523 Wheel_Speed_FR_Pulse  "All4wheelpulsesignalsaresentbyABSwithoutfiltering.Theriseedgeandfalledgearebothcountedinit,thewheelpulsemustbesequentialintheway0,1,2бн254,0,3бн ";
CM_ SG_ 523 Wheel_Speed_FR_Direction  "APA┼ф╓├╜╙╩╒╖╜╬▐BDC ";
CM_ SG_ 523 Wheel_Speed_FR_Data  "APA┼ф╓├╜╙╩╒╖╜╬▐BDC ";
CM_ SG_ 523 Wheel_Speed_FL_Pulse  "All4wheelpulsesignalsaresentbyABSwithoutfiltering.Theriseedgeandfalledgearebothcountedinit,thewheelpulsemustbesequentialintheway0,1,2бн254,0,4бн ";
CM_ SG_ 523 Wheel_Speed_FL_Direction  "APA┼ф╓├╜╙╩╒╖╜╬▐BDC ";
CM_ SG_ 523 Wheel_Speed_FL_Data  "APA┼ф╓├╜╙╩╒╖╜╬▐BDC ";
CM_ SG_ 523 ESP_VehicleStandstillVld  " ";
CM_ SG_ 523 ESP_VehicleStandstill  "APA┼ф╓├╜╙╩╒╖╜╬▐BDC ";

CM_ BO_ 381  " ";
CM_ SG_ 381 PCU_RealAccPedlVld  "ACC ╓ў┐╪╘ЄACC╜╙╩╒гмLAS ╓ў┐╪╘ЄLAS╜╙╩╒ ";
CM_ SG_ 381 PCU_RealAccPedl  "APA┼ф╓├╜╙╩╒╖╜╬▐BDC ";

CM_ BO_ 398  " ";
CM_ SG_ 398 EMS_BrakePedalStatus  "▒э╩╛╝▌╩╗╘▒▓╚╧┬╓╞╢п╠д░х╡─╒ц╩╡╫┤╠м
ACM╜╙╩╒╬кAT╫и╙├ ";

CM_ BO_ 431  " ";
CM_ SG_ 431 TCU_CRCCheck_1A8  "CRCCheck_SAE_J1850_2001,multinomial is X8+X4+X3+X2+1 ";
CM_ SG_ 431 TCU_GearShiftPosition  "TCU receives driver demands gear from ESL and make decisition of actual drive mode based on current vehicle/transmission status.
PCU receives this signals to understand actual drive mode and estimate target gear ";
CM_ SG_ 431 TCU_ShiftPostionValid  "APA┼ф╓├╜╙╩╒╖╜╬▐BDC ";

CM_ BO_ 424  " ";
CM_ SG_ 424 TCU_CRCCheck_1A8  "ACM╜╙╩╒╬кAT╫и╙├ ";
CM_ SG_ 424 TCU_RollingCounter_1A8  "AT/DCT
ACM╜╙╩╒╬кAT╫и╙├
rollingcounter ";
CM_ SG_ 424 TCU_ActualGear  "AT/DCT ";
CM_ SG_ 424 TCU_ActualGearValid  "AT/DCT ";
CM_ SG_ 424 TCU_GearShiftPosition  "AT/DCT
ACM╜╙╩╒╬кAT╫и╙├ ";
CM_ SG_ 424 TCU_ShiftPostionValid  "AT/DCT
ACM╜╙╩╒╬кAT╫и╙├ ";

CM_ BO_ 796  " ";
CM_ SG_ 796 PCU_VcuRdySts  "APA┼ф╓├╜╙╩╒╖╜╬▐BDC ";

CM_ BO_ 651  " ";

CM_ BO_ 271  " ";

CM_ BO_ 80  " ";
CM_ SG_ 80 SRS_RollingCounter_id050  "ACM╜╙╩╒╬кAT╫и╙├ ";
CM_ SG_ 80 SRS_PassengerBuckleSwitchStatus  "For PDM is configured projects=
(if PDM is configured, logical detection with PDM is required)
0x0= [Buckled] or [Unbuckled and passenger not occupied]
0x1= [Unbuckle and passenger occupied]
0x2= Not Used
0x3= Not Used
 ";
CM_ SG_ 80 SRS_DriverBuckleSwitchStatus  " ";

CM_ BO_ 664  " ";

CM_ BO_ 721  " ";

CM_ BO_ 587  " ";
CM_ SG_ 587 Transmitcnt6_R  " ";
CM_ SG_ 587 Transmitcnt5_R  " ";
CM_ SG_ 587 Transmitcnt4_R  " ";
CM_ SG_ 587 Transmitcnt3_R  " ";
CM_ SG_ 587 Transmitcnt2_R  " ";
CM_ SG_ 587 Transmitcnt1_R  " ";
CM_ SG_ 587 RLR_Track_ID_R  " ";
CM_ SG_ 587 RLR_Measured_R  " ";
CM_ SG_ 587 RLR_Location_R  " ";
CM_ SG_ 587 RLR_ClassComfrmFlg_R  " ";
CM_ SG_ 587 RLR_TrckrType_R  " ";
CM_ SG_ 587 RLR_TrckrAge_R  " ";
CM_ SG_ 587 RLR_MotionStatus_R  " ";
CM_ SG_ 587 RLR_AbsVy_R  " ";
CM_ SG_ 587 RLR_AbsoVx_R  " ";
CM_ SG_ 587 RLR_LocDx_R  " ";
CM_ SG_ 587 RLR_LocDy_R  " ";
CM_ SG_ 587 RLR_HeadingAngle_R  " ";
CM_ SG_ 587 RLR_Length_R  " ";
CM_ SG_ 587 RLR_Width_R  " ";
CM_ SG_ 587 RLR_Track_ID_L  " ";
CM_ SG_ 587 RLR_Measured_L  " ";
CM_ SG_ 587 RLR_Location_L  " ";
CM_ SG_ 587 RLR_ClassComfrmFlg_L  " ";
CM_ SG_ 587 RLR_TrckrType_L  " ";
CM_ SG_ 587 RLR_TrckrAge_L  " ";
CM_ SG_ 587 RLR_MotionStatus_L  " ";
CM_ SG_ 587 RLR_AbsVy_L  " ";
CM_ SG_ 587 RLR_AbsoVx_L  " ";
CM_ SG_ 587 RLR_LocDx_L  " ";
CM_ SG_ 587 RLR_LocDy_L  " ";
CM_ SG_ 587 RLR_HeadingAngle_L  " ";
CM_ SG_ 587 RLR_Length_L  " ";
CM_ SG_ 587 RLR_Width_L  " ";
CM_ SG_ 587 RLR_TrckrNum  " ";
CM_ SG_ 587 RLR_TrackerTimeStamp  " ";

CM_ BO_ 1894  "CANFD╒я╢╧╥╟╩╣╙├ ";

CM_ BO_ 1902  "CANFD╒я╢╧╥╟╩╣╙├ ";

CM_ BO_ 1895  "CANFD╒я╢╧╥╟╩╣╙├ ";

CM_ BO_ 1903  "CANFD╒я╢╧╥╟╩╣╙├ ";

CM_ BO_ 1104  " ";

CM_ BO_ 1110  " ";

CM_ BO_ 1111  " ";

CM_ BO_ 1442  " ";
CM_ SG_ 1442 FLR_WakeUp_BYTE4BIT1  " ";
CM_ SG_ 1442 FLR_WakeUp_BYTE4BIT0  " ";
CM_ SG_ 1442 FLR_NotSleep_BYTE7BIT1  " ";
CM_ SG_ 1442 FLR_NotSleep_BYTE7BIT0  " ";

CM_ BO_ 1432  " ";
CM_ SG_ 1432 FRR_WakeUp_BYTE4BIT1  " ";
CM_ SG_ 1432 FRR_WakeUp_BYTE4BIT0  " ";
CM_ SG_ 1432 FRR_NotSleep_BYTE7BIT1  " ";
CM_ SG_ 1432 FRR_NotSleep_BYTE7BIT0  " ";

CM_ BO_ 1763  " ";
CM_ SG_ 1763 FLR_DTC2_Status  "DTC╔╧┤л ";
CM_ SG_ 1763 FLR_DTC2_LowByte  "DTC╔╧┤л ";
CM_ SG_ 1763 FLR_DTC2_MiddByte  "DTC╔╧┤л ";
CM_ SG_ 1763 FLR_DTC2_HighByte  "DTC╔╧┤л ";
CM_ SG_ 1763 FLR_DTC1_Status  "DTC╔╧┤л ";
CM_ SG_ 1763 FLR_DTC1_LowByte  "DTC╔╧┤л ";
CM_ SG_ 1763 FLR_DTC1_MiddByte  "DTC╔╧┤л ";
CM_ SG_ 1763 FLR_DTC1_HighByte  "DTC╔╧┤л ";

CM_ BO_ 1776  " ";
CM_ SG_ 1776 FRR_DTC2_Status  "DTC╔╧┤л ";
CM_ SG_ 1776 FRR_DTC2_LowByte  "DTC╔╧┤л ";
CM_ SG_ 1776 FRR_DTC2_MiddByte  "DTC╔╧┤л ";
CM_ SG_ 1776 FRR_DTC2_HighByte  "DTC╔╧┤л ";
CM_ SG_ 1776 FRR_DTC1_Status  "DTC╔╧┤л ";
CM_ SG_ 1776 FRR_DTC1_LowByte  "DTC╔╧┤л ";
CM_ SG_ 1776 FRR_DTC1_MiddByte  "DTC╔╧┤л ";
CM_ SG_ 1776 FRR_DTC1_HighByte  "DTC╔╧┤л ";

CM_ BO_ 623  " ";
CM_ SG_ 623 FC_Line_4_exist_prob  " ";
CM_ SG_ 623 FC_Line_4_MeasureType  " ";
CM_ SG_ 623 FC_Line_4_ModelC3  " ";
CM_ SG_ 623 FC_Line_4_ModelC2  " ";
CM_ SG_ 623 FC_Line_4_ModelC1  " ";
CM_ SG_ 623 FC_Line_4_ModelC0  " ";
CM_ SG_ 623 FC_Line_4_dx_End  " ";
CM_ SG_ 623 FC_Line_4_dx_Start  " ";
CM_ SG_ 623 FC_Line_4_Id  " ";
CM_ SG_ 623 FC_Line_4_Type  " ";
CM_ SG_ 623 FC_Line_3_exist_prob  " ";
CM_ SG_ 623 FC_Line_3_MeasureType  " ";
CM_ SG_ 623 FC_Line_3_ModelC3  " ";
CM_ SG_ 623 FC_Line_3_ModelC2  " ";
CM_ SG_ 623 FC_Line_3_ModelC1  " ";
CM_ SG_ 623 FC_Line_3_ModelC0  " ";
CM_ SG_ 623 FC_Line_3_dx_End  " ";
CM_ SG_ 623 FC_Line_3_dx_Start  " ";
CM_ SG_ 623 FC_Line_3_Id  " ";
CM_ SG_ 623 FC_Line_3_Type  " ";
CM_ SG_ 623 FC_Line_2_exist_prob  " ";
CM_ SG_ 623 FC_Line_2_MeasureType  " ";
CM_ SG_ 623 FC_Line_2_ModelC3  " ";
CM_ SG_ 623 FC_Line_2_ModelC2  " ";
CM_ SG_ 623 FC_Line_2_ModelC1  " ";
CM_ SG_ 623 FC_Line_2_ModelC0  " ";
CM_ SG_ 623 FC_Line_2_dx_End  " ";
CM_ SG_ 623 FC_Line_2_dx_Start  " ";
CM_ SG_ 623 FC_Line_2_Id  " ";
CM_ SG_ 623 FC_Line_2_Type  " ";
CM_ SG_ 623 FC_Line_1_exist_prob  " ";
CM_ SG_ 623 FC_Line_1_MeasureType  " ";
CM_ SG_ 623 FC_Line_1_ModelC3  " ";
CM_ SG_ 623 FC_Line_1_ModelC2  " ";
CM_ SG_ 623 FC_Line_1_ModelC1  " ";
CM_ SG_ 623 FC_Line_1_ModelC0  " ";
CM_ SG_ 623 FC_Line_1_dx_End  " ";
CM_ SG_ 623 FC_Line_1_dx_Start  " ";
CM_ SG_ 623 FC_Line_1_Id  " ";
CM_ SG_ 623 FC_Line_1_Type  " ";

CM_ BO_ 697  " ";
CM_ SG_ 697 RLR_CRCCheck_2B9  " ";
CM_ SG_ 697 RLR_RollingCounter_2B9  " ";
CM_ SG_ 697 FLR_OBJ32_Ax  " ";
CM_ SG_ 697 FLR_OBJ31_Ax  " ";
CM_ SG_ 697 FLR_OBJ30_Ax  " ";
CM_ SG_ 697 FLR_OBJ29_Ax  " ";
CM_ SG_ 697 FLR_OBJ28_Ax  " ";
CM_ SG_ 697 FLR_OBJ27_Ax  " ";
CM_ SG_ 697 FLR_OBJ26_Ax  " ";
CM_ SG_ 697 FLR_OBJ25_Ax  " ";
CM_ SG_ 697 FLR_OBJ24_Ax  " ";
CM_ SG_ 697 FLR_OBJ23_Ax  " ";
CM_ SG_ 697 FLR_OBJ22_Ax  " ";
CM_ SG_ 697 FLR_OBJ21_Ax  " ";
CM_ SG_ 697 FLR_OBJ20_Ax  " ";
CM_ SG_ 697 FLR_OBJ19_Ax  " ";
CM_ SG_ 697 FLR_OBJ18_Ax  " ";
CM_ SG_ 697 FLR_OBJ17_Ax  " ";
CM_ SG_ 697 FLR_OBJ16_Ax  " ";
CM_ SG_ 697 FLR_OBJ15_Ax  " ";
CM_ SG_ 697 FLR_OBJ14_Ax  " ";
CM_ SG_ 697 FLR_OBJ13_Ax  " ";
CM_ SG_ 697 FLR_OBJ12_Ax  " ";
CM_ SG_ 697 FLR_OBJ11_Ax  " ";
CM_ SG_ 697 FLR_OBJ10_Ax  " ";
CM_ SG_ 697 FLR_OBJ9_Ax  " ";
CM_ SG_ 697 FLR_OBJ8_Ax  " ";
CM_ SG_ 697 FLR_OBJ7_Ax  " ";
CM_ SG_ 697 FLR_OBJ6_Ax  " ";
CM_ SG_ 697 FLR_OBJ5_Ax  " ";
CM_ SG_ 697 FLR_OBJ4_Ax  " ";
CM_ SG_ 697 FLR_OBJ3_Ax  " ";
CM_ SG_ 697 FLR_OBJ2_Ax  " ";
CM_ SG_ 697 FLR_OBJ1_Ax  " ";

CM_ BO_ 957  " ";

BA_DEF_ SG_  "GenSigStartValue" INT 0 0;
BA_DEF_ SG_  "GenSigInvalidValue" STRING  ;
BA_DEF_ SG_  "GenSigCycleTime" INT 0 0;
BA_DEF_ SG_  "GenSigSendType" ENUM  "Cyclic","OnWrite","OnWriteWithRepetition","OnChange","OnChangeWithRepetition","IfActive","IfActiveWithRepetition","NoSigSendType","NotUsed","NotUsed","NotUsed","NotUsed","NotUsed";
BA_DEF_ BO_  "GenMsgSendType" ENUM  "Cyclic","Event","Direct","NotUsed","NotUsed","Cyclic","NotUsed","IfActive","NoMsgSendType","NotUsed";
BA_DEF_ BO_  "GenMsgILSupport" ENUM  "No","Yes";
BA_DEF_ BO_  "GenMsgCycleTime" INT 0 65535;
BA_DEF_ BO_  "CANFD_BRS" ENUM  "0","1";
BA_DEF_ BO_  "VFrameFormat" ENUM  "StandardCAN","ExtendedCAN","reserved","reserved","reserved","reserved","reserved","reserved","reserved","reserved","reserved","reserved","reserved","reserved","StandardCAN_FD","ExtendedCAN_FD";
BA_DEF_DEF_  "GenSigStartValue" 0;
BA_DEF_DEF_  "GenSigInvalidValue" "/";
BA_DEF_DEF_  "GenSigCycleTime" 0;
BA_DEF_DEF_  "GenSigSendType" "Cyclic";
BA_DEF_DEF_  "GenMsgSendType" "NoMsgSendType";
BA_DEF_DEF_  "GenMsgILSupport" "Yes";
BA_DEF_DEF_  "GenMsgCycleTime" 0;
BA_DEF_DEF_  "CANFD_BRS" "1";
BA_DEF_DEF_  "VFrameFormat" "StandardCAN";
BA_ "GenMsgCycleTime" BO_ 669 50;
BA_ "GenMsgSendType" BO_ 669 0;
BA_ "VFrameFormat" BO_ 669 14;
BA_ "GenMsgCycleTime" BO_ 670 50;
BA_ "GenMsgSendType" BO_ 670 0;
BA_ "VFrameFormat" BO_ 670 14;
BA_ "GenMsgCycleTime" BO_ 671 50;
BA_ "GenMsgSendType" BO_ 671 0;
BA_ "VFrameFormat" BO_ 671 14;
BA_ "GenMsgCycleTime" BO_ 768 50;
BA_ "GenMsgSendType" BO_ 768 0;
BA_ "VFrameFormat" BO_ 768 14;
BA_ "GenMsgCycleTime" BO_ 771 50;
BA_ "GenMsgSendType" BO_ 771 0;
BA_ "VFrameFormat" BO_ 771 14;
BA_ "GenMsgCycleTime" BO_ 691 50;
BA_ "GenMsgSendType" BO_ 691 0;
BA_ "VFrameFormat" BO_ 691 14;
BA_ "GenMsgCycleTime" BO_ 338 10;
BA_ "GenMsgSendType" BO_ 338 0;
BA_ "VFrameFormat" BO_ 338 14;
BA_ "GenMsgSendType" BO_ 1308 1;
BA_ "VFrameFormat" BO_ 1308 14;
BA_ "GenMsgCycleTime" BO_ 384 10;
BA_ "GenMsgSendType" BO_ 384 0;
BA_ "VFrameFormat" BO_ 384 14;
BA_ "GenMsgCycleTime" BO_ 800 100;
BA_ "GenMsgSendType" BO_ 800 0;
BA_ "VFrameFormat" BO_ 800 14;
BA_ "GenMsgCycleTime" BO_ 1302 1000;
BA_ "GenMsgSendType" BO_ 1302 0;
BA_ "VFrameFormat" BO_ 1302 14;
BA_ "GenMsgCycleTime" BO_ 1328 500;
BA_ "GenMsgSendType" BO_ 1328 0;
BA_ "VFrameFormat" BO_ 1328 14;
BA_ "GenMsgCycleTime" BO_ 349 20;
BA_ "GenMsgSendType" BO_ 349 0;
BA_ "VFrameFormat" BO_ 349 14;
BA_ "GenMsgCycleTime" BO_ 632 20;
BA_ "GenMsgSendType" BO_ 632 0;
BA_ "VFrameFormat" BO_ 632 14;
BA_ "GenMsgCycleTime" BO_ 378 10;
BA_ "GenMsgSendType" BO_ 378 0;
BA_ "VFrameFormat" BO_ 378 14;
BA_ "GenMsgCycleTime" BO_ 523 20;
BA_ "GenMsgSendType" BO_ 523 0;
BA_ "VFrameFormat" BO_ 523 14;
BA_ "GenMsgCycleTime" BO_ 381 10;
BA_ "GenMsgSendType" BO_ 381 0;
BA_ "VFrameFormat" BO_ 381 14;
BA_ "GenMsgCycleTime" BO_ 398 10;
BA_ "GenMsgSendType" BO_ 398 0;
BA_ "VFrameFormat" BO_ 398 14;
BA_ "GenMsgCycleTime" BO_ 431 10;
BA_ "GenMsgSendType" BO_ 431 0;
BA_ "VFrameFormat" BO_ 431 14;
BA_ "GenMsgCycleTime" BO_ 424 10;
BA_ "GenMsgSendType" BO_ 424 0;
BA_ "VFrameFormat" BO_ 424 14;
BA_ "GenMsgCycleTime" BO_ 796 100;
BA_ "GenMsgSendType" BO_ 796 0;
BA_ "VFrameFormat" BO_ 796 14;
BA_ "GenMsgCycleTime" BO_ 651 40;
BA_ "GenMsgSendType" BO_ 651 0;
BA_ "VFrameFormat" BO_ 651 14;
BA_ "GenMsgCycleTime" BO_ 271 20;
BA_ "GenMsgSendType" BO_ 271 0;
BA_ "VFrameFormat" BO_ 271 14;
BA_ "GenMsgCycleTime" BO_ 80 500;
BA_ "GenMsgSendType" BO_ 80 0;
BA_ "VFrameFormat" BO_ 80 14;
BA_ "GenMsgCycleTime" BO_ 664 40;
BA_ "GenMsgSendType" BO_ 664 0;
BA_ "VFrameFormat" BO_ 664 14;
BA_ "GenMsgCycleTime" BO_ 721 40;
BA_ "GenMsgSendType" BO_ 721 0;
BA_ "VFrameFormat" BO_ 721 14;
BA_ "GenMsgCycleTime" BO_ 587 50;
BA_ "GenMsgSendType" BO_ 587 0;
BA_ "VFrameFormat" BO_ 587 14;
BA_ "GenMsgSendType" BO_ 1894 1;
BA_ "VFrameFormat" BO_ 1894 14;
BA_ "GenMsgSendType" BO_ 1902 1;
BA_ "VFrameFormat" BO_ 1902 14;
BA_ "GenMsgSendType" BO_ 1895 1;
BA_ "VFrameFormat" BO_ 1895 14;
BA_ "GenMsgSendType" BO_ 1903 1;
BA_ "VFrameFormat" BO_ 1903 14;
BA_ "GenMsgSendType" BO_ 1104 1;
BA_ "GenMsgSendType" BO_ 1110 1;
BA_ "GenMsgSendType" BO_ 1111 1;
BA_ "GenMsgCycleTime" BO_ 1442 1000;
BA_ "GenMsgSendType" BO_ 1442 0;
BA_ "VFrameFormat" BO_ 1442 14;
BA_ "GenMsgCycleTime" BO_ 1432 1000;
BA_ "GenMsgSendType" BO_ 1432 0;
BA_ "VFrameFormat" BO_ 1432 14;
BA_ "GenMsgCycleTime" BO_ 1763 500;
BA_ "GenMsgSendType" BO_ 1763 0;
BA_ "VFrameFormat" BO_ 1763 14;
BA_ "GenMsgCycleTime" BO_ 1776 500;
BA_ "GenMsgSendType" BO_ 1776 0;
BA_ "VFrameFormat" BO_ 1776 14;
BA_ "GenMsgCycleTime" BO_ 623 30;
BA_ "GenMsgSendType" BO_ 623 0;
BA_ "VFrameFormat" BO_ 623 14;
BA_ "GenMsgCycleTime" BO_ 697 50;
BA_ "GenMsgSendType" BO_ 697 0;
BA_ "VFrameFormat" BO_ 697 14;
BA_ "GenMsgCycleTime" BO_ 957 100;
BA_ "GenMsgSendType" BO_ 957 0;
BA_ "VFrameFormat" BO_ 957 14;

BA_ "GenSigCycleTime" SG_ 669 FLR_CRCCheck_29D 50;
BA_ "GenSigCycleTime" SG_ 669 FLR_RollingCounter_29D 50;
BA_ "GenSigCycleTime" SG_ 669 FLR_FreespaceSectorKinestate136 50;
BA_ "GenSigCycleTime" SG_ 669 FLR_FreespaceSectorConfidence136 50;
BA_ "GenSigCycleTime" SG_ 669 FLR_FreespaceSectorDistance136 50;
BA_ "GenSigCycleTime" SG_ 669 FLR_FreespaceSectorKinestate135 50;
BA_ "GenSigCycleTime" SG_ 669 FLR_FreespaceSectorConfidence135 50;
BA_ "GenSigCycleTime" SG_ 669 FLR_FreespaceSectorDistance135 50;
BA_ "GenSigCycleTime" SG_ 669 FLR_FreespaceSectorKinestate134 50;
BA_ "GenSigCycleTime" SG_ 669 FLR_FreespaceSectorConfidence134 50;
BA_ "GenSigCycleTime" SG_ 669 FLR_FreespaceSectorDistance134 50;
BA_ "GenSigCycleTime" SG_ 669 FLR_FreespaceSectorKinestate133 50;
BA_ "GenSigCycleTime" SG_ 669 FLR_FreespaceSectorConfidence133 50;
BA_ "GenSigCycleTime" SG_ 669 FLR_FreespaceSectorDistance133 50;
BA_ "GenSigCycleTime" SG_ 669 FLR_FreespaceSectorKinestate132 50;
BA_ "GenSigCycleTime" SG_ 669 FLR_FreespaceSectorConfidence132 50;
BA_ "GenSigCycleTime" SG_ 669 FLR_FreespaceSectorDistance132 50;
BA_ "GenSigCycleTime" SG_ 669 FLR_FreespaceSectorKinestate131 50;
BA_ "GenSigCycleTime" SG_ 669 FLR_FreespaceSectorConfidence131 50;
BA_ "GenSigCycleTime" SG_ 669 FLR_FreespaceSectorDistance131 50;
BA_ "GenSigCycleTime" SG_ 669 FLR_FreespaceSectorKinestate130 50;
BA_ "GenSigCycleTime" SG_ 669 FLR_FreespaceSectorConfidence130 50;
BA_ "GenSigCycleTime" SG_ 669 FLR_FreespaceSectorDistance130 50;
BA_ "GenSigCycleTime" SG_ 669 FLR_FreespaceSectorKinestate129 50;
BA_ "GenSigCycleTime" SG_ 669 FLR_FreespaceSectorConfidence129 50;
BA_ "GenSigCycleTime" SG_ 669 FLR_FreespaceSectorDistance129 50;
BA_ "GenSigCycleTime" SG_ 669 FLR_FreespaceSectorKinestate128 50;
BA_ "GenSigCycleTime" SG_ 669 FLR_FreespaceSectorConfidence128 50;
BA_ "GenSigCycleTime" SG_ 669 FLR_FreespaceSectorDistance128 50;
BA_ "GenSigCycleTime" SG_ 669 FLR_FreespaceSectorKinestate127 50;
BA_ "GenSigCycleTime" SG_ 669 FLR_FreespaceSectorConfidence127 50;
BA_ "GenSigCycleTime" SG_ 669 FLR_FreespaceSectorDistance127 50;
BA_ "GenSigCycleTime" SG_ 669 FLR_FreespaceSectorKinestate126 50;
BA_ "GenSigCycleTime" SG_ 669 FLR_FreespaceSectorConfidence126 50;
BA_ "GenSigCycleTime" SG_ 669 FLR_FreespaceSectorDistance126 50;
BA_ "GenSigCycleTime" SG_ 669 FLR_FreespaceSectorKinestate125 50;
BA_ "GenSigCycleTime" SG_ 669 FLR_FreespaceSectorConfidence125 50;
BA_ "GenSigCycleTime" SG_ 669 FLR_FreespaceSectorDistance125 50;
BA_ "GenSigCycleTime" SG_ 669 FLR_FreespaceSectorKinestate124 50;
BA_ "GenSigCycleTime" SG_ 669 FLR_FreespaceSectorConfidence124 50;
BA_ "GenSigCycleTime" SG_ 669 FLR_FreespaceSectorDistance124 50;
BA_ "GenSigCycleTime" SG_ 669 FLR_FreespaceSectorKinestate123 50;
BA_ "GenSigCycleTime" SG_ 669 FLR_FreespaceSectorConfidence123 50;
BA_ "GenSigCycleTime" SG_ 669 FLR_FreespaceSectorDistance123 50;
BA_ "GenSigCycleTime" SG_ 669 FLR_FreespaceSectorKinestate122 50;
BA_ "GenSigCycleTime" SG_ 669 FLR_FreespaceSectorConfidence122 50;
BA_ "GenSigCycleTime" SG_ 669 FLR_FreespaceSectorDistance122 50;
BA_ "GenSigCycleTime" SG_ 669 FLR_FreespaceSectorKinestate121 50;
BA_ "GenSigCycleTime" SG_ 669 FLR_FreespaceSectorConfidence121 50;
BA_ "GenSigCycleTime" SG_ 669 FLR_FreespaceSectorDistance121 50;
BA_ "GenSigCycleTime" SG_ 669 FLR_FreespaceSectorKinestate120 50;
BA_ "GenSigCycleTime" SG_ 669 FLR_FreespaceSectorConfidence120 50;
BA_ "GenSigCycleTime" SG_ 669 FLR_FreespaceSectorDistance120 50;
BA_ "GenSigCycleTime" SG_ 669 FLR_FreespaceSectorKinestate119 50;
BA_ "GenSigCycleTime" SG_ 669 FLR_FreespaceSectorConfidence119 50;
BA_ "GenSigCycleTime" SG_ 669 FLR_FreespaceSectorDistance119 50;
BA_ "GenSigCycleTime" SG_ 669 FLR_FreespaceSectorKinestate118 50;
BA_ "GenSigCycleTime" SG_ 669 FLR_FreespaceSectorConfidence118 50;
BA_ "GenSigCycleTime" SG_ 669 FLR_FreespaceSectorDistance118 50;
BA_ "GenSigCycleTime" SG_ 669 FLR_FreespaceSectorKinestate117 50;
BA_ "GenSigCycleTime" SG_ 669 FLR_FreespaceSectorConfidence117 50;
BA_ "GenSigCycleTime" SG_ 669 FLR_FreespaceSectorDistance117 50;
BA_ "GenSigCycleTime" SG_ 669 FLR_FreespaceSectorKinestate116 50;
BA_ "GenSigCycleTime" SG_ 669 FLR_FreespaceSectorConfidence116 50;
BA_ "GenSigCycleTime" SG_ 669 FLR_FreespaceSectorDistance116 50;
BA_ "GenSigCycleTime" SG_ 669 FLR_FreespaceSectorKinestate115 50;
BA_ "GenSigCycleTime" SG_ 669 FLR_FreespaceSectorConfidence115 50;
BA_ "GenSigCycleTime" SG_ 669 FLR_FreespaceSectorDistance115 50;
BA_ "GenSigCycleTime" SG_ 669 FLR_FreespaceSectorKinestate114 50;
BA_ "GenSigCycleTime" SG_ 669 FLR_FreespaceSectorConfidence114 50;
BA_ "GenSigCycleTime" SG_ 669 FLR_FreespaceSectorDistance114 50;
BA_ "GenSigCycleTime" SG_ 669 FLR_FreespaceSectorKinestate113 50;
BA_ "GenSigCycleTime" SG_ 669 FLR_FreespaceSectorConfidence113 50;
BA_ "GenSigCycleTime" SG_ 669 FLR_FreespaceSectorDistance113 50;
BA_ "GenSigCycleTime" SG_ 669 FLR_FreespaceSectorKinestate112 50;
BA_ "GenSigCycleTime" SG_ 669 FLR_FreespaceSectorConfidence112 50;
BA_ "GenSigCycleTime" SG_ 669 FLR_FreespaceSectorDistance112 50;
BA_ "GenSigCycleTime" SG_ 669 FLR_FreespaceSectorKinestate111 50;
BA_ "GenSigCycleTime" SG_ 669 FLR_FreespaceSectorConfidence111 50;
BA_ "GenSigCycleTime" SG_ 669 FLR_FreespaceSectorDistance111 50;
BA_ "GenSigCycleTime" SG_ 669 FLR_FreespaceSectorKinestate110 50;
BA_ "GenSigCycleTime" SG_ 669 FLR_FreespaceSectorConfidence110 50;
BA_ "GenSigCycleTime" SG_ 669 FLR_FreespaceSectorDistance110 50;
BA_ "GenSigCycleTime" SG_ 669 FLR_FreespaceSectorKinestate109 50;
BA_ "GenSigCycleTime" SG_ 669 FLR_FreespaceSectorConfidence109 50;
BA_ "GenSigCycleTime" SG_ 669 FLR_FreespaceSectorDistance109 50;
BA_ "GenSigCycleTime" SG_ 669 FLR_FreespaceSectorKinestate108 50;
BA_ "GenSigCycleTime" SG_ 669 FLR_FreespaceSectorConfidence108 50;
BA_ "GenSigCycleTime" SG_ 669 FLR_FreespaceSectorDistance108 50;
BA_ "GenSigCycleTime" SG_ 669 FLR_FreespaceSectorKinestate107 50;
BA_ "GenSigCycleTime" SG_ 669 FLR_FreespaceSectorConfidence107 50;
BA_ "GenSigCycleTime" SG_ 669 FLR_FreespaceSectorDistance107 50;
BA_ "GenSigCycleTime" SG_ 669 FLR_FreespaceSectorKinestate106 50;
BA_ "GenSigCycleTime" SG_ 669 FLR_FreespaceSectorConfidence106 50;
BA_ "GenSigCycleTime" SG_ 669 FLR_FreespaceSectorDistance106 50;
BA_ "GenSigCycleTime" SG_ 669 FLR_FreespaceSectorKinestate105 50;
BA_ "GenSigCycleTime" SG_ 669 FLR_FreespaceSectorConfidence105 50;
BA_ "GenSigCycleTime" SG_ 669 FLR_FreespaceSectorDistance105 50;
BA_ "GenSigCycleTime" SG_ 669 FLR_FreespaceSectorKinestate104 50;
BA_ "GenSigCycleTime" SG_ 669 FLR_FreespaceSectorConfidence104 50;
BA_ "GenSigCycleTime" SG_ 669 FLR_FreespaceSectorDistance104 50;
BA_ "GenSigCycleTime" SG_ 669 FLR_FreespaceSectorKinestate103 50;
BA_ "GenSigCycleTime" SG_ 669 FLR_FreespaceSectorConfidence103 50;
BA_ "GenSigCycleTime" SG_ 669 FLR_FreespaceSectorDistance103 50;

BA_ "GenSigCycleTime" SG_ 670 FLR_CRCCheck_29E 50;
BA_ "GenSigCycleTime" SG_ 670 FLR_RollingCounter_29E 50;
BA_ "GenSigCycleTime" SG_ 670 FLR_FreespaceSectorKinestate170 50;
BA_ "GenSigCycleTime" SG_ 670 FLR_FreespaceSectorConfidence170 50;
BA_ "GenSigCycleTime" SG_ 670 FLR_FreespaceSectorDistance170 50;
BA_ "GenSigCycleTime" SG_ 670 FLR_FreespaceSectorKinestate169 50;
BA_ "GenSigCycleTime" SG_ 670 FLR_FreespaceSectorConfidence169 50;
BA_ "GenSigCycleTime" SG_ 670 FLR_FreespaceSectorDistance169 50;
BA_ "GenSigCycleTime" SG_ 670 FLR_FreespaceSectorKinestate168 50;
BA_ "GenSigCycleTime" SG_ 670 FLR_FreespaceSectorConfidence168 50;
BA_ "GenSigCycleTime" SG_ 670 FLR_FreespaceSectorDistance168 50;
BA_ "GenSigCycleTime" SG_ 670 FLR_FreespaceSectorKinestate167 50;
BA_ "GenSigCycleTime" SG_ 670 FLR_FreespaceSectorConfidence167 50;
BA_ "GenSigCycleTime" SG_ 670 FLR_FreespaceSectorDistance167 50;
BA_ "GenSigCycleTime" SG_ 670 FLR_FreespaceSectorKinestate166 50;
BA_ "GenSigCycleTime" SG_ 670 FLR_FreespaceSectorConfidence166 50;
BA_ "GenSigCycleTime" SG_ 670 FLR_FreespaceSectorDistance166 50;
BA_ "GenSigCycleTime" SG_ 670 FLR_FreespaceSectorKinestate165 50;
BA_ "GenSigCycleTime" SG_ 670 FLR_FreespaceSectorConfidence165 50;
BA_ "GenSigCycleTime" SG_ 670 FLR_FreespaceSectorDistance165 50;
BA_ "GenSigCycleTime" SG_ 670 FLR_FreespaceSectorKinestate164 50;
BA_ "GenSigCycleTime" SG_ 670 FLR_FreespaceSectorConfidence164 50;
BA_ "GenSigCycleTime" SG_ 670 FLR_FreespaceSectorDistance164 50;
BA_ "GenSigCycleTime" SG_ 670 FLR_FreespaceSectorKinestate163 50;
BA_ "GenSigCycleTime" SG_ 670 FLR_FreespaceSectorConfidence163 50;
BA_ "GenSigCycleTime" SG_ 670 FLR_FreespaceSectorDistance163 50;
BA_ "GenSigCycleTime" SG_ 670 FLR_FreespaceSectorKinestate162 50;
BA_ "GenSigCycleTime" SG_ 670 FLR_FreespaceSectorConfidence162 50;
BA_ "GenSigCycleTime" SG_ 670 FLR_FreespaceSectorDistance162 50;
BA_ "GenSigCycleTime" SG_ 670 FLR_FreespaceSectorKinestate161 50;
BA_ "GenSigCycleTime" SG_ 670 FLR_FreespaceSectorConfidence161 50;
BA_ "GenSigCycleTime" SG_ 670 FLR_FreespaceSectorDistance161 50;
BA_ "GenSigCycleTime" SG_ 670 FLR_FreespaceSectorKinestate160 50;
BA_ "GenSigCycleTime" SG_ 670 FLR_FreespaceSectorConfidence160 50;
BA_ "GenSigCycleTime" SG_ 670 FLR_FreespaceSectorDistance160 50;
BA_ "GenSigCycleTime" SG_ 670 FLR_FreespaceSectorKinestate159 50;
BA_ "GenSigCycleTime" SG_ 670 FLR_FreespaceSectorConfidence159 50;
BA_ "GenSigCycleTime" SG_ 670 FLR_FreespaceSectorDistance159 50;
BA_ "GenSigCycleTime" SG_ 670 FLR_FreespaceSectorKinestate158 50;
BA_ "GenSigCycleTime" SG_ 670 FLR_FreespaceSectorConfidence158 50;
BA_ "GenSigCycleTime" SG_ 670 FLR_FreespaceSectorDistance158 50;
BA_ "GenSigCycleTime" SG_ 670 FLR_FreespaceSectorKinestate157 50;
BA_ "GenSigCycleTime" SG_ 670 FLR_FreespaceSectorConfidence157 50;
BA_ "GenSigCycleTime" SG_ 670 FLR_FreespaceSectorDistance157 50;
BA_ "GenSigCycleTime" SG_ 670 FLR_FreespaceSectorKinestate156 50;
BA_ "GenSigCycleTime" SG_ 670 FLR_FreespaceSectorConfidence156 50;
BA_ "GenSigCycleTime" SG_ 670 FLR_FreespaceSectorDistance156 50;
BA_ "GenSigCycleTime" SG_ 670 FLR_FreespaceSectorKinestate155 50;
BA_ "GenSigCycleTime" SG_ 670 FLR_FreespaceSectorConfidence155 50;
BA_ "GenSigCycleTime" SG_ 670 FLR_FreespaceSectorDistance155 50;
BA_ "GenSigCycleTime" SG_ 670 FLR_FreespaceSectorKinestate154 50;
BA_ "GenSigCycleTime" SG_ 670 FLR_FreespaceSectorConfidence154 50;
BA_ "GenSigCycleTime" SG_ 670 FLR_FreespaceSectorDistance154 50;
BA_ "GenSigCycleTime" SG_ 670 FLR_FreespaceSectorKinestate153 50;
BA_ "GenSigCycleTime" SG_ 670 FLR_FreespaceSectorConfidence153 50;
BA_ "GenSigCycleTime" SG_ 670 FLR_FreespaceSectorDistance153 50;
BA_ "GenSigCycleTime" SG_ 670 FLR_FreespaceSectorKinestate152 50;
BA_ "GenSigCycleTime" SG_ 670 FLR_FreespaceSectorConfidence152 50;
BA_ "GenSigCycleTime" SG_ 670 FLR_FreespaceSectorDistance152 50;
BA_ "GenSigCycleTime" SG_ 670 FLR_FreespaceSectorKinestate151 50;
BA_ "GenSigCycleTime" SG_ 670 FLR_FreespaceSectorConfidence151 50;
BA_ "GenSigCycleTime" SG_ 670 FLR_FreespaceSectorDistance151 50;
BA_ "GenSigCycleTime" SG_ 670 FLR_FreespaceSectorKinestate150 50;
BA_ "GenSigCycleTime" SG_ 670 FLR_FreespaceSectorConfidence150 50;
BA_ "GenSigCycleTime" SG_ 670 FLR_FreespaceSectorDistance150 50;
BA_ "GenSigCycleTime" SG_ 670 FLR_FreespaceSectorKinestate149 50;
BA_ "GenSigCycleTime" SG_ 670 FLR_FreespaceSectorConfidence149 50;
BA_ "GenSigCycleTime" SG_ 670 FLR_FreespaceSectorDistance149 50;
BA_ "GenSigCycleTime" SG_ 670 FLR_FreespaceSectorKinestate148 50;
BA_ "GenSigCycleTime" SG_ 670 FLR_FreespaceSectorConfidence148 50;
BA_ "GenSigCycleTime" SG_ 670 FLR_FreespaceSectorDistance148 50;
BA_ "GenSigCycleTime" SG_ 670 FLR_FreespaceSectorKinestate147 50;
BA_ "GenSigCycleTime" SG_ 670 FLR_FreespaceSectorConfidence147 50;
BA_ "GenSigCycleTime" SG_ 670 FLR_FreespaceSectorDistance147 50;
BA_ "GenSigCycleTime" SG_ 670 FLR_FreespaceSectorKinestate146 50;
BA_ "GenSigCycleTime" SG_ 670 FLR_FreespaceSectorConfidence146 50;
BA_ "GenSigCycleTime" SG_ 670 FLR_FreespaceSectorDistance146 50;
BA_ "GenSigCycleTime" SG_ 670 FLR_FreespaceSectorKinestate145 50;
BA_ "GenSigCycleTime" SG_ 670 FLR_FreespaceSectorConfidence145 50;
BA_ "GenSigCycleTime" SG_ 670 FLR_FreespaceSectorDistance145 50;
BA_ "GenSigCycleTime" SG_ 670 FLR_FreespaceSectorKinestate144 50;
BA_ "GenSigCycleTime" SG_ 670 FLR_FreespaceSectorConfidence144 50;
BA_ "GenSigCycleTime" SG_ 670 FLR_FreespaceSectorDistance144 50;
BA_ "GenSigCycleTime" SG_ 670 FLR_FreespaceSectorKinestate143 50;
BA_ "GenSigCycleTime" SG_ 670 FLR_FreespaceSectorConfidence143 50;
BA_ "GenSigCycleTime" SG_ 670 FLR_FreespaceSectorDistance143 50;
BA_ "GenSigCycleTime" SG_ 670 FLR_FreespaceSectorKinestate142 50;
BA_ "GenSigCycleTime" SG_ 670 FLR_FreespaceSectorConfidence142 50;
BA_ "GenSigCycleTime" SG_ 670 FLR_FreespaceSectorDistance142 50;
BA_ "GenSigCycleTime" SG_ 670 FLR_FreespaceSectorKinestate141 50;
BA_ "GenSigCycleTime" SG_ 670 FLR_FreespaceSectorConfidence141 50;
BA_ "GenSigCycleTime" SG_ 670 FLR_FreespaceSectorDistance141 50;
BA_ "GenSigCycleTime" SG_ 670 FLR_FreespaceSectorKinestate140 50;
BA_ "GenSigCycleTime" SG_ 670 FLR_FreespaceSectorConfidence140 50;
BA_ "GenSigCycleTime" SG_ 670 FLR_FreespaceSectorDistance140 50;
BA_ "GenSigCycleTime" SG_ 670 FLR_FreespaceSectorKinestate139 50;
BA_ "GenSigCycleTime" SG_ 670 FLR_FreespaceSectorConfidence139 50;
BA_ "GenSigCycleTime" SG_ 670 FLR_FreespaceSectorDistance139 50;
BA_ "GenSigCycleTime" SG_ 670 FLR_FreespaceSectorKinestate138 50;
BA_ "GenSigCycleTime" SG_ 670 FLR_FreespaceSectorConfidence138 50;
BA_ "GenSigCycleTime" SG_ 670 FLR_FreespaceSectorDistance138 50;
BA_ "GenSigCycleTime" SG_ 670 FLR_FreespaceSectorKinestate137 50;
BA_ "GenSigCycleTime" SG_ 670 FLR_FreespaceSectorConfidence137 50;
BA_ "GenSigCycleTime" SG_ 670 FLR_FreespaceSectorDistance137 50;

BA_ "GenSigCycleTime" SG_ 671 FLR_CRCCheck_29F 50;
BA_ "GenSigCycleTime" SG_ 671 FLR_RollingCounter_29F 50;
BA_ "GenSigCycleTime" SG_ 671 FLR_FreespaceSectorKinestate204 50;
BA_ "GenSigCycleTime" SG_ 671 FLR_FreespaceSectorConfidence204 50;
BA_ "GenSigCycleTime" SG_ 671 FLR_FreespaceSectorDistance204 50;
BA_ "GenSigCycleTime" SG_ 671 FLR_FreespaceSectorKinestate203 50;
BA_ "GenSigCycleTime" SG_ 671 FLR_FreespaceSectorConfidence203 50;
BA_ "GenSigCycleTime" SG_ 671 FLR_FreespaceSectorDistance203 50;
BA_ "GenSigCycleTime" SG_ 671 FLR_FreespaceSectorKinestate202 50;
BA_ "GenSigCycleTime" SG_ 671 FLR_FreespaceSectorConfidence202 50;
BA_ "GenSigCycleTime" SG_ 671 FLR_FreespaceSectorDistance202 50;
BA_ "GenSigCycleTime" SG_ 671 FLR_FreespaceSectorKinestate201 50;
BA_ "GenSigCycleTime" SG_ 671 FLR_FreespaceSectorConfidence201 50;
BA_ "GenSigCycleTime" SG_ 671 FLR_FreespaceSectorDistance201 50;
BA_ "GenSigCycleTime" SG_ 671 FLR_FreespaceSectorKinestate200 50;
BA_ "GenSigCycleTime" SG_ 671 FLR_FreespaceSectorConfidence200 50;
BA_ "GenSigCycleTime" SG_ 671 FLR_FreespaceSectorDistance200 50;
BA_ "GenSigCycleTime" SG_ 671 FLR_FreespaceSectorKinestate199 50;
BA_ "GenSigCycleTime" SG_ 671 FLR_FreespaceSectorConfidence199 50;
BA_ "GenSigCycleTime" SG_ 671 FLR_FreespaceSectorDistance199 50;
BA_ "GenSigCycleTime" SG_ 671 FLR_FreespaceSectorKinestate198 50;
BA_ "GenSigCycleTime" SG_ 671 FLR_FreespaceSectorConfidence198 50;
BA_ "GenSigCycleTime" SG_ 671 FLR_FreespaceSectorDistance198 50;
BA_ "GenSigCycleTime" SG_ 671 FLR_FreespaceSectorKinestate197 50;
BA_ "GenSigCycleTime" SG_ 671 FLR_FreespaceSectorConfidence197 50;
BA_ "GenSigCycleTime" SG_ 671 FLR_FreespaceSectorDistance197 50;
BA_ "GenSigCycleTime" SG_ 671 FLR_FreespaceSectorKinestate196 50;
BA_ "GenSigCycleTime" SG_ 671 FLR_FreespaceSectorConfidence196 50;
BA_ "GenSigCycleTime" SG_ 671 FLR_FreespaceSectorDistance196 50;
BA_ "GenSigCycleTime" SG_ 671 FLR_FreespaceSectorKinestate195 50;
BA_ "GenSigCycleTime" SG_ 671 FLR_FreespaceSectorConfidence195 50;
BA_ "GenSigCycleTime" SG_ 671 FLR_FreespaceSectorDistance195 50;
BA_ "GenSigCycleTime" SG_ 671 FLR_FreespaceSectorKinestate194 50;
BA_ "GenSigCycleTime" SG_ 671 FLR_FreespaceSectorConfidence194 50;
BA_ "GenSigCycleTime" SG_ 671 FLR_FreespaceSectorDistance194 50;
BA_ "GenSigCycleTime" SG_ 671 FLR_FreespaceSectorKinestate193 50;
BA_ "GenSigCycleTime" SG_ 671 FLR_FreespaceSectorConfidence193 50;
BA_ "GenSigCycleTime" SG_ 671 FLR_FreespaceSectorDistance193 50;
BA_ "GenSigCycleTime" SG_ 671 FLR_FreespaceSectorKinestate192 50;
BA_ "GenSigCycleTime" SG_ 671 FLR_FreespaceSectorConfidence192 50;
BA_ "GenSigCycleTime" SG_ 671 FLR_FreespaceSectorDistance192 50;
BA_ "GenSigCycleTime" SG_ 671 FLR_FreespaceSectorKinestate191 50;
BA_ "GenSigCycleTime" SG_ 671 FLR_FreespaceSectorConfidence191 50;
BA_ "GenSigCycleTime" SG_ 671 FLR_FreespaceSectorDistance191 50;
BA_ "GenSigCycleTime" SG_ 671 FLR_FreespaceSectorKinestate190 50;
BA_ "GenSigCycleTime" SG_ 671 FLR_FreespaceSectorConfidence190 50;
BA_ "GenSigCycleTime" SG_ 671 FLR_FreespaceSectorDistance190 50;
BA_ "GenSigCycleTime" SG_ 671 FLR_FreespaceSectorKinestate189 50;
BA_ "GenSigCycleTime" SG_ 671 FLR_FreespaceSectorConfidence189 50;
BA_ "GenSigCycleTime" SG_ 671 FLR_FreespaceSectorDistance189 50;
BA_ "GenSigCycleTime" SG_ 671 FLR_FreespaceSectorKinestate188 50;
BA_ "GenSigCycleTime" SG_ 671 FLR_FreespaceSectorConfidence188 50;
BA_ "GenSigCycleTime" SG_ 671 FLR_FreespaceSectorDistance188 50;
BA_ "GenSigCycleTime" SG_ 671 FLR_FreespaceSectorKinestate187 50;
BA_ "GenSigCycleTime" SG_ 671 FLR_FreespaceSectorConfidence187 50;
BA_ "GenSigCycleTime" SG_ 671 FLR_FreespaceSectorDistance187 50;
BA_ "GenSigCycleTime" SG_ 671 FLR_FreespaceSectorKinestate186 50;
BA_ "GenSigCycleTime" SG_ 671 FLR_FreespaceSectorConfidence186 50;
BA_ "GenSigCycleTime" SG_ 671 FLR_FreespaceSectorDistance186 50;
BA_ "GenSigCycleTime" SG_ 671 FLR_FreespaceSectorKinestate185 50;
BA_ "GenSigCycleTime" SG_ 671 FLR_FreespaceSectorConfidence185 50;
BA_ "GenSigCycleTime" SG_ 671 FLR_FreespaceSectorDistance185 50;
BA_ "GenSigCycleTime" SG_ 671 FLR_FreespaceSectorKinestate184 50;
BA_ "GenSigCycleTime" SG_ 671 FLR_FreespaceSectorConfidence184 50;
BA_ "GenSigCycleTime" SG_ 671 FLR_FreespaceSectorDistance184 50;
BA_ "GenSigCycleTime" SG_ 671 FLR_FreespaceSectorKinestate183 50;
BA_ "GenSigCycleTime" SG_ 671 FLR_FreespaceSectorConfidence183 50;
BA_ "GenSigCycleTime" SG_ 671 FLR_FreespaceSectorDistance183 50;
BA_ "GenSigCycleTime" SG_ 671 FLR_FreespaceSectorKinestate182 50;
BA_ "GenSigCycleTime" SG_ 671 FLR_FreespaceSectorConfidence182 50;
BA_ "GenSigCycleTime" SG_ 671 FLR_FreespaceSectorDistance182 50;
BA_ "GenSigCycleTime" SG_ 671 FLR_FreespaceSectorKinestate181 50;
BA_ "GenSigCycleTime" SG_ 671 FLR_FreespaceSectorConfidence181 50;
BA_ "GenSigCycleTime" SG_ 671 FLR_FreespaceSectorDistance181 50;
BA_ "GenSigCycleTime" SG_ 671 FLR_FreespaceSectorKinestate180 50;
BA_ "GenSigCycleTime" SG_ 671 FLR_FreespaceSectorConfidence180 50;
BA_ "GenSigCycleTime" SG_ 671 FLR_FreespaceSectorDistance180 50;
BA_ "GenSigCycleTime" SG_ 671 FLR_FreespaceSectorKinestate179 50;
BA_ "GenSigCycleTime" SG_ 671 FLR_FreespaceSectorConfidence179 50;
BA_ "GenSigCycleTime" SG_ 671 FLR_FreespaceSectorDistance179 50;
BA_ "GenSigCycleTime" SG_ 671 FLR_FreespaceSectorKinestate178 50;
BA_ "GenSigCycleTime" SG_ 671 FLR_FreespaceSectorConfidence178 50;
BA_ "GenSigCycleTime" SG_ 671 FLR_FreespaceSectorDistance178 50;
BA_ "GenSigCycleTime" SG_ 671 FLR_FreespaceSectorKinestate177 50;
BA_ "GenSigCycleTime" SG_ 671 FLR_FreespaceSectorConfidence177 50;
BA_ "GenSigCycleTime" SG_ 671 FLR_FreespaceSectorDistance177 50;
BA_ "GenSigCycleTime" SG_ 671 FLR_FreespaceSectorKinestate176 50;
BA_ "GenSigCycleTime" SG_ 671 FLR_FreespaceSectorConfidence176 50;
BA_ "GenSigCycleTime" SG_ 671 FLR_FreespaceSectorDistance176 50;
BA_ "GenSigCycleTime" SG_ 671 FLR_FreespaceSectorKinestate175 50;
BA_ "GenSigCycleTime" SG_ 671 FLR_FreespaceSectorConfidence175 50;
BA_ "GenSigCycleTime" SG_ 671 FLR_FreespaceSectorDistance175 50;
BA_ "GenSigCycleTime" SG_ 671 FLR_FreespaceSectorKinestate174 50;
BA_ "GenSigCycleTime" SG_ 671 FLR_FreespaceSectorConfidence174 50;
BA_ "GenSigCycleTime" SG_ 671 FLR_FreespaceSectorDistance174 50;
BA_ "GenSigCycleTime" SG_ 671 FLR_FreespaceSectorKinestate173 50;
BA_ "GenSigCycleTime" SG_ 671 FLR_FreespaceSectorConfidence173 50;
BA_ "GenSigCycleTime" SG_ 671 FLR_FreespaceSectorDistance173 50;
BA_ "GenSigCycleTime" SG_ 671 FLR_FreespaceSectorKinestate172 50;
BA_ "GenSigCycleTime" SG_ 671 FLR_FreespaceSectorConfidence172 50;
BA_ "GenSigCycleTime" SG_ 671 FLR_FreespaceSectorDistance172 50;
BA_ "GenSigCycleTime" SG_ 671 FLR_FreespaceSectorKinestate171 50;
BA_ "GenSigCycleTime" SG_ 671 FLR_FreespaceSectorConfidence171 50;
BA_ "GenSigCycleTime" SG_ 671 FLR_FreespaceSectorDistance171 50;

BA_ "GenSigCycleTime" SG_ 768 FLR_CRCCheck_300 50;
BA_ "GenSigCycleTime" SG_ 768 FLR_RollingCounter_300 50;
BA_ "GenSigCycleTime" SG_ 768 FLR_FreespaceSectorKinestate238 50;
BA_ "GenSigCycleTime" SG_ 768 FLR_FreespaceSectorConfidence238 50;
BA_ "GenSigCycleTime" SG_ 768 FLR_FreespaceSectorDistance238 50;
BA_ "GenSigCycleTime" SG_ 768 FLR_FreespaceSectorKinestate237 50;
BA_ "GenSigCycleTime" SG_ 768 FLR_FreespaceSectorConfidence237 50;
BA_ "GenSigCycleTime" SG_ 768 FLR_FreespaceSectorDistance237 50;
BA_ "GenSigCycleTime" SG_ 768 FLR_FreespaceSectorKinestate236 50;
BA_ "GenSigCycleTime" SG_ 768 FLR_FreespaceSectorConfidence236 50;
BA_ "GenSigCycleTime" SG_ 768 FLR_FreespaceSectorDistance236 50;
BA_ "GenSigCycleTime" SG_ 768 FLR_FreespaceSectorKinestate235 50;
BA_ "GenSigCycleTime" SG_ 768 FLR_FreespaceSectorConfidence235 50;
BA_ "GenSigCycleTime" SG_ 768 FLR_FreespaceSectorDistance235 50;
BA_ "GenSigCycleTime" SG_ 768 FLR_FreespaceSectorKinestate234 50;
BA_ "GenSigCycleTime" SG_ 768 FLR_FreespaceSectorConfidence234 50;
BA_ "GenSigCycleTime" SG_ 768 FLR_FreespaceSectorDistance234 50;
BA_ "GenSigCycleTime" SG_ 768 FLR_FreespaceSectorKinestate233 50;
BA_ "GenSigCycleTime" SG_ 768 FLR_FreespaceSectorConfidence233 50;
BA_ "GenSigCycleTime" SG_ 768 FLR_FreespaceSectorDistance233 50;
BA_ "GenSigCycleTime" SG_ 768 FLR_FreespaceSectorKinestate232 50;
BA_ "GenSigCycleTime" SG_ 768 FLR_FreespaceSectorConfidence232 50;
BA_ "GenSigCycleTime" SG_ 768 FLR_FreespaceSectorDistance232 50;
BA_ "GenSigCycleTime" SG_ 768 FLR_FreespaceSectorKinestate231 50;
BA_ "GenSigCycleTime" SG_ 768 FLR_FreespaceSectorConfidence231 50;
BA_ "GenSigCycleTime" SG_ 768 FLR_FreespaceSectorDistance231 50;
BA_ "GenSigCycleTime" SG_ 768 FLR_FreespaceSectorKinestate230 50;
BA_ "GenSigCycleTime" SG_ 768 FLR_FreespaceSectorConfidence230 50;
BA_ "GenSigCycleTime" SG_ 768 FLR_FreespaceSectorDistance230 50;
BA_ "GenSigCycleTime" SG_ 768 FLR_FreespaceSectorKinestate229 50;
BA_ "GenSigCycleTime" SG_ 768 FLR_FreespaceSectorConfidence229 50;
BA_ "GenSigCycleTime" SG_ 768 FLR_FreespaceSectorDistance229 50;
BA_ "GenSigCycleTime" SG_ 768 FLR_FreespaceSectorKinestate228 50;
BA_ "GenSigCycleTime" SG_ 768 FLR_FreespaceSectorConfidence228 50;
BA_ "GenSigCycleTime" SG_ 768 FLR_FreespaceSectorDistance228 50;
BA_ "GenSigCycleTime" SG_ 768 FLR_FreespaceSectorKinestate227 50;
BA_ "GenSigCycleTime" SG_ 768 FLR_FreespaceSectorConfidence227 50;
BA_ "GenSigCycleTime" SG_ 768 FLR_FreespaceSectorDistance227 50;
BA_ "GenSigCycleTime" SG_ 768 FLR_FreespaceSectorKinestate226 50;
BA_ "GenSigCycleTime" SG_ 768 FLR_FreespaceSectorConfidence226 50;
BA_ "GenSigCycleTime" SG_ 768 FLR_FreespaceSectorDistance226 50;
BA_ "GenSigCycleTime" SG_ 768 FLR_FreespaceSectorKinestate225 50;
BA_ "GenSigCycleTime" SG_ 768 FLR_FreespaceSectorConfidence225 50;
BA_ "GenSigCycleTime" SG_ 768 FLR_FreespaceSectorDistance225 50;
BA_ "GenSigCycleTime" SG_ 768 FLR_FreespaceSectorKinestate224 50;
BA_ "GenSigCycleTime" SG_ 768 FLR_FreespaceSectorConfidence224 50;
BA_ "GenSigCycleTime" SG_ 768 FLR_FreespaceSectorDistance224 50;
BA_ "GenSigCycleTime" SG_ 768 FLR_FreespaceSectorKinestate223 50;
BA_ "GenSigCycleTime" SG_ 768 FLR_FreespaceSectorConfidence223 50;
BA_ "GenSigCycleTime" SG_ 768 FLR_FreespaceSectorDistance223 50;
BA_ "GenSigCycleTime" SG_ 768 FLR_FreespaceSectorKinestate222 50;
BA_ "GenSigCycleTime" SG_ 768 FLR_FreespaceSectorConfidence222 50;
BA_ "GenSigCycleTime" SG_ 768 FLR_FreespaceSectorDistance222 50;
BA_ "GenSigCycleTime" SG_ 768 FLR_FreespaceSectorKinestate221 50;
BA_ "GenSigCycleTime" SG_ 768 FLR_FreespaceSectorConfidence221 50;
BA_ "GenSigCycleTime" SG_ 768 FLR_FreespaceSectorDistance221 50;
BA_ "GenSigCycleTime" SG_ 768 FLR_FreespaceSectorKinestate220 50;
BA_ "GenSigCycleTime" SG_ 768 FLR_FreespaceSectorConfidence220 50;
BA_ "GenSigCycleTime" SG_ 768 FLR_FreespaceSectorDistance220 50;
BA_ "GenSigCycleTime" SG_ 768 FLR_FreespaceSectorKinestate219 50;
BA_ "GenSigCycleTime" SG_ 768 FLR_FreespaceSectorConfidence219 50;
BA_ "GenSigCycleTime" SG_ 768 FLR_FreespaceSectorDistance219 50;
BA_ "GenSigCycleTime" SG_ 768 FLR_FreespaceSectorKinestate218 50;
BA_ "GenSigCycleTime" SG_ 768 FLR_FreespaceSectorConfidence218 50;
BA_ "GenSigCycleTime" SG_ 768 FLR_FreespaceSectorDistance218 50;
BA_ "GenSigCycleTime" SG_ 768 FLR_FreespaceSectorKinestate217 50;
BA_ "GenSigCycleTime" SG_ 768 FLR_FreespaceSectorConfidence217 50;
BA_ "GenSigCycleTime" SG_ 768 FLR_FreespaceSectorDistance217 50;
BA_ "GenSigCycleTime" SG_ 768 FLR_FreespaceSectorKinestate216 50;
BA_ "GenSigCycleTime" SG_ 768 FLR_FreespaceSectorConfidence216 50;
BA_ "GenSigCycleTime" SG_ 768 FLR_FreespaceSectorDistance216 50;
BA_ "GenSigCycleTime" SG_ 768 FLR_FreespaceSectorKinestate215 50;
BA_ "GenSigCycleTime" SG_ 768 FLR_FreespaceSectorConfidence215 50;
BA_ "GenSigCycleTime" SG_ 768 FLR_FreespaceSectorDistance215 50;
BA_ "GenSigCycleTime" SG_ 768 FLR_FreespaceSectorKinestate214 50;
BA_ "GenSigCycleTime" SG_ 768 FLR_FreespaceSectorConfidence214 50;
BA_ "GenSigCycleTime" SG_ 768 FLR_FreespaceSectorDistance214 50;
BA_ "GenSigCycleTime" SG_ 768 FLR_FreespaceSectorKinestate213 50;
BA_ "GenSigCycleTime" SG_ 768 FLR_FreespaceSectorConfidence213 50;
BA_ "GenSigCycleTime" SG_ 768 FLR_FreespaceSectorDistance213 50;
BA_ "GenSigCycleTime" SG_ 768 FLR_FreespaceSectorKinestate212 50;
BA_ "GenSigCycleTime" SG_ 768 FLR_FreespaceSectorConfidence212 50;
BA_ "GenSigCycleTime" SG_ 768 FLR_FreespaceSectorDistance212 50;
BA_ "GenSigCycleTime" SG_ 768 FLR_FreespaceSectorKinestate211 50;
BA_ "GenSigCycleTime" SG_ 768 FLR_FreespaceSectorConfidence211 50;
BA_ "GenSigCycleTime" SG_ 768 FLR_FreespaceSectorDistance211 50;
BA_ "GenSigCycleTime" SG_ 768 FLR_FreespaceSectorKinestate210 50;
BA_ "GenSigCycleTime" SG_ 768 FLR_FreespaceSectorConfidence210 50;
BA_ "GenSigCycleTime" SG_ 768 FLR_FreespaceSectorDistance210 50;
BA_ "GenSigCycleTime" SG_ 768 FLR_FreespaceSectorKinestate209 50;
BA_ "GenSigCycleTime" SG_ 768 FLR_FreespaceSectorConfidence209 50;
BA_ "GenSigCycleTime" SG_ 768 FLR_FreespaceSectorDistance209 50;
BA_ "GenSigCycleTime" SG_ 768 FLR_FreespaceSectorKinestate208 50;
BA_ "GenSigCycleTime" SG_ 768 FLR_FreespaceSectorConfidence208 50;
BA_ "GenSigCycleTime" SG_ 768 FLR_FreespaceSectorDistance208 50;
BA_ "GenSigCycleTime" SG_ 768 FLR_FreespaceSectorKinestate207 50;
BA_ "GenSigCycleTime" SG_ 768 FLR_FreespaceSectorConfidence207 50;
BA_ "GenSigCycleTime" SG_ 768 FLR_FreespaceSectorDistance207 50;
BA_ "GenSigCycleTime" SG_ 768 FLR_FreespaceSectorKinestate206 50;
BA_ "GenSigCycleTime" SG_ 768 FLR_FreespaceSectorConfidence206 50;
BA_ "GenSigCycleTime" SG_ 768 FLR_FreespaceSectorDistance206 50;
BA_ "GenSigCycleTime" SG_ 768 FLR_FreespaceSectorKinestate205 50;
BA_ "GenSigCycleTime" SG_ 768 FLR_FreespaceSectorConfidence205 50;
BA_ "GenSigCycleTime" SG_ 768 FLR_FreespaceSectorDistance205 50;

BA_ "GenSigCycleTime" SG_ 771 FLR_CRCCheck_303 50;
BA_ "GenSigCycleTime" SG_ 771 FLR_RollingCounter_301 50;
BA_ "GenSigCycleTime" SG_ 771 FLR_FreespaceSectorKinestate240 50;
BA_ "GenSigCycleTime" SG_ 771 FLR_FreespaceSectorConfidence240 50;
BA_ "GenSigCycleTime" SG_ 771 FLR_FreespaceSectorDistance240 50;
BA_ "GenSigCycleTime" SG_ 771 FLR_FreespaceSectorKinestate239 50;
BA_ "GenSigCycleTime" SG_ 771 FLR_FreespaceSectorConfidence239 50;
BA_ "GenSigCycleTime" SG_ 771 FLR_FreespaceSectorDistance239 50;

BA_ "GenSigCycleTime" SG_ 691 RLR_CRCCheck_2B3 50;
BA_ "GenSigCycleTime" SG_ 691 RLR_RollingCounter_2B3 50;
BA_ "GenSigCycleTime" SG_ 691 FRR_ResetSts 50;
BA_ "GenSigInvalidValue" SG_ 691 FRR_ResetSts "7";
BA_ "GenSigCycleTime" SG_ 691 FuncDegradeType_FR 50;
BA_ "GenSigCycleTime" SG_ 691 FUSION_TimeoutCnt_FR 50;
BA_ "GenSigCycleTime" SG_ 691 VALIDATION_TimeoutCnt_FR 50;
BA_ "GenSigCycleTime" SG_ 691 CurFrameCycle_FR 50;
BA_ "GenSigCycleTime" SG_ 691 ProcessTimeoutCnt_FR 50;
BA_ "GenSigCycleTime" SG_ 691 RevFrameCnt_FR 50;
BA_ "GenSigCycleTime" SG_ 691 Local_Pointcloud_Number_FR 50;
BA_ "GenSigCycleTime" SG_ 691 RealTimeCal_PrcssBar_FR 50;
BA_ "GenSigCycleTime" SG_ 691 RealTimeCal_VelErrOutput_FR 50;
BA_ "GenSigCycleTime" SG_ 691 RealTimeCal_HoriMntErrOutput_FR 50;
BA_ "GenSigCycleTime" SG_ 691 RealTimeCal_FailReasonCode_FR 50;
BA_ "GenSigCycleTime" SG_ 691 RealTimeCal_Status_FR 50;
BA_ "GenSigCycleTime" SG_ 691 DiagCal_PrcssBar_FR 50;
BA_ "GenSigCycleTime" SG_ 691 DiagCal_VelErrOutput_FR 50;
BA_ "GenSigCycleTime" SG_ 691 DiagCal_HoriMntErrOutput_FR 50;
BA_ "GenSigCycleTime" SG_ 691 DiagCal_FailReasonCode_FR 50;
BA_ "GenSigCycleTime" SG_ 691 DiagCal_Status_FR 50;
BA_ "GenSigCycleTime" SG_ 691 EolCal_PrcssBar_FR 50;
BA_ "GenSigCycleTime" SG_ 691 EolCal_VelErrOutput_FR 50;
BA_ "GenSigCycleTime" SG_ 691 EolCal_HoriMntErrOutput_FR 50;
BA_ "GenSigCycleTime" SG_ 691 EolCal_FailReasonCode_FR 50;
BA_ "GenSigCycleTime" SG_ 691 EolCal_Status_FR 50;
BA_ "GenSigCycleTime" SG_ 691 PriCounter 50;
BA_ "GenSigCycleTime" SG_ 691 MsgCounter_FR 50;

BA_ "GenSigCycleTime" SG_ 338 ADR_TriggerEventReq 10;
BA_ "GenSigCycleTime" SG_ 338 ADC_RollingCounter_152 10;
BA_ "GenSigCycleTime" SG_ 338 ADC_CRCCheck_152 10;
BA_ "GenSigCycleTime" SG_ 338 ACC_AEBEnable 10;
BA_ "GenSigStartValue" SG_ 338 ACC_AEBEnable 1.000000;
BA_ "GenSigCycleTime" SG_ 338 ACC_FCWSettingStatus 10;
BA_ "GenSigStartValue" SG_ 338 ACC_FCWSettingStatus 1.000000;
BA_ "GenSigCycleTime" SG_ 338 ADC_SenceMode 10;
BA_ "GenSigInvalidValue" SG_ 338 ADC_SenceMode "0";

BA_ "GenSigSendType" SG_ 1308 AD_SYNC_Sync_Time 1;
BA_ "GenSigSendType" SG_ 1308 AD_SYNC_UserByte_OVS_SGW 1;
BA_ "GenSigSendType" SG_ 1308 AD_SYNC_TimeDomain 1;
BA_ "GenSigSendType" SG_ 1308 AD_SYNC_Sequence 1;
BA_ "GenSigSendType" SG_ 1308 AD_SYNC_CRC 1;
BA_ "GenSigSendType" SG_ 1308 AD_SYNC_Type 1;

BA_ "GenSigCycleTime" SG_ 384 SAS_SteeringAngleValid 10;
BA_ "GenSigInvalidValue" SG_ 384 SAS_SteeringAngleValid "1";
BA_ "GenSigCycleTime" SG_ 384 SAS_SteeringAngleSpeed 10;
BA_ "GenSigInvalidValue" SG_ 384 SAS_SteeringAngleSpeed "255";
BA_ "GenSigCycleTime" SG_ 384 SAS_SteeringAngle 10;
BA_ "GenSigInvalidValue" SG_ 384 SAS_SteeringAngle "32767";
BA_ "GenSigCycleTime" SG_ 384 SAS_CRCCheck 10;
BA_ "GenSigCycleTime" SG_ 384 SAS_RollingCounter 10;
BA_ "GenSigCycleTime" SG_ 384 SAS_SASFailure 10;
BA_ "GenSigInvalidValue" SG_ 384 SAS_SASFailure "1";
BA_ "GenSigCycleTime" SG_ 384 SAS_Calibrated 10;

BA_ "GenSigCycleTime" SG_ 800 GW_ResetReq 100;
BA_ "GenSigInvalidValue" SG_ 800 GW_ResetReq "127";
BA_ "GenSigCycleTime" SG_ 800 GW_OTAmode_Chks 100;
BA_ "GenSigInvalidValue" SG_ 800 GW_OTAmode_Chks "0";
BA_ "GenSigCycleTime" SG_ 800 GW_OTAmode_Cntr 100;
BA_ "GenSigInvalidValue" SG_ 800 GW_OTAmode_Cntr "0";
BA_ "GenSigCycleTime" SG_ 800 GW_OTAmode 100;
BA_ "GenSigInvalidValue" SG_ 800 GW_OTAmode "0";

BA_ "GenSigCycleTime" SG_ 1302 HU_LocalTimeValid 1000;
BA_ "GenSigInvalidValue" SG_ 1302 HU_LocalTimeValid "1";
BA_ "GenSigCycleTime" SG_ 1302 HU_LocalTimeSecond 1000;
BA_ "GenSigInvalidValue" SG_ 1302 HU_LocalTimeSecond "0";
BA_ "GenSigCycleTime" SG_ 1302 HU_LocalTimeMinute 1000;
BA_ "GenSigInvalidValue" SG_ 1302 HU_LocalTimeMinute "0";
BA_ "GenSigCycleTime" SG_ 1302 HU_LocalTimeHour 1000;
BA_ "GenSigInvalidValue" SG_ 1302 HU_LocalTimeHour "0";
BA_ "GenSigCycleTime" SG_ 1302 HU_LocalTimeDate 1000;
BA_ "GenSigStartValue" SG_ 1302 HU_LocalTimeDate 1.000000;
BA_ "GenSigInvalidValue" SG_ 1302 HU_LocalTimeDate "1";
BA_ "GenSigCycleTime" SG_ 1302 HU_LocalTimeMonth 1000;
BA_ "GenSigStartValue" SG_ 1302 HU_LocalTimeMonth 1.000000;
BA_ "GenSigInvalidValue" SG_ 1302 HU_LocalTimeMonth "1";
BA_ "GenSigCycleTime" SG_ 1302 HU_LocalTimeYear 1000;
BA_ "GenSigInvalidValue" SG_ 1302 HU_LocalTimeYear "0";

BA_ "GenSigCycleTime" SG_ 1328 IP_TotalOdometer 500;
BA_ "GenSigInvalidValue" SG_ 1328 IP_TotalOdometer "16777215";

BA_ "GenSigCycleTime" SG_ 349 ESP_CRCCheck_278 20;
BA_ "GenSigCycleTime" SG_ 349 ESP_RollingCounter_278 20;
BA_ "GenSigCycleTime" SG_ 349 ESP_IMUCalibrated 20;
BA_ "GenSigCycleTime" SG_ 349 ESP_YawRateValid 20;
BA_ "GenSigCycleTime" SG_ 349 ESP_YawRate 20;
BA_ "GenSigInvalidValue" SG_ 349 ESP_YawRate "16383";
BA_ "GenSigCycleTime" SG_ 349 ESP_LongAccelValid 20;
BA_ "GenSigCycleTime" SG_ 349 ESP_LongAccel 20;
BA_ "GenSigInvalidValue" SG_ 349 ESP_LongAccel "1023";
BA_ "GenSigCycleTime" SG_ 349 ESP_LatAccelValid 20;
BA_ "GenSigCycleTime" SG_ 349 ESP_LatAccel 20;
BA_ "GenSigInvalidValue" SG_ 349 ESP_LatAccel "255";

BA_ "GenSigCycleTime" SG_ 632 ESP_YawRateValid 20;
BA_ "GenSigCycleTime" SG_ 632 ESP_YawRate 20;
BA_ "GenSigInvalidValue" SG_ 632 ESP_YawRate "16383";
BA_ "GenSigCycleTime" SG_ 632 ESP_RollingCounter_278 20;
BA_ "GenSigCycleTime" SG_ 632 ESP_LongAccel 20;
BA_ "GenSigInvalidValue" SG_ 632 ESP_LongAccel "1023";
BA_ "GenSigCycleTime" SG_ 632 ESP_LatAccel 20;
BA_ "GenSigInvalidValue" SG_ 632 ESP_LatAccel "255";
BA_ "GenSigCycleTime" SG_ 632 ESP_CRCCheck_278 20;

BA_ "GenSigCycleTime" SG_ 378 ESP_TCSFailStatus 10;
BA_ "GenSigCycleTime" SG_ 378 ESP_ESPFunctionStatus 10;
BA_ "GenSigStartValue" SG_ 378 ESP_ESPFunctionStatus 1.000000;
BA_ "GenSigCycleTime" SG_ 378 ESP_ESPActiveStatus 10;
BA_ "GenSigCycleTime" SG_ 378 ESP_ABSFailStatus 10;
BA_ "GenSigCycleTime" SG_ 378 ESP_ABSActiveStatus 10;
BA_ "GenSigCycleTime" SG_ 378 ESP_VehicleSpeedValid 10;
BA_ "GenSigInvalidValue" SG_ 378 ESP_VehicleSpeedValid "1";
BA_ "GenSigCycleTime" SG_ 378 ESP_VehicleSpeed 10;
BA_ "GenSigInvalidValue" SG_ 378 ESP_VehicleSpeed "8191";

BA_ "GenSigCycleTime" SG_ 523 ESP_RollingCounter_20B 20;
BA_ "GenSigCycleTime" SG_ 523 ESP_CRCCheck_20B 20;
BA_ "GenSigCycleTime" SG_ 523 ESP_BrakeForce 20;
BA_ "GenSigCycleTime" SG_ 523 ESP_AEBdecActive 20;
BA_ "GenSigCycleTime" SG_ 523 ESP_AEBAvailable 20;
BA_ "GenSigCycleTime" SG_ 523 ESP_VDCActive 20;
BA_ "GenSigCycleTime" SG_ 523 ESP_TCSActive 20;
BA_ "GenSigCycleTime" SG_ 523 ESP_OnlyABSActive 20;
BA_ "GenSigCycleTime" SG_ 523 Wheel_Speed_RR_Valid_Data 20;
BA_ "GenSigInvalidValue" SG_ 523 Wheel_Speed_RR_Valid_Data "1";
BA_ "GenSigCycleTime" SG_ 523 Wheel_Speed_RR_Pulse 20;
BA_ "GenSigInvalidValue" SG_ 523 Wheel_Speed_RR_Pulse "255";
BA_ "GenSigCycleTime" SG_ 523 Wheel_Speed_RR_Direction 20;
BA_ "GenSigCycleTime" SG_ 523 Wheel_Speed_RR_Data 20;
BA_ "GenSigInvalidValue" SG_ 523 Wheel_Speed_RR_Data "8191";
BA_ "GenSigCycleTime" SG_ 523 Wheel_Speed_RL_Valid_Data 20;
BA_ "GenSigInvalidValue" SG_ 523 Wheel_Speed_RL_Valid_Data "1";
BA_ "GenSigCycleTime" SG_ 523 Wheel_Speed_RL_Pulse 20;
BA_ "GenSigInvalidValue" SG_ 523 Wheel_Speed_RL_Pulse "255";
BA_ "GenSigCycleTime" SG_ 523 Wheel_Speed_RL_Direction 20;
BA_ "GenSigInvalidValue" SG_ 523 Wheel_Speed_RL_Direction "3";
BA_ "GenSigCycleTime" SG_ 523 Wheel_Speed_RL_Data 20;
BA_ "GenSigInvalidValue" SG_ 523 Wheel_Speed_RL_Data "8191";
BA_ "GenSigCycleTime" SG_ 523 Wheel_Speed_FR_Valid_Data 20;
BA_ "GenSigInvalidValue" SG_ 523 Wheel_Speed_FR_Valid_Data "1";
BA_ "GenSigCycleTime" SG_ 523 Wheel_Speed_FR_Pulse 20;
BA_ "GenSigInvalidValue" SG_ 523 Wheel_Speed_FR_Pulse "255";
BA_ "GenSigCycleTime" SG_ 523 Wheel_Speed_FR_Direction 20;
BA_ "GenSigInvalidValue" SG_ 523 Wheel_Speed_FR_Direction "3";
BA_ "GenSigCycleTime" SG_ 523 Wheel_Speed_FR_Data 20;
BA_ "GenSigInvalidValue" SG_ 523 Wheel_Speed_FR_Data "8191";
BA_ "GenSigCycleTime" SG_ 523 Wheel_Speed_FL_Valid_Data 20;
BA_ "GenSigInvalidValue" SG_ 523 Wheel_Speed_FL_Valid_Data "1";
BA_ "GenSigCycleTime" SG_ 523 Wheel_Speed_FL_Pulse 20;
BA_ "GenSigInvalidValue" SG_ 523 Wheel_Speed_FL_Pulse "255";
BA_ "GenSigCycleTime" SG_ 523 Wheel_Speed_FL_Direction 20;
BA_ "GenSigInvalidValue" SG_ 523 Wheel_Speed_FL_Direction "3";
BA_ "GenSigCycleTime" SG_ 523 Wheel_Speed_FL_Data 20;
BA_ "GenSigInvalidValue" SG_ 523 Wheel_Speed_FL_Data "8191";
BA_ "GenSigCycleTime" SG_ 523 IBCU_BrkPedlStsGbVld 20;
BA_ "GenSigInvalidValue" SG_ 523 IBCU_BrkPedlStsGbVld "2";
BA_ "GenSigCycleTime" SG_ 523 IBCU_BrkPedoplStsGb 20;
BA_ "GenSigInvalidValue" SG_ 523 IBCU_BrkPedoplStsGb "255";
BA_ "GenSigCycleTime" SG_ 523 ESP_VehicleStandstillVld 20;
BA_ "GenSigCycleTime" SG_ 523 ESP_VehicleStandstill 20;

BA_ "GenSigCycleTime" SG_ 381 PCU_RollingCounter_17D 10;
BA_ "GenSigCycleTime" SG_ 381 PCU_CRCCheck_17D 10;
BA_ "GenSigCycleTime" SG_ 381 PCU_RealAccPedlVld 10;
BA_ "GenSigCycleTime" SG_ 381 PCU_RealAccPedl 10;

BA_ "GenSigCycleTime" SG_ 398 EMS_BrakePedalStatus 10;
BA_ "GenSigInvalidValue" SG_ 398 EMS_BrakePedalStatus "3";
BA_ "GenSigCycleTime" SG_ 398 EMS_RollingCounter_18E 10;
BA_ "GenSigCycleTime" SG_ 398 EMS_CRCCheck_18E 10;
BA_ "GenSigCycleTime" SG_ 398 EMS_RealAccPedal 10;
BA_ "GenSigInvalidValue" SG_ 398 EMS_RealAccPedal "255";

BA_ "GenSigCycleTime" SG_ 431 TCU_CRCCheck_1A8 10;
BA_ "GenSigCycleTime" SG_ 431 TCU_RollingCounter_1A8 10;
BA_ "GenSigCycleTime" SG_ 431 TCU_GearShiftPosition 10;
BA_ "GenSigStartValue" SG_ 431 TCU_GearShiftPosition 13.000000;
BA_ "GenSigInvalidValue" SG_ 431 TCU_GearShiftPosition "15";
BA_ "GenSigCycleTime" SG_ 431 TCU_ShiftPostionValid 10;
BA_ "GenSigInvalidValue" SG_ 431 TCU_ShiftPostionValid "1";

BA_ "GenSigCycleTime" SG_ 424 TCU_CRCCheck_1A8 10;
BA_ "GenSigCycleTime" SG_ 424 TCU_RollingCounter_1A8 10;
BA_ "GenSigCycleTime" SG_ 424 TCU_ActualGear 10;
BA_ "GenSigInvalidValue" SG_ 424 TCU_ActualGear "15";
BA_ "GenSigCycleTime" SG_ 424 TCU_ActualGearValid 10;
BA_ "GenSigInvalidValue" SG_ 424 TCU_ActualGearValid "1";
BA_ "GenSigCycleTime" SG_ 424 TCU_GearShiftPosition 10;
BA_ "GenSigStartValue" SG_ 424 TCU_GearShiftPosition 14.000000;
BA_ "GenSigInvalidValue" SG_ 424 TCU_GearShiftPosition "15";
BA_ "GenSigCycleTime" SG_ 424 TCU_ShiftPostionValid 10;
BA_ "GenSigInvalidValue" SG_ 424 TCU_ShiftPostionValid "1";

BA_ "GenSigCycleTime" SG_ 796 PCU_VcuRdySts 100;

BA_ "GenSigCycleTime" SG_ 651 BCM_CRCCheck_28B 40;
BA_ "GenSigCycleTime" SG_ 651 BCM_RollingCounter_28B 40;
BA_ "GenSigCycleTime" SG_ 651 BCM_TurnIndicatorLeft 40;
BA_ "GenSigInvalidValue" SG_ 651 BCM_TurnIndicatorLeft "3";
BA_ "GenSigCycleTime" SG_ 651 BCM_TurnIndicatorRight 40;
BA_ "GenSigInvalidValue" SG_ 651 BCM_TurnIndicatorRight "3";
BA_ "GenSigCycleTime" SG_ 651 BCM_TurnLightSwitchSts 40;
BA_ "GenSigInvalidValue" SG_ 651 BCM_TurnLightSwitchSts "3";
BA_ "GenSigCycleTime" SG_ 651 BCM_DriverDoorStatus 40;
BA_ "GenSigCycleTime" SG_ 651 BCM_PowerStatusFeedback 40;

BA_ "GenSigCycleTime" SG_ 271 IBCU_sOutputRodAct_Q 20;
BA_ "GenSigCycleTime" SG_ 271 IBCU_sOutputRodAct 20;

BA_ "GenSigCycleTime" SG_ 80 SRS_CRCCheck_50 500;
BA_ "GenSigCycleTime" SG_ 80 SRS_RollingCounter_id050 500;
BA_ "GenSigCycleTime" SG_ 80 SRS_PassengerBuckleSwitchStatus 500;
BA_ "GenSigCycleTime" SG_ 80 SRS_DriverBuckleSwitchStatus 500;

BA_ "GenSigCycleTime" SG_ 664 BCM_CRCCheck_298 40;
BA_ "GenSigCycleTime" SG_ 664 BCM_RollingCounter_298 40;
BA_ "GenSigCycleTime" SG_ 664 BCM_LeftRearDoorStatus 40;

BA_ "GenSigCycleTime" SG_ 721 BCM_RightRearDoorStatus 40;
BA_ "GenSigCycleTime" SG_ 721 BCM_PassengerDoorStatus 40;

BA_ "GenSigCycleTime" SG_ 587 Transmitcnt6_R 50;
BA_ "GenSigCycleTime" SG_ 587 Transmitcnt5_R 50;
BA_ "GenSigCycleTime" SG_ 587 Transmitcnt4_R 50;
BA_ "GenSigCycleTime" SG_ 587 Transmitcnt3_R 50;
BA_ "GenSigCycleTime" SG_ 587 Transmitcnt2_R 50;
BA_ "GenSigCycleTime" SG_ 587 Transmitcnt1_R 50;
BA_ "GenSigCycleTime" SG_ 587 RLR_Track_ID_R 50;
BA_ "GenSigInvalidValue" SG_ 587 RLR_Track_ID_R "NA";
BA_ "GenSigCycleTime" SG_ 587 RLR_Measured_R 50;
BA_ "GenSigInvalidValue" SG_ 587 RLR_Measured_R "NA";
BA_ "GenSigCycleTime" SG_ 587 RLR_Location_R 50;
BA_ "GenSigInvalidValue" SG_ 587 RLR_Location_R "NA";
BA_ "GenSigCycleTime" SG_ 587 RLR_ClassComfrmFlg_R 50;
BA_ "GenSigInvalidValue" SG_ 587 RLR_ClassComfrmFlg_R "NA";
BA_ "GenSigCycleTime" SG_ 587 RLR_TrckrType_R 50;
BA_ "GenSigInvalidValue" SG_ 587 RLR_TrckrType_R "NA";
BA_ "GenSigCycleTime" SG_ 587 RLR_TrckrAge_R 50;
BA_ "GenSigInvalidValue" SG_ 587 RLR_TrckrAge_R "NA";
BA_ "GenSigCycleTime" SG_ 587 RLR_MotionStatus_R 50;
BA_ "GenSigInvalidValue" SG_ 587 RLR_MotionStatus_R "NA";
BA_ "GenSigCycleTime" SG_ 587 RLR_AbsVy_R 50;
BA_ "GenSigInvalidValue" SG_ 587 RLR_AbsVy_R "NA";
BA_ "GenSigCycleTime" SG_ 587 RLR_AbsoVx_R 50;
BA_ "GenSigInvalidValue" SG_ 587 RLR_AbsoVx_R "NA";
BA_ "GenSigCycleTime" SG_ 587 RLR_LocDx_R 50;
BA_ "GenSigInvalidValue" SG_ 587 RLR_LocDx_R "NA";
BA_ "GenSigCycleTime" SG_ 587 RLR_LocDy_R 50;
BA_ "GenSigInvalidValue" SG_ 587 RLR_LocDy_R "NA";
BA_ "GenSigCycleTime" SG_ 587 RLR_HeadingAngle_R 50;
BA_ "GenSigInvalidValue" SG_ 587 RLR_HeadingAngle_R "NA";
BA_ "GenSigCycleTime" SG_ 587 RLR_Length_R 50;
BA_ "GenSigInvalidValue" SG_ 587 RLR_Length_R "NA";
BA_ "GenSigCycleTime" SG_ 587 RLR_Width_R 50;
BA_ "GenSigInvalidValue" SG_ 587 RLR_Width_R "NA";
BA_ "GenSigCycleTime" SG_ 587 RLR_Track_ID_L 50;
BA_ "GenSigInvalidValue" SG_ 587 RLR_Track_ID_L "NA";
BA_ "GenSigCycleTime" SG_ 587 RLR_Measured_L 50;
BA_ "GenSigInvalidValue" SG_ 587 RLR_Measured_L "NA";
BA_ "GenSigCycleTime" SG_ 587 RLR_Location_L 50;
BA_ "GenSigInvalidValue" SG_ 587 RLR_Location_L "NA";
BA_ "GenSigCycleTime" SG_ 587 RLR_ClassComfrmFlg_L 50;
BA_ "GenSigInvalidValue" SG_ 587 RLR_ClassComfrmFlg_L "NA";
BA_ "GenSigCycleTime" SG_ 587 RLR_TrckrType_L 50;
BA_ "GenSigInvalidValue" SG_ 587 RLR_TrckrType_L "NA";
BA_ "GenSigCycleTime" SG_ 587 RLR_TrckrAge_L 50;
BA_ "GenSigInvalidValue" SG_ 587 RLR_TrckrAge_L "NA";
BA_ "GenSigCycleTime" SG_ 587 RLR_MotionStatus_L 50;
BA_ "GenSigInvalidValue" SG_ 587 RLR_MotionStatus_L "NA";
BA_ "GenSigCycleTime" SG_ 587 RLR_AbsVy_L 50;
BA_ "GenSigInvalidValue" SG_ 587 RLR_AbsVy_L "NA";
BA_ "GenSigCycleTime" SG_ 587 RLR_AbsoVx_L 50;
BA_ "GenSigInvalidValue" SG_ 587 RLR_AbsoVx_L "NA";
BA_ "GenSigCycleTime" SG_ 587 RLR_LocDx_L 50;
BA_ "GenSigInvalidValue" SG_ 587 RLR_LocDx_L "NA";
BA_ "GenSigCycleTime" SG_ 587 RLR_LocDy_L 50;
BA_ "GenSigInvalidValue" SG_ 587 RLR_LocDy_L "NA";
BA_ "GenSigCycleTime" SG_ 587 RLR_HeadingAngle_L 50;
BA_ "GenSigInvalidValue" SG_ 587 RLR_HeadingAngle_L "NA";
BA_ "GenSigCycleTime" SG_ 587 RLR_Length_L 50;
BA_ "GenSigInvalidValue" SG_ 587 RLR_Length_L "NA";
BA_ "GenSigCycleTime" SG_ 587 RLR_Width_L 50;
BA_ "GenSigInvalidValue" SG_ 587 RLR_Width_L "NA";
BA_ "GenSigCycleTime" SG_ 587 RLR_TrckrNum 50;
BA_ "GenSigInvalidValue" SG_ 587 RLR_TrckrNum "NA";
BA_ "GenSigCycleTime" SG_ 587 RLR_TrackerTimeStamp 50;
BA_ "GenSigInvalidValue" SG_ 587 RLR_TrackerTimeStamp "NA";

BA_ "GenSigCycleTime" SG_ 1442 FLR_WakeUp_BYTE4BIT1 1000;
BA_ "GenSigCycleTime" SG_ 1442 FLR_WakeUp_BYTE4BIT0 1000;
BA_ "GenSigCycleTime" SG_ 1442 FLR_NotSleep_BYTE7BIT1 1000;
BA_ "GenSigCycleTime" SG_ 1442 FLR_NotSleep_BYTE7BIT0 1000;

BA_ "GenSigCycleTime" SG_ 1432 FRR_WakeUp_BYTE4BIT1 1000;
BA_ "GenSigCycleTime" SG_ 1432 FRR_WakeUp_BYTE4BIT0 1000;
BA_ "GenSigCycleTime" SG_ 1432 FRR_NotSleep_BYTE7BIT1 1000;
BA_ "GenSigCycleTime" SG_ 1432 FRR_NotSleep_BYTE7BIT0 1000;

BA_ "GenSigCycleTime" SG_ 1763 FLR_DTC2_Status 500;
BA_ "GenSigCycleTime" SG_ 1763 FLR_DTC2_LowByte 500;
BA_ "GenSigCycleTime" SG_ 1763 FLR_DTC2_MiddByte 500;
BA_ "GenSigCycleTime" SG_ 1763 FLR_DTC2_HighByte 500;
BA_ "GenSigCycleTime" SG_ 1763 FLR_DTC1_Status 500;
BA_ "GenSigCycleTime" SG_ 1763 FLR_DTC1_LowByte 500;
BA_ "GenSigCycleTime" SG_ 1763 FLR_DTC1_MiddByte 500;
BA_ "GenSigCycleTime" SG_ 1763 FLR_DTC1_HighByte 500;

BA_ "GenSigCycleTime" SG_ 1776 FRR_DTC2_Status 500;
BA_ "GenSigCycleTime" SG_ 1776 FRR_DTC2_LowByte 500;
BA_ "GenSigCycleTime" SG_ 1776 FRR_DTC2_MiddByte 500;
BA_ "GenSigCycleTime" SG_ 1776 FRR_DTC2_HighByte 500;
BA_ "GenSigCycleTime" SG_ 1776 FRR_DTC1_Status 500;
BA_ "GenSigCycleTime" SG_ 1776 FRR_DTC1_LowByte 500;
BA_ "GenSigCycleTime" SG_ 1776 FRR_DTC1_MiddByte 500;
BA_ "GenSigCycleTime" SG_ 1776 FRR_DTC1_HighByte 500;

BA_ "GenSigCycleTime" SG_ 623 FC_Line_4_exist_prob 30;
BA_ "GenSigCycleTime" SG_ 623 FC_Line_4_MeasureType 30;
BA_ "GenSigCycleTime" SG_ 623 FC_Line_4_ModelC3 30;
BA_ "GenSigStartValue" SG_ 623 FC_Line_4_ModelC3 2048.000000;
BA_ "GenSigCycleTime" SG_ 623 FC_Line_4_ModelC2 30;
BA_ "GenSigStartValue" SG_ 623 FC_Line_4_ModelC2 12288.000000;
BA_ "GenSigCycleTime" SG_ 623 FC_Line_4_ModelC1 30;
BA_ "GenSigStartValue" SG_ 623 FC_Line_4_ModelC1 3277.000000;
BA_ "GenSigCycleTime" SG_ 623 FC_Line_4_ModelC0 30;
BA_ "GenSigCycleTime" SG_ 623 FC_Line_4_dx_End 30;
BA_ "GenSigCycleTime" SG_ 623 FC_Line_4_dx_Start 30;
BA_ "GenSigCycleTime" SG_ 623 FC_Line_4_Id 30;
BA_ "GenSigStartValue" SG_ 623 FC_Line_4_Id 1.000000;
BA_ "GenSigCycleTime" SG_ 623 FC_Line_4_Type 30;
BA_ "GenSigCycleTime" SG_ 623 FC_Line_3_exist_prob 30;
BA_ "GenSigCycleTime" SG_ 623 FC_Line_3_MeasureType 30;
BA_ "GenSigCycleTime" SG_ 623 FC_Line_3_ModelC3 30;
BA_ "GenSigStartValue" SG_ 623 FC_Line_3_ModelC3 2048.000000;
BA_ "GenSigCycleTime" SG_ 623 FC_Line_3_ModelC2 30;
BA_ "GenSigStartValue" SG_ 623 FC_Line_3_ModelC2 12288.000000;
BA_ "GenSigCycleTime" SG_ 623 FC_Line_3_ModelC1 30;
BA_ "GenSigStartValue" SG_ 623 FC_Line_3_ModelC1 3277.000000;
BA_ "GenSigCycleTime" SG_ 623 FC_Line_3_ModelC0 30;
BA_ "GenSigCycleTime" SG_ 623 FC_Line_3_dx_End 30;
BA_ "GenSigCycleTime" SG_ 623 FC_Line_3_dx_Start 30;
BA_ "GenSigCycleTime" SG_ 623 FC_Line_3_Id 30;
BA_ "GenSigStartValue" SG_ 623 FC_Line_3_Id 1.000000;
BA_ "GenSigCycleTime" SG_ 623 FC_Line_3_Type 30;
BA_ "GenSigCycleTime" SG_ 623 FC_Line_2_exist_prob 30;
BA_ "GenSigCycleTime" SG_ 623 FC_Line_2_MeasureType 30;
BA_ "GenSigCycleTime" SG_ 623 FC_Line_2_ModelC3 30;
BA_ "GenSigStartValue" SG_ 623 FC_Line_2_ModelC3 2048.000000;
BA_ "GenSigCycleTime" SG_ 623 FC_Line_2_ModelC2 30;
BA_ "GenSigStartValue" SG_ 623 FC_Line_2_ModelC2 12288.000000;
BA_ "GenSigCycleTime" SG_ 623 FC_Line_2_ModelC1 30;
BA_ "GenSigStartValue" SG_ 623 FC_Line_2_ModelC1 3277.000000;
BA_ "GenSigCycleTime" SG_ 623 FC_Line_2_ModelC0 30;
BA_ "GenSigCycleTime" SG_ 623 FC_Line_2_dx_End 30;
BA_ "GenSigCycleTime" SG_ 623 FC_Line_2_dx_Start 30;
BA_ "GenSigCycleTime" SG_ 623 FC_Line_2_Id 30;
BA_ "GenSigStartValue" SG_ 623 FC_Line_2_Id 1.000000;
BA_ "GenSigCycleTime" SG_ 623 FC_Line_2_Type 30;
BA_ "GenSigCycleTime" SG_ 623 FC_Line_1_exist_prob 30;
BA_ "GenSigCycleTime" SG_ 623 FC_Line_1_MeasureType 30;
BA_ "GenSigCycleTime" SG_ 623 FC_Line_1_ModelC3 30;
BA_ "GenSigStartValue" SG_ 623 FC_Line_1_ModelC3 2048.000000;
BA_ "GenSigCycleTime" SG_ 623 FC_Line_1_ModelC2 30;
BA_ "GenSigStartValue" SG_ 623 FC_Line_1_ModelC2 12288.000000;
BA_ "GenSigCycleTime" SG_ 623 FC_Line_1_ModelC1 30;
BA_ "GenSigStartValue" SG_ 623 FC_Line_1_ModelC1 3277.000000;
BA_ "GenSigCycleTime" SG_ 623 FC_Line_1_ModelC0 30;
BA_ "GenSigCycleTime" SG_ 623 FC_Line_1_dx_End 30;
BA_ "GenSigCycleTime" SG_ 623 FC_Line_1_dx_Start 30;
BA_ "GenSigCycleTime" SG_ 623 FC_Line_1_Id 30;
BA_ "GenSigStartValue" SG_ 623 FC_Line_1_Id 1.000000;
BA_ "GenSigCycleTime" SG_ 623 FC_Line_1_Type 30;

BA_ "GenSigCycleTime" SG_ 697 RLR_CRCCheck_2B9 50;
BA_ "GenSigCycleTime" SG_ 697 RLR_RollingCounter_2B9 50;
BA_ "GenSigCycleTime" SG_ 697 FLR_OBJ32_Ax 50;
BA_ "GenSigCycleTime" SG_ 697 FLR_OBJ31_Ax 50;
BA_ "GenSigCycleTime" SG_ 697 FLR_OBJ30_Ax 50;
BA_ "GenSigCycleTime" SG_ 697 FLR_OBJ29_Ax 50;
BA_ "GenSigCycleTime" SG_ 697 FLR_OBJ28_Ax 50;
BA_ "GenSigCycleTime" SG_ 697 FLR_OBJ27_Ax 50;
BA_ "GenSigCycleTime" SG_ 697 FLR_OBJ26_Ax 50;
BA_ "GenSigCycleTime" SG_ 697 FLR_OBJ25_Ax 50;
BA_ "GenSigCycleTime" SG_ 697 FLR_OBJ24_Ax 50;
BA_ "GenSigCycleTime" SG_ 697 FLR_OBJ23_Ax 50;
BA_ "GenSigCycleTime" SG_ 697 FLR_OBJ22_Ax 50;
BA_ "GenSigCycleTime" SG_ 697 FLR_OBJ21_Ax 50;
BA_ "GenSigCycleTime" SG_ 697 FLR_OBJ20_Ax 50;
BA_ "GenSigCycleTime" SG_ 697 FLR_OBJ19_Ax 50;
BA_ "GenSigCycleTime" SG_ 697 FLR_OBJ18_Ax 50;
BA_ "GenSigCycleTime" SG_ 697 FLR_OBJ17_Ax 50;
BA_ "GenSigCycleTime" SG_ 697 FLR_OBJ16_Ax 50;
BA_ "GenSigCycleTime" SG_ 697 FLR_OBJ15_Ax 50;
BA_ "GenSigCycleTime" SG_ 697 FLR_OBJ14_Ax 50;
BA_ "GenSigCycleTime" SG_ 697 FLR_OBJ13_Ax 50;
BA_ "GenSigCycleTime" SG_ 697 FLR_OBJ12_Ax 50;
BA_ "GenSigCycleTime" SG_ 697 FLR_OBJ11_Ax 50;
BA_ "GenSigCycleTime" SG_ 697 FLR_OBJ10_Ax 50;
BA_ "GenSigCycleTime" SG_ 697 FLR_OBJ9_Ax 50;
BA_ "GenSigCycleTime" SG_ 697 FLR_OBJ8_Ax 50;
BA_ "GenSigCycleTime" SG_ 697 FLR_OBJ7_Ax 50;
BA_ "GenSigCycleTime" SG_ 697 FLR_OBJ6_Ax 50;
BA_ "GenSigCycleTime" SG_ 697 FLR_OBJ5_Ax 50;
BA_ "GenSigCycleTime" SG_ 697 FLR_OBJ4_Ax 50;
BA_ "GenSigCycleTime" SG_ 697 FLR_OBJ3_Ax 50;
BA_ "GenSigCycleTime" SG_ 697 FLR_OBJ2_Ax 50;
BA_ "GenSigCycleTime" SG_ 697 FLR_OBJ1_Ax 50;

BA_ "GenSigCycleTime" SG_ 957 HU_AsistantSysteSwitch 100;
BA_ "GenSigInvalidValue" SG_ 957 HU_AsistantSysteSwitch "0";

VAL_ 691 FRR_ResetSts 0 "Valid" 1 "GW╟ы╟є╕┤╬╗" 2 "╫╘╔э┼╨╢╧╕┤╬╗" 3 "▓╗┬·╫у╕┤╬╗╠ї╝■" 4 "Reserve" 7 "Invalid";
VAL_ 691 RealTimeCal_Status_FR 0 "╬┤┐к╩╝
0x1=┐к╩╝
0x2=│╔╣ж
0x3=╩з░▄
0x4= ╚╦╣д╚б╧√";
VAL_ 691 DiagCal_Status_FR 0 "╬┤┐к╩╝
0x1=┐к╩╝
0x2=│╔╣ж
0x3=╩з░▄
0x4= ╚╦╣д╚б╧√";
VAL_ 691 EolCal_Status_FR 0 "╬┤┐к╩╝
0x1=┐к╩╝
0x2=│╔╣ж
0x3=╩з░▄
0x4= ╚╦╣д╚б╧√";

VAL_ 338 ADR_TriggerEventReq 0 "";
VAL_ 338 ACC_AEBEnable 0 "off" 1 "on";
VAL_ 338 ACC_FCWSettingStatus 0 "early" 1 "normal" 2 "late" 3 "Off" 4 "Reserved";
VAL_ 338 ADC_SenceMode 0 "";

VAL_ 1308 AD_SYNC_Sync_Time 32 "SYNC. SyncTimeSec = 32bit LSB of the 48 bits Seconds part of the time" 40 "FUP.SyncTimeNSec = 32 bit time stamp in nanoseconds";
VAL_ 1308 AD_SYNC_UserByte_OVS_SGW 32 "SYNC.╙├╗з╫╘╢и╥х╩¤╛▌гм─м╚╧╬к0" 0 "0x28=FUP.";
VAL_ 1308 AD_SYNC_Type 32 "SYNC" 40 "FUP";

VAL_ 384 SAS_SteeringAngleValid 0 "Valid" 1 "Invalid";
VAL_ 384 SAS_SASFailure 0 "No Failure" 1 "Failure";
VAL_ 384 SAS_Calibrated 0 "Calibrated" 1 " Not Calibrated";

VAL_ 800 GW_ResetReq 0 "Valid" 1 "THU" 2 " AMP" 3 "ADS/ADC" 4 " FC/LAS" 5 "FR/ACC" 6 "FLR" 7 "FRR" 8 "RLR/LCDAL" 9 "RRR/LCDAR" 10 "LVSM" 11 "INS" 12 "APA" 13 "BCML/BCM" 14 "GW/BCMR" 15 "EMS" 16 "PCU" 17 "BMS" 18 "PEU" 19 "OBC" 20 "TCU" 21 "IPUMP" 22 "ACM" 23 "ESL" 24 "PTS" 25 "ESCL" 26 "TMS/AC" 27 "DKC/RFBT/BLEM" 28 "WLCM" 29 "EPBI" 30 "IBCU" 31 "RBM" 32 "EPS" 33 "EPS2" 34 "DSM" 35 "IP" 36 "SLCM" 37 "HUD" 38 "GPEU" 39 "PDU" 40 "RPEU" 41 "VMC" 43 "DPEU" 44 "NFC-Enter" 45 "PATC" 46 "VMC2" 47 "RCCS" 48 "TRM" 49 "PDCU" 50 "BDCR" 51 "mADC" 52 "EPB" 53 "EVCC" 54 "HLM" 55 "CTMU" 56 "HRM" 57 "RLM" 64 "Reserve" 127 "Invalid";
VAL_ 800 GW_OTAmode 0 "OTAinactive" 1 "OTAmode1-│╡─┌╔¤╝╢░▓╚л╓┤╨╨╓╨" 2 " OTAmode2-│╡═т╔¤╝╢░▓╚л╓┤╨╨╓╨" 3 "OTAmode3-Reserved" 4 "OTAmode4-│╡─┌╔¤╝╢╖╟░▓╚л╓┤╨╨╓╨" 5 "OTAmode5-│╡═т╔¤╝╢╖╟░▓╚л╓┤╨╨╓╨" 6 "OTAmode6-│╡─┌╔¤╝╢╠ї╝■╝ь▓т╓╨" 7 "OTAmode7-│╡═т╔¤╝╢╠ї╝■╝ь▓т╓╨" 7 "Reserved";

VAL_ 1302 HU_LocalTimeValid 0 "Valid" 1 "Not Valid";

VAL_ 349 ESP_IMUCalibrated 0 "Calibrated" 1 "Not Calibrated";
VAL_ 349 ESP_YawRateValid 0 "Initializing" 1 "Valid" 2 "Invalid" 3 "Reserved";
VAL_ 349 ESP_LongAccelValid 0 "Initializing" 1 "Valid" 2 "Invalid" 3 "Reserved";
VAL_ 349 ESP_LatAccelValid 0 "Initializing" 1 "Valid" 2 "Invalid" 3 "Reserved";

VAL_ 632 ESP_YawRateValid 0 "Valid" 1 "Invalid";

VAL_ 378 ESP_TCSFailStatus 0 "Noerror" 1 "Error";
VAL_ 378 ESP_ESPFunctionStatus 0 "OFF" 1 "ON";
VAL_ 378 ESP_ESPActiveStatus 0 "NotActive" 1 "Active";
VAL_ 378 ESP_ABSFailStatus 0 "Noerror" 1 "Error";
VAL_ 378 ESP_ABSActiveStatus 0 "NotActive" 1 "Active";
VAL_ 378 ESP_VehicleSpeedValid 0 "Valid" 1 "NotValid";
VAL_ 378 ESP_VehicleSpeed 0 "0~360km/h" 6401 "Reserved" 8191 "Invalid";

VAL_ 523 ESP_BrakeForce 0 "nobrakeforce" 1 "havebrakeforce";
VAL_ 523 ESP_AEBdecActive 0 "notactive" 1 "active";
VAL_ 523 ESP_AEBAvailable 0 "notavailable" 1 "available";
VAL_ 523 ESP_VDCActive 0 "NotActive" 1 "Active";
VAL_ 523 ESP_TCSActive 0 "NotActive" 1 "Active";
VAL_ 523 ESP_OnlyABSActive 0 "NotActive" 1 "Active";
VAL_ 523 Wheel_Speed_RR_Valid_Data 0 "Valid" 1 "NotValid";
VAL_ 523 Wheel_Speed_RR_Direction 0 "Forward" 1 "backward" 2 "Standstill" 3 "Invalid";
VAL_ 523 Wheel_Speed_RL_Valid_Data 0 "Valid" 1 "NotValid";
VAL_ 523 Wheel_Speed_RL_Direction 0 "Forward" 1 "backward" 2 "Standstill" 3 "Invalid";
VAL_ 523 Wheel_Speed_FR_Valid_Data 0 "Valid" 1 "NotValid";
VAL_ 523 Wheel_Speed_FR_Direction 0 "Forward" 1 "backward" 2 "Standstill" 3 "Invalid";
VAL_ 523 Wheel_Speed_FL_Valid_Data 0 "Valid" 1 "NotValid";
VAL_ 523 Wheel_Speed_FL_Direction 0 "Forward" 1 "backward" 2 "Standstill" 3 "Invalid";
VAL_ 523 IBCU_BrkPedlStsGbVld 0 "NotInitialized" 1 "Normal" 2 "Invalid";
VAL_ 523 IBCU_BrkPedoplStsGb 0 " ╓╞╢п╬┤▓╚╧┬" 101 " ╓╞╢п▓╚╧┬" 254 "╥ь│г";
VAL_ 523 ESP_VehicleStandstillVld 0 "valid" 1 "Invalid";
VAL_ 523 ESP_VehicleStandstill 0 "notstandstill" 1 "standstill";

VAL_ 381 PCU_RealAccPedlVld 1 "invalid" 0 "valid";

VAL_ 398 EMS_BrakePedalStatus 0 "NotPressed" 1 "Pressed" 2 "Reserved" 3 "Error";

VAL_ 431 TCU_GearShiftPosition 0 "Parking" 1 "Reverse" 2 "Neutral" 3 "D" 4 "D3" 5 "D2" 6 "L" 7 "M/S" 8 "Reserved" 13 " Initial value" 14 " Unreliable" 15 " Invalid";
VAL_ 431 TCU_ShiftPostionValid 0 "valid" 1 "invalid";

VAL_ 424 TCU_ActualGear 0 "Neutral" 1 "1stgear" 2 "2ndgear" 3 "3rdgear" 4 "4tgear" 5 "5tgear" 6 "6tgear" 7 "7tgear" 8 "8tgear" 9 "Reverse" 10 "Parking" 11 "Reserved" 12 "Reserved" 13 "Reserved" 14 "Reserved" 15 "Invalid";
VAL_ 424 TCU_ActualGearValid 0 "Valid" 1 "Invalid";
VAL_ 424 TCU_GearShiftPosition 0 "Parking" 1 "Reverse" 2 "Neutral" 3 "D" 4 "D3" 5 "D2" 6 "L" 7 "M_or_S" 8 "Reserved" 9 "Reserved" 10 "Reserved" 11 "Reserved" 12 "Reserved" 13 "Reserved" 14 "Unreliable" 15 "Invalid";
VAL_ 424 TCU_ShiftPostionValid 0 "Valid" 1 "Invalid";

VAL_ 796 PCU_VcuRdySts 0 "no Ready" 1 "Ready";

VAL_ 651 BCM_TurnIndicatorLeft 0 "OFF" 1 "ON" 2 "Not used" 3 "Error";
VAL_ 651 BCM_TurnIndicatorRight 0 "OFF" 1 "ON" 2 "Not used" 3 "Error";
VAL_ 651 BCM_TurnLightSwitchSts 0 "Not Actived" 1 "Left Actived" 2 "Right Actived" 3 "Invalid";
VAL_ 651 BCM_DriverDoorStatus 0 "Close" 1 "Open";
VAL_ 651 BCM_PowerStatusFeedback 0 "OFF" 1 "ACC" 2 "ON" 3 "Start";

VAL_ 271 IBCU_sOutputRodAct_Q 0 "SoutputRodAct_NotInitialized" 1 "SoutputRodAct_Normal" 2 "SoutputRodAct_Faulty";

VAL_ 80 SRS_CRCCheck_50 0 "0xFFгмXOR value=0xFFгмinput data reflected=NoгмResult data reflected=Noгмcheck=0x48гмMagic check=0xC4гй";
VAL_ 80 SRS_PassengerBuckleSwitchStatus 0 "Buckled" 1 "Unbuckle " 2 "Not Used" 3 "Not Used
Default value= 0x0";
VAL_ 80 SRS_DriverBuckleSwitchStatus 0 "Buckled" 1 "Unbuckle " 2 "Not Used" 3 "Not Used
Default value= 0x0";

VAL_ 664 BCM_LeftRearDoorStatus 0 "Close" 1 "Open";

VAL_ 721 BCM_RightRearDoorStatus 0 "Close" 1 "Open";
VAL_ 721 BCM_PassengerDoorStatus 0 "Close" 1 "Open";

VAL_ 587 RLR_Measured_R 0 "unknown" 1 "Measured" 2 "Predicted" 3 "Reserved";
VAL_ 587 RLR_Location_R 0 "unknown" 1 "Left Lane" 2 "Right  Lane" 3 "Ego Lane";
VAL_ 587 RLR_ClassComfrmFlg_R 0 "╬┤╚╖╚╧" 1 "╥╤╚╖╚╧;";
VAL_ 587 RLR_TrckrType_R 0 "Not Detected" 1 "car" 2 "truck" 3 "bicycle/motorbike" 4 "pedestrian" 5 "general" 6 "animal" 7 "uncertain";
VAL_ 587 RLR_MotionStatus_R 0 "unknown" 1 "moving " 2 "stopped" 3 "stationary" 4 "crossing" 5 "reserve;";
VAL_ 587 RLR_Measured_L 0 "unknown" 1 "Measured" 2 "Predicted" 3 "Reserved";
VAL_ 587 RLR_Location_L 0 "unknown" 1 "Left Lane" 2 "Right  Lane" 3 "Ego Lane";
VAL_ 587 RLR_ClassComfrmFlg_L 0 "╬┤╚╖╚╧" 1 "╥╤╚╖╚╧;";
VAL_ 587 RLR_TrckrType_L 0 "Not Detected" 1 "car" 2 "truck" 3 "bicycle/motorbike" 4 "pedestrian" 5 "general" 6 "animal" 7 "uncertain";
VAL_ 587 RLR_MotionStatus_L 0 "unknown" 1 "moving " 2 "stopped" 3 "stationary" 4 "crossing" 5 "reserve;";

VAL_ 1442 FLR_WakeUp_BYTE4BIT1 0 "Inactive" 1 " IG╗╜╨╤ги╚Ї▓╗╜╙IG╙▓╧▀╘Є╬▐┤╦╬╗гй";
VAL_ 1442 FLR_WakeUp_BYTE4BIT0 0 "Inactive" 1 " CAN═°┬ч╣▄└э▒и╬─╗╜╨╤";
VAL_ 1442 FLR_NotSleep_BYTE7BIT1 0 "Inactive" 1 " IGN╙▓╧▀╨┼║┼╬кON╡╡/╫▄╧▀╡ч╘┤╡▓╬╗╨┼║┼╖╟OFF";
VAL_ 1442 FLR_NotSleep_BYTE7BIT0 0 "Inactive" 1 " CAN═°┬ч╔╧╞ф╦√╜┌╡у▓╗╘╩╨э╨▌├▀";

VAL_ 1432 FRR_WakeUp_BYTE4BIT1 0 "Inactive" 1 " IG╗╜╨╤ги╚Ї▓╗╜╙IG╙▓╧▀╘Є╬▐┤╦╬╗гй";
VAL_ 1432 FRR_WakeUp_BYTE4BIT0 0 "Inactive" 1 " CAN═°┬ч╣▄└э▒и╬─╗╜╨╤";
VAL_ 1432 FRR_NotSleep_BYTE7BIT1 0 "Inactive" 1 " IGN╙▓╧▀╨┼║┼╬кON╡╡/╫▄╧▀╡ч╘┤╡▓╬╗╨┼║┼╖╟OFF";
VAL_ 1432 FRR_NotSleep_BYTE7BIT0 0 "Inactive" 1 " CAN═°┬ч╔╧╞ф╦√╜┌╡у▓╗╘╩╨э╨▌├▀";

VAL_ 623 FC_Line_4_MeasureType 0 "unknow" 1 "virtual_paral" 2 "measured_paral" 3 "virtual" 4 "measured";
VAL_ 623 FC_Line_4_Type 0 " solid" 1 "dashed" 2 "double_dashed_dashed" 3 "double_dashed_solid" 4 "double_ solid_ dashed" 5 "double_ solid_ solid" 6 " multipleгиEu&USAгй" 7 "multiple_warningгиEu&USAгй" 8 "car_pool" 9 "asphalt_jointгиUSAгй" 10 "Bot-DottгиUSAгй" 11 " road_edge" 12 "guardrail" 13 "curbstone" 14 "wall" 15 "traffic_cone" 16 "delineator_post" 17 "parking_car" 18 "unknown_raised" 19 "fishbone" 20 "unknown" 21 "line_diversion_inside" 22 "line_diversion_outside" 23 "line-ramp" 24 "reserved";
VAL_ 623 FC_Line_3_MeasureType 0 "unknow" 1 "virtual_paral" 2 "measured_paral" 3 "virtual" 4 "measured";
VAL_ 623 FC_Line_3_Type 0 " solid" 1 "dashed" 2 "double_dashed_dashed" 3 "double_dashed_solid" 4 "double_ solid_ dashed" 5 "double_ solid_ solid" 6 " multipleгиEu&USAгй" 7 "multiple_warningгиEu&USAгй" 8 "car_pool" 9 "asphalt_jointгиUSAгй" 10 "Bot-DottгиUSAгй" 11 " road_edge" 12 "guardrail" 13 "curbstone" 14 "wall" 15 "traffic_cone" 16 "delineator_post" 17 "parking_car" 18 "unknown_raised" 19 "fishbone" 20 "unknown" 21 "line_diversion_inside" 22 "line_diversion_outside" 23 "line-ramp" 24 "reserved";
VAL_ 623 FC_Line_2_MeasureType 0 "unknow" 1 "virtual_paral" 2 "measured_paral" 3 "virtual" 4 "measured";
VAL_ 623 FC_Line_2_Type 0 " solid" 1 "dashed" 2 "double_dashed_dashed" 3 "double_dashed_solid" 4 "double_ solid_ dashed" 5 "double_ solid_ solid" 6 " multipleгиEu&USAгй" 7 "multiple_warningгиEu&USAгй" 8 "car_pool" 9 "asphalt_jointгиUSAгй" 10 "Bot-DottгиUSAгй" 11 " road_edge" 12 "guardrail" 13 "curbstone" 14 "wall" 15 "traffic_cone" 16 "delineator_post" 17 "parking_car" 18 "unknown_raised" 19 "fishbone" 20 "unknown" 21 "line_diversion_inside" 22 "line_diversion_outside" 23 "line-ramp" 24 "reserved";
VAL_ 623 FC_Line_1_MeasureType 0 "unknow" 1 "virtual_paral" 2 "measured_paral" 3 "virtual" 4 "measured";
VAL_ 623 FC_Line_1_Type 0 " solid" 1 "dashed" 2 "double_dashed_dashed" 3 "double_dashed_solid" 4 "double_ solid_ dashed" 5 "double_ solid_ solid" 6 " multipleгиEu&USAгй" 7 "multiple_warningгиEu&USAгй" 8 "car_pool" 9 "asphalt_jointгиUSAгй" 10 "Bot-DottгиUSAгй" 11 " road_edge" 12 "guardrail" 13 "curbstone" 14 "wall" 15 "traffic_cone" 16 "delineator_post" 17 "parking_car" 18 "unknown_raised" 19 "fishbone" 20 "unknown" 21 "line_diversion_inside" 22 "line_diversion_outside" 23 "line-ramp" 24 "reserved";

VAL_ 957 HU_AsistantSysteSwitch 0 " inactive " 1 "╣╪▒╒" 2 "┐к╞Ї";
